VERSION ""

NS_ :

BS_:

BU_: TCU_TORQUE_CONVERTER HYDRONIC AFSS LOGBOX TCU_GWS500 TCU_RET DIAG_TOOL CTIS BC ECM_0x00 TCU ALTERNATOR CP6 CP10 _TESTER _TEMPLATE_RUx

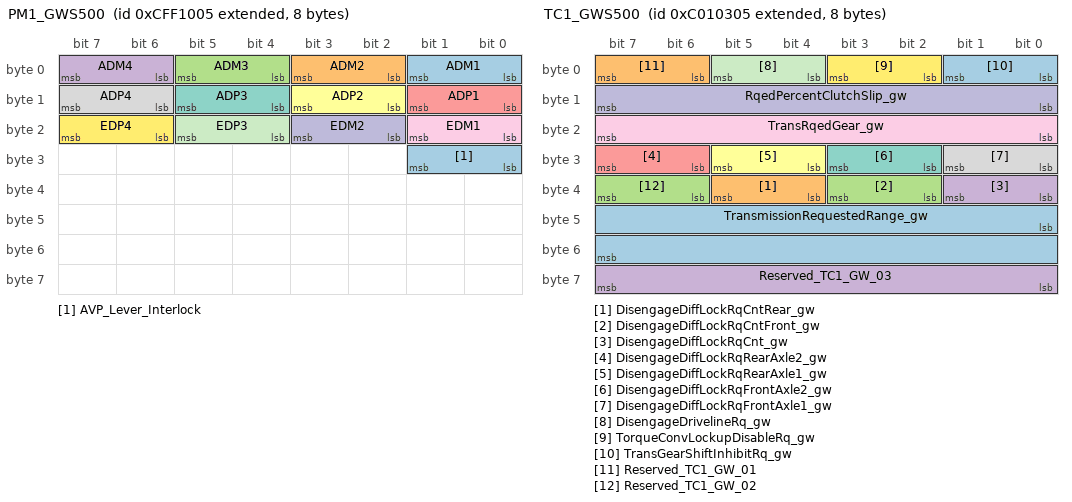
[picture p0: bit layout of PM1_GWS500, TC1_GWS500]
BO_ 2365526021 PM1_GWS500: 8 TCU_GWS500
 SG_ ADM1 : 0|2@1+ (1,0) [0|3] "-"  LOGBOX,TCU
 SG_ ADM2 : 2|2@1+ (1,0) [0|3] "-"  LOGBOX,TCU
 SG_ ADM3 : 4|2@1+ (1,0) [0|3] "-"  LOGBOX,TCU
 SG_ ADM4 : 6|2@1+ (1,0) [0|3] "-"  LOGBOX,TCU
 SG_ ADP1 : 8|2@1+ (1,0) [0|3] "-"  LOGBOX,TCU
 SG_ ADP2 : 10|2@1+ (1,0) [0|3] "-"  LOGBOX,TCU
 SG_ ADP3 : 12|2@1+ (1,0) [0|3] "-"  LOGBOX,TCU
 SG_ ADP4 : 14|2@1+ (1,0) [0|3] "-"  LOGBOX,TCU
 SG_ EDM1 : 16|2@1+ (1,0) [0|3] "-"  LOGBOX,TCU
 SG_ EDM2 : 18|2@1+ (1,0) [0|3] "-"  LOGBOX,TCU
 SG_ EDP3 : 20|2@1+ (1,0) [0|3] "-"  LOGBOX,TCU
 SG_ EDP4 : 22|2@1+ (1,0) [0|3] "-"  LOGBOX,TCU
 SG_ AVP_Lever_Interlock : 24|2@1+ (1,0) [0|3] "-"  CP6,CP10,LOGBOX,TCU

BO_ 2348876549 TC1_GWS500: 8 TCU_GWS500
 SG_ TransmissionRequestedRange_gw : 40|16@1+ (1,0) [0|65536] "-"  LOGBOX,TCU
 SG_ DisengageDiffLockRqCntRear_gw : 36|2@1+ (1,0) [0|3] "-"  LOGBOX,TCU
 SG_ DisengageDiffLockRqCntFront_gw : 34|2@1+ (1,0) [0|3] "-"  LOGBOX,TCU
 SG_ DisengageDiffLockRqCnt_gw : 32|2@1+ (1,0) [0|3] "-"  LOGBOX,TCU
 SG_ DisengageDiffLockRqRearAxle2_gw : 30|2@1+ (1,0) [0|3] "-"  LOGBOX,TCU
 SG_ DisengageDiffLockRqRearAxle1_gw : 28|2@1+ (1,0) [0|3] "-"  LOGBOX,TCU
 SG_ DisengageDiffLockRqFrontAxle2_gw : 26|2@1+ (1,0) [0|3] "-"  LOGBOX,TCU
 SG_ DisengageDiffLockRqFrontAxle1_gw : 24|2@1+ (1,0) [0|3] "-"  LOGBOX,TCU
 SG_ TransRqedGear_gw : 16|8@1+ (1,-125) [-125|125] "-"  LOGBOX,TCU,CP6,CP10
 SG_ RqedPercentClutchSlip_gw : 8|8@1+ (0.4,0) [0|100] "%"  LOGBOX,TCU
 SG_ DisengageDrivelineRq_gw : 4|2@1+ (1,0) [0|3] "-"  LOGBOX,TCU
 SG_ TorqueConvLockupDisableRq_gw : 2|2@1+ (1,0) [0|3] "-"  LOGBOX,TCU
 SG_ TransGearShiftInhibitRq_gw : 0|2@1+ (1,0) [0|3] "-"  LOGBOX,TCU
 SG_ Reserved_TC1_GW_01 : 6|2@1+ (1,0) [0|0] "-"  LOGBOX,TCU
 SG_ Reserved_TC1_GW_02 : 38|2@1+ (1,0) [0|0] "-"  LOGBOX,TCU
 SG_ Reserved_TC1_GW_03 : 56|8@1+ (1,0) [0|0] "-"  LOGBOX,TCU

BO_ 2348876577 TC1_BODY: 8 BC
 SG_ TransMode4_bc : 46|2@1+ (1,0) [0|3] "-"  LOGBOX,TCU
 SG_ TransMode3_bc : 44|2@1+ (1,0) [0|3] "-"  LOGBOX,TCU
 SG_ TransMode2_bc : 42|2@1+ (1,0) [0|3] "-"  LOGBOX,TCU
 SG_ TransMode1_bc : 40|2@1+ (1,0) [0|3] "-"  LOGBOX,TCU
 SG_ DisengageDiffLockRqCntRear_bc : 36|2@1+ (1,0) [0|3] "-"  LOGBOX,TCU
 SG_ DisengageDiffLockRqCntFront_bc : 34|2@1+ (1,0) [0|3] "-"  LOGBOX,TCU
 SG_ DisengageDiffLockRqCnt_bc : 32|2@1+ (1,0) [0|3] "-"  LOGBOX,TCU
 SG_ DisengageDiffLockRqRearAxle2_bc : 30|2@1+ (1,0) [0|3] "-"  LOGBOX,TCU
 SG_ DisengageDiffLockRqRearAxle1_bc : 28|2@1+ (1,0) [0|3] "-"  LOGBOX,TCU
 SG_ DisengageDiffLockRqFrontAxle2_bc : 26|2@1+ (1,0) [0|3] "-"  LOGBOX,TCU
 SG_ DisengageDiffLockRqFrontAxle1_bc : 24|2@1+ (1,0) [0|3] "-"  LOGBOX,TCU
 SG_ TransRqedGear_bc : 16|8@1+ (1,-125) [-125|125] "-"  LOGBOX,TCU
 SG_ RqedPercentClutchSlip_bc : 8|8@1+ (0.4,0) [0|100] "%"  LOGBOX,TCU
 SG_ DisengageDrivelineRq_bc : 4|2@1+ (1,0) [0|3] "-"  LOGBOX,TCU
 SG_ TorqueConvLockupDisableRq_bc : 2|2@1+ (1,0) [0|3] "-"  LOGBOX,TCU
 SG_ TransGearShiftInhibitRq_bc : 0|2@1+ (1,0) [0|3] "-"  LOGBOX,TCU
 SG_ Reserved_TC1_BC_01 : 6|2@1+ (1,0) [0|0] "-"  LOGBOX,TCU
 SG_ Reserved_TC1_BC_02 : 38|2@1+ (1,0) [0|0] "-"  LOGBOX,TCU
 SG_ Reserved_TC1_BC_03 : 48|6@1+ (1,0) [0|0] "-"  LOGBOX,TCU
 SG_ TransmissionShift : 54|2@1+ (1,0) [0|0] "-"  LOGBOX,TCU
 SG_ Reserved_TC1_BC_04 : 56|8@1+ (1,0) [0|0] "-"  LOGBOX,TCU

BO_ 2566803994 ALT_CURRENT: 8 ALTERNATOR
 SG_ Alt_Current : 0|16@1+ (0.05,-1600) [-1600|1600] "A"  LOGBOX

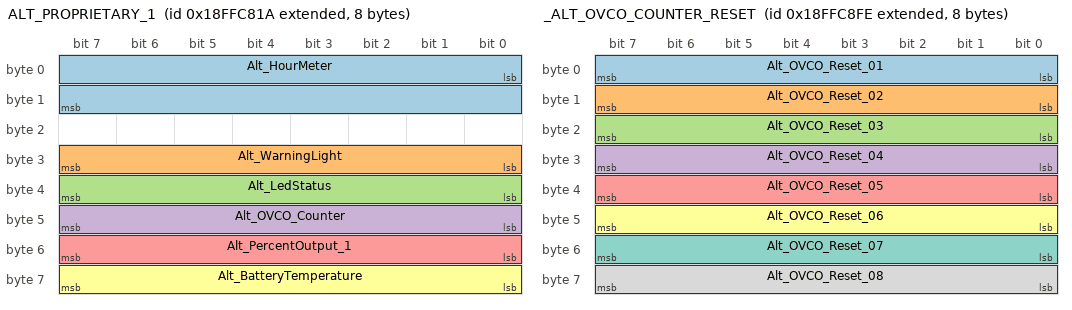
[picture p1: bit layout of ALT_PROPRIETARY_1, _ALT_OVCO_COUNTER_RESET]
BO_ 2566899738 ALT_PROPRIETARY_1: 8 ALTERNATOR
 SG_ Alt_HourMeter : 0|16@1+ (1,-32127) [-32127|33408] "h"  BC,LOGBOX
 SG_ Alt_WarningLight : 24|8@1+ (1,0) [252|253] "-"  BC,LOGBOX
 SG_ Alt_LedStatus : 32|8@1+ (1,0) [1|4] "-"  BC,LOGBOX
 SG_ Alt_OVCO_Counter : 40|8@1+ (1,0) [0|255] "-"  BC,LOGBOX
 SG_ Alt_PercentOutput_1 : 48|8@1+ (1,0) [0|100] "%"  BC,LOGBOX
 SG_ Alt_BatteryTemperature : 56|8@1+ (1,-40) [-40|210] "°C"  BC,LOGBOX

BO_ 2566837530 ALT_SPEED: 8 ALTERNATOR
 SG_ Alt_Speed_1 : 0|16@1+ (0.5,0) [0|32000] "rpm"  BC,LOGBOX

BO_ 2566899966 _ALT_OVCO_COUNTER_RESET: 8 _TESTER
 SG_ Alt_OVCO_Reset_01 : 0|8@1+ (1,0) [26|26] "-"  ALTERNATOR,LOGBOX
 SG_ Alt_OVCO_Reset_02 : 8|8@1+ (1,0) [43|43] "-"  ALTERNATOR,LOGBOX
 SG_ Alt_OVCO_Reset_03 : 16|8@1+ (1,0) [0|255] "-"  ALTERNATOR,LOGBOX
 SG_ Alt_OVCO_Reset_04 : 24|8@1+ (1,0) [0|255] "-"  ALTERNATOR,LOGBOX
 SG_ Alt_OVCO_Reset_05 : 32|8@1+ (1,0) [0|255] "-"  ALTERNATOR,LOGBOX
 SG_ Alt_OVCO_Reset_06 : 40|8@1+ (1,0) [255|255] "-"  ALTERNATOR,LOGBOX
 SG_ Alt_OVCO_Reset_07 : 48|8@1+ (1,0) [255|255] "-"  ALTERNATOR,LOGBOX
 SG_ Alt_OVCO_Reset_08 : 56|8@1+ (1,0) [255|255] "-"  ALTERNATOR,LOGBOX

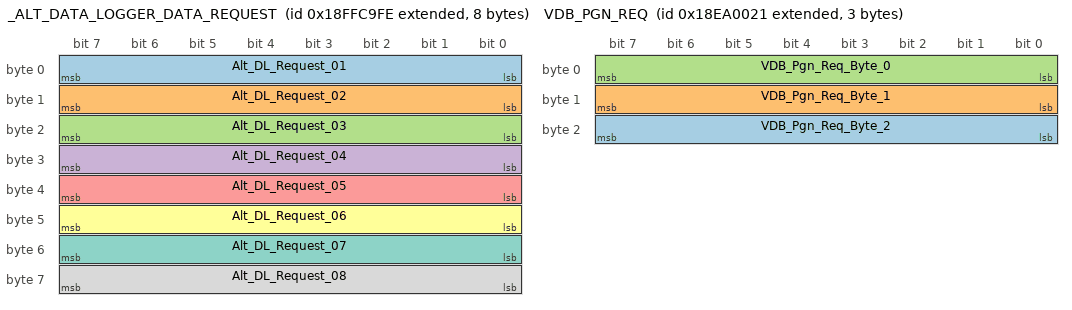
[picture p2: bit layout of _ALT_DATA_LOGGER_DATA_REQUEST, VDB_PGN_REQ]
BO_ 2566900222 _ALT_DATA_LOGGER_DATA_REQUEST: 8 _TESTER
 SG_ Alt_DL_Request_01 : 0|8@1+ (1,0) [26|26] "-"  ALTERNATOR,LOGBOX
 SG_ Alt_DL_Request_02 : 8|8@1+ (1,0) [43|43] "-"  ALTERNATOR,LOGBOX
 SG_ Alt_DL_Request_03 : 16|8@1+ (1,0) [0|255] "-"  ALTERNATOR,LOGBOX
 SG_ Alt_DL_Request_04 : 24|8@1+ (1,0) [0|255] "-"  ALTERNATOR,LOGBOX
 SG_ Alt_DL_Request_05 : 32|8@1+ (1,0) [0|255] "-"  ALTERNATOR,LOGBOX
 SG_ Alt_DL_Request_06 : 40|8@1+ (1,0) [255|255] "-"  ALTERNATOR,LOGBOX
 SG_ Alt_DL_Request_07 : 48|8@1+ (1,0) [255|255] "-"  ALTERNATOR,LOGBOX
 SG_ Alt_DL_Request_08 : 56|8@1+ (1,0) [255|255] "-"  ALTERNATOR,LOGBOX

BO_ 2566900723 ALT_VOLTAGE_REQUEST: 8 BC
 SG_ Alt_Set_Point_Request : 48|16@1+ (0.05,0) [0|32] "-"  ALTERNATOR,LOGBOX

BO_ 2565472289 VDB_PGN_REQ: 3 BC
 SG_ VDB_Pgn_Req_Byte_2 : 16|8@1+ (1,0) [0|255] "-"  LOGBOX,ECM_0x00
 SG_ VDB_Pgn_Req_Byte_1 : 8|8@1+ (1,0) [0|255] "-"  LOGBOX,ECM_0x00
 SG_ VDB_Pgn_Req_Byte_0 : 0|8@1+ (1,0) [0|255] "-"  LOGBOX,ECM_0x00

BO_ 2633922849 TP2_BODY: 8 BC
 SG_ Selected_Load_Mode_TP2_BODY : 56|3@1+ (1,0) [0|7] "-"  CTIS,LOGBOX
 SG_ Selected_Terrain_Mode_TP2_BODY : 48|3@1+ (1,0) [0|7] "-"  CTIS,LOGBOX

BO_ 2633922593 TP1_BODY: 8 BC
 SG_ TirePressCheckInterval_TP1_BODY : 0|8@1+ (1,0) [0|250] "-"  CTIS,LOGBOX

BO_ 2564489201 DIAG_REQ: 8 DIAG_TOOL
 SG_ DIAG_PHYS_REQUEST_DATA : 0|64@1+ (1,0) [0|0] "-"  LOGBOX,TCU

BO_ 2566841600 HOURS: 8 ECM_0x00
 SG_ EngTotalRevolutions : 32|32@1+ (1000,0) [0|4211081215000] "rpm"  BC,LOGBOX
 SG_ EngTotalHoursOfOperation : 0|32@1+ (0.05,0) [0|210554060.75] "hr"  BC,LOGBOX,CP10,CP6

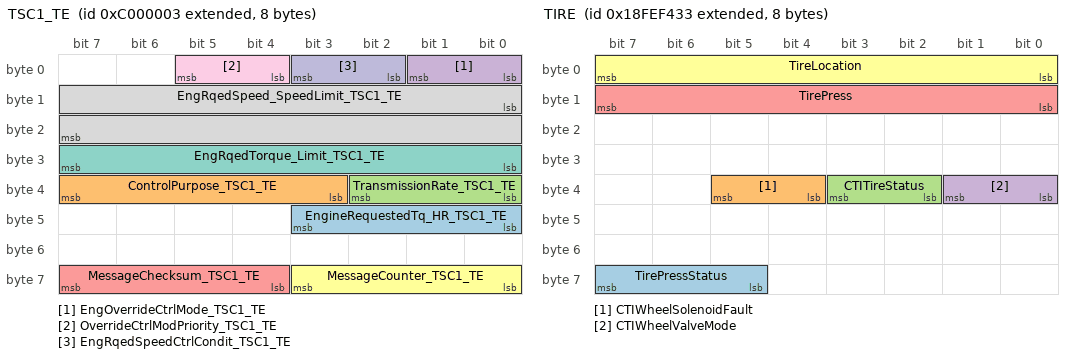
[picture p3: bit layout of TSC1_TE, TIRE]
BO_ 2348810243 TSC1_TE: 8 TCU
 SG_ EngineRequestedTq_HR_TSC1_TE : 40|4@1+ (1,0) [0|15] "-"  LOGBOX
 SG_ ControlPurpose_TSC1_TE : 35|5@1+ (1,0) [0|31] "-"  LOGBOX
 SG_ TransmissionRate_TSC1_TE : 32|3@1+ (1,0) [0|7] "-"  LOGBOX
 SG_ EngOverrideCtrlMode_TSC1_TE : 0|2@1+ (1,0) [0|3] "-"  LOGBOX
 SG_ MessageChecksum_TSC1_TE : 60|4@1+ (1,0) [0|15] "unit"  LOGBOX,ECM_0x00
 SG_ MessageCounter_TSC1_TE : 56|4@1+ (1,0) [0|15] "-"  LOGBOX
 SG_ EngRqedTorque_Limit_TSC1_TE : 24|8@1+ (1,-125) [-125|125] "%"  LOGBOX,ECM_0x00
 SG_ EngRqedSpeed_SpeedLimit_TSC1_TE : 8|16@1+ (0.125,0) [0|8031.875] "rpm"  LOGBOX,ECM_0x00
 SG_ OverrideCtrlModPriority_TSC1_TE : 4|2@1+ (1,0) [0|3] "-"  LOGBOX,ECM_0x00
 SG_ EngRqedSpeedCtrlCondit_TSC1_TE : 2|2@1+ (1,0) [0|3] "-"  LOGBOX,ECM_0x00

BO_ 2633923123 TP3_CTIS: 8 CTIS
 SG_ Current_Load_Mode : 56|3@1+ (1,0) [0|7] "-"  BC,LOGBOX
 SG_ Current_Terrain_Mode : 48|3@1+ (1,0) [0|7] "-"  BC,LOGBOX

BO_ 2633922867 TP2_CTIS: 8 CTIS
 SG_ Selected_Load_Mode_TP2 : 56|3@1+ (1,0) [0|7] "-"  BC,LOGBOX
 SG_ Selected_Terrain_Mode_TP2 : 48|3@1+ (1,0) [0|7] "-"  BC,LOGBOX

BO_ 2633922611 TP1_CTIS: 8 CTIS
 SG_ CTISProcessMode : 8|4@1+ (1,0) [0|15] "-"  BC,LOGBOX
 SG_ TirePressCheckInterval_TP1 : 0|8@1+ (1,0) [0|250] "-"  BC,LOGBOX

BO_ 2566845491 TIRE: 8 CTIS
 SG_ TirePressStatus : 61|3@1+ (1,0) [0|7] "-"  LOGBOX
 SG_ CTIWheelSolenoidFault : 36|2@1+ (1,0) [0|3] "-"  LOGBOX
 SG_ CTITireStatus : 34|2@1+ (1,0) [0|3] "-"  LOGBOX
 SG_ CTIWheelValveMode : 32|2@1+ (1,0) [0|3] "-"  LOGBOX
 SG_ TirePress : 8|8@1+ (5,0) [0|1250] "kPa"  LOGBOX
 SG_ TireLocation : 0|8@1+ (1,0) [0|255] "-"  LOGBOX

BO_ 2365484270 TCO1: 8 BC
 SG_ TachographVehicleSpeed : 48|16@1+ (0.00390625,0) [0|250.996] "km/h"  CP6,CP10,LOGBOX,ECM_0x00
 SG_ TachographOutputShaftSpeed : 32|16@1+ (0.125,0) [0|8031.875] "rpm"  LOGBOX

BO_ 2566840835 TCFG: 16 TCU
 SG_ TransGearRatio_6 : 112|16@1+ (0.001,0) [0|64.255] "-"  LOGBOX
 SG_ TransGearRatio_5 : 96|16@1+ (0.001,0) [0|64.255] "-"  LOGBOX
 SG_ TransGearRatio_4 : 80|16@1+ (0.001,0) [0|64.255] "-"  LOGBOX
 SG_ TransGearRatio_3 : 64|16@1+ (0.001,0) [0|64.255] "-"  LOGBOX
 SG_ TransGearRatio_2 : 48|16@1+ (0.001,0) [0|64.255] "-"  LOGBOX
 SG_ TransGearRatio_1 : 32|16@1+ (0.001,0) [0|64.255] "-"  LOGBOX
 SG_ TransGearRatio_0 : 16|16@1+ (0.001,0) [0|64.255] "-"  LOGBOX
 SG_ NumberOfForwardGearRatios : 8|8@1+ (1,0) [0|250] "-"  LOGBOX
 SG_ NumberOfReverseGearRatios : 0|8@1+ (1,0) [0|250] "-"  LOGBOX

BO_ 2566847248 RF: 8 TCU_RET
 SG_ HydRetarderOilTemp : 8|8@1+ (1,-40) [-40|210] "°C"  BC,LOGBOX
 SG_ HydRetarderPress : 0|8@1+ (16,0) [0|4000] "kPa"  LOGBOX

BO_ 2566840592 RC: 19 TCU_RET
 SG_ PercentTorqueAtPeakTorquePoint5 : 144|8@1+ (1,-125) [-125|125] "%"  LOGBOX
 SG_ ReferenceRetarderTorque : 128|16@1+ (1,0) [0|64255] "Nm"  LOGBOX
 SG_ RetarderSpeedAtPeakTorquePoint5 : 112|16@1+ (0.125,0) [0|8031.875] "rpm"  LOGBOX
 SG_ PercentTorqueAtPoint4 : 104|8@1+ (1,-125) [-125|125] "%"  LOGBOX
 SG_ RetarderSpeedAtPoint4 : 88|16@1+ (0.125,0) [0|8031.875] "rpm"  LOGBOX
 SG_ PercentTorqueAtPoint3 : 80|8@1+ (1,-125) [-125|125] "%"  LOGBOX
 SG_ RetarderSpeedAtPoint3 : 64|16@1+ (0.125,0) [0|8031.875] "rpm"  LOGBOX
 SG_ PercentTorqueAtMaxSpeedPoint2 : 56|8@1+ (1,-125) [-125|125] "%"  LOGBOX
 SG_ MaxRetarderSpeedPoint2 : 40|16@1+ (0.125,0) [0|8031.875] "rpm"  LOGBOX
 SG_ PercentTorqueAtIdlePoint1 : 32|8@1+ (1,-125) [-125|125] "%"  LOGBOX
 SG_ RetarderSpeedAtIdlePoint1 : 16|16@1+ (0.125,0) [0|8031.875] "rpm"  LOGBOX
 SG_ RetarderCtrlMethod : 8|8@1+ (1,0) [0|250] "steps"  LOGBOX
 SG_ RetarderLocation : 4|4@1+ (1,0) [0|15] "-"  LOGBOX
 SG_ RetarderType : 0|4@1+ (1,0) [0|15] "-"  LOGBOX

BO_ 2566844928 LFE1: 8 ECM_0x00
 SG_ EngInstantaneousFuelEconomy : 16|16@1+ (0.001953125,0) [0|125.5] "km/L"  BC,LOGBOX
 SG_ EngFuelRate : 0|16@1+ (0.05,0) [0|3212.75] "L/h"  BC,LOGBOX

BO_ 2566842624 LFC: 8 ECM_0x00
 SG_ EngTotalFuelUsed : 32|32@1+ (0.5,0) [0|2105540607.5] "L"  LOGBOX

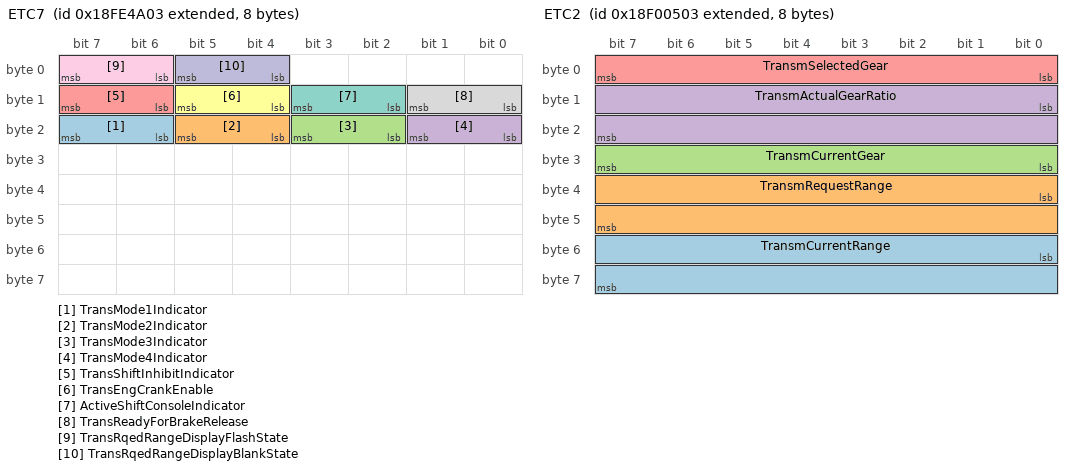
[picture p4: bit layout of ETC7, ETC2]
BO_ 2566801923 ETC7: 8 TCU
 SG_ TransMode1Indicator : 22|2@1+ (1,0) [0|3] "-"  BC,LOGBOX
 SG_ TransMode2Indicator : 20|2@1+ (1,0) [0|3] "-"  BC,LOGBOX
 SG_ TransMode3Indicator : 18|2@1+ (1,0) [0|3] "-"  BC,LOGBOX
 SG_ TransMode4Indicator : 16|2@1+ (1,0) [0|3] "-"  BC,LOGBOX
 SG_ TransShiftInhibitIndicator : 14|2@1+ (1,0) [0|3] "-"  BC,LOGBOX
 SG_ TransEngCrankEnable : 12|2@1+ (1,0) [0|3] "-"  BC,LOGBOX
 SG_ ActiveShiftConsoleIndicator : 10|2@1+ (1,0) [0|3] "-"  BC,LOGBOX
 SG_ TransReadyForBrakeRelease : 8|2@1+ (1,0) [0|3] "-"  BC,LOGBOX
 SG_ TransRqedRangeDisplayFlashState : 6|2@1+ (1,0) [0|3] "-"  BC,LOGBOX
 SG_ TransRqedRangeDisplayBlankState : 4|2@1+ (1,0) [0|3] "-"  BC,LOGBOX

BO_ 2565866755 ETC2: 8 TCU
 SG_ TransmCurrentRange : 48|16@1+ (1,0) [0|255] "-"  BC,LOGBOX
 SG_ TransmRequestRange : 32|16@1+ (1,0) [0|255] "-"  BC,LOGBOX
 SG_ TransmCurrentGear : 24|8@1+ (1,-125) [-125|125] "-"  BC,CP6,CP10,LOGBOX,ECM_0x00
 SG_ TransmActualGearRatio : 8|16@1+ (0.001,0) [0|64.255] "-"  BC,LOGBOX,ECM_0x00
 SG_ TransmSelectedGear : 0|8@1+ (1,-125) [-125|125] "-"  BC,LOGBOX,ECM_0x00

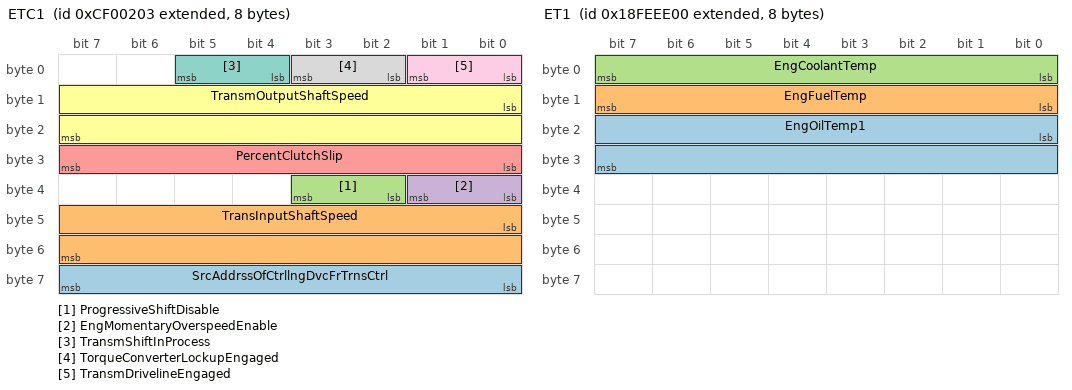
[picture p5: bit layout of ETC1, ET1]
BO_ 2364539395 ETC1: 8 TCU
 SG_ SrcAddrssOfCtrllngDvcFrTrnsCtrl : 56|8@1+ (1,0) [0|255] "-"  BC,LOGBOX
 SG_ TransInputShaftSpeed : 40|16@1+ (0.125,0) [0|8031.875] "rpm"  BC,LOGBOX
 SG_ ProgressiveShiftDisable : 34|2@1+ (1,0) [0|3] "-"  BC,LOGBOX
 SG_ EngMomentaryOverspeedEnable : 32|2@1+ (1,0) [0|3] "-"  BC,LOGBOX,ECM_0x00
 SG_ PercentClutchSlip : 24|8@1+ (0.4,0) [0|100] "%"  BC,LOGBOX
 SG_ TransmOutputShaftSpeed : 8|16@1+ (0.125,0) [0|8031.875] "rpm"  BC,LOGBOX,ECM_0x00
 SG_ TransmShiftInProcess : 4|2@1+ (1,0) [0|3] "-"  BC,LOGBOX,ECM_0x00
 SG_ TorqueConverterLockupEngaged : 2|2@1+ (1,0) [0|3] "-"  BC,LOGBOX,ECM_0x00
 SG_ TransmDrivelineEngaged : 0|2@1+ (1,0) [0|3] "-"  BC,LOGBOX,ECM_0x00

BO_ 2566843904 ET1: 8 ECM_0x00
 SG_ EngOilTemp1 : 16|16@1+ (0.03125,-273) [-273|1735] "°C"  CP6,CP10,LOGBOX
 SG_ EngFuelTemp : 8|8@1+ (1,-40) [-40|210] "°C"  CP6,CP10,BC,LOGBOX
 SG_ EngCoolantTemp : 0|8@1+ (1,-40) [-40|210] "°C"  BC,LOGBOX,TCU,CP6,CP10

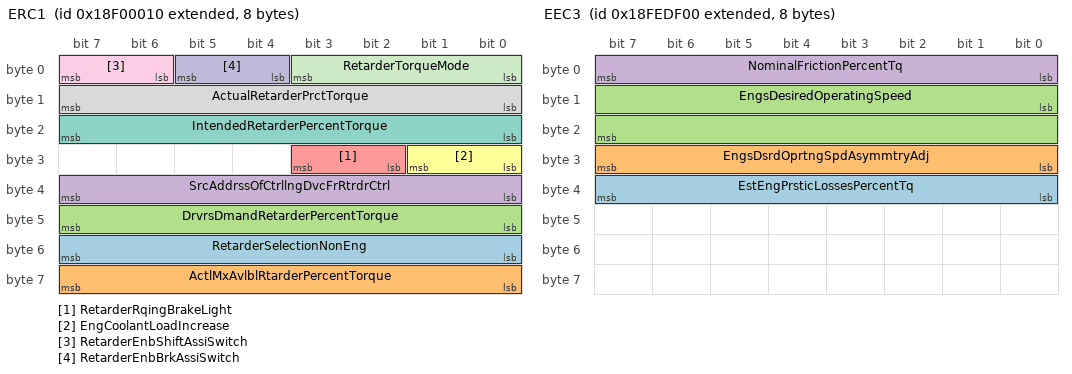
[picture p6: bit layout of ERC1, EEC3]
BO_ 2565865488 ERC1: 8 TCU_RET
 SG_ RetarderSelectionNonEng : 48|8@1+ (0.4,0) [0|100] "%"  BC,LOGBOX
 SG_ ActlMxAvlblRtarderPercentTorque : 56|8@1+ (1,-125) [-125|125] "%"  BC,LOGBOX
 SG_ DrvrsDmandRetarderPercentTorque : 40|8@1+ (1,-125) [-125|125] "%"  BC,LOGBOX
 SG_ SrcAddrssOfCtrllngDvcFrRtrdrCtrl : 32|8@1+ (1,0) [0|255] "-"  BC,LOGBOX
 SG_ RetarderRqingBrakeLight : 26|2@1+ (1,0) [0|3] "-"  BC,LOGBOX,TCU
 SG_ EngCoolantLoadIncrease : 24|2@1+ (1,0) [0|3] "-"  BC,LOGBOX
 SG_ IntendedRetarderPercentTorque : 16|8@1+ (1,-125) [-125|125] "%"  BC,LOGBOX
 SG_ ActualRetarderPrctTorque : 8|8@1+ (1,-125) [-125|125] "%"  BC,LOGBOX,TCU
 SG_ RetarderEnbShiftAssiSwitch : 6|2@1+ (1,0) [0|3] "-"  BC,LOGBOX,TCU
 SG_ RetarderEnbBrkAssiSwitch : 4|2@1+ (1,0) [0|3] "-"  BC,LOGBOX,TCU
 SG_ RetarderTorqueMode : 0|4@1+ (1,0) [0|15] "-"  BC,LOGBOX

BO_ 2566844160 EFL_P1: 8 ECM_0x00
 SG_ EngOilPress : 24|8@1+ (4,0) [0|1000] "kPa"  BC,LOGBOX,CP10,CP6

BO_ 2566840064 EEC3: 8 ECM_0x00
 SG_ EstEngPrsticLossesPercentTq : 32|8@1+ (1,-125) [0|125] "%"  TCU,LOGBOX
 SG_ EngsDsrdOprtngSpdAsymmtryAdj : 24|8@1+ (1,0) [0|250] "-"  TCU,LOGBOX
 SG_ EngsDesiredOperatingSpeed : 8|16@1+ (0.125,0) [0|8031.875] "rpm"  TCU,LOGBOX
 SG_ NominalFrictionPercentTq : 0|8@1+ (1,-125) [-125|125] "%"  LOGBOX,TCU

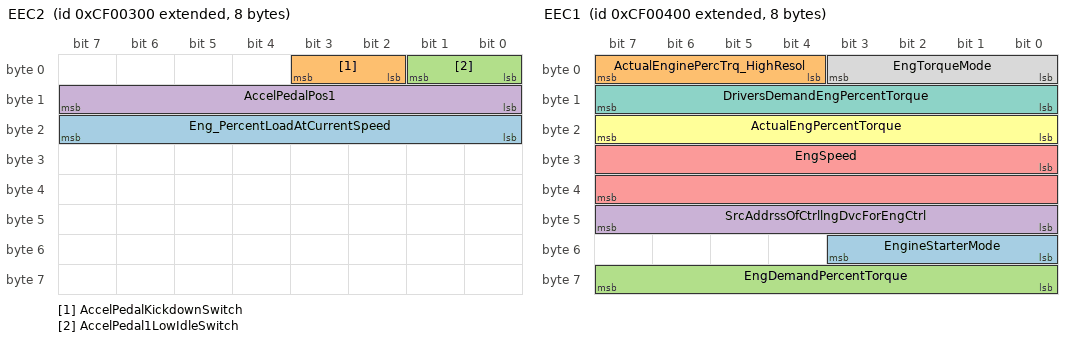
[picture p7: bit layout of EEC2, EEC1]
BO_ 2364539648 EEC2: 8 ECM_0x00
 SG_ Eng_PercentLoadAtCurrentSpeed : 16|8@1+ (1,0) [0|125] "%"  LOGBOX
 SG_ AccelPedalKickdownSwitch : 2|2@1+ (1,0) [0|3] "-"  BC,LOGBOX,TCU
 SG_ AccelPedal1LowIdleSwitch : 0|2@1+ (1,0) [0|3] "-"  BC,LOGBOX,TCU
 SG_ AccelPedalPos1 : 8|8@1+ (0.4,0) [0|100] "%"  BC,LOGBOX,TCU

BO_ 2364539904 EEC1: 8 ECM_0x00
 SG_ EngineStarterMode : 48|4@1+ (1,0) [0|15] "-"  LOGBOX
 SG_ ActualEnginePercTrq_HighResol : 4|4@1+ (0.125,0) [0|0.875] "%"  LOGBOX
 SG_ EngDemandPercentTorque : 56|8@1+ (1,-125) [-125|125] "%"  LOGBOX,TCU
 SG_ SrcAddrssOfCtrllngDvcForEngCtrl : 40|8@1+ (1,0) [0|255] "-"  LOGBOX,TCU
 SG_ EngSpeed : 24|16@1+ (0.125,0) [0|8031.875] "rpm"  CP6,CP10,BC,LOGBOX,TCU
 SG_ ActualEngPercentTorque : 16|8@1+ (1,-125) [-125|125] "%"  LOGBOX,TCU
 SG_ DriversDemandEngPercentTorque : 8|8@1+ (1,-125) [-125|125] "%"  LOGBOX,TCU
 SG_ EngTorqueMode : 0|4@1+ (1,0) [0|15] "-"  LOGBOX,TCU

BO_ 2566841088 _EC1: 39 ECM_0x00
 SG_ SupportTSC1CtrlPurposeGroup4Of4 : 304|8@1+ (1,0) [0|255] "-"  LOGBOX,BC
 SG_ SupportVariableRateTSC1Message : 272|8@1+ (1,0) [0|255] "-"  LOGBOX,BC
 SG_ SupportTSC1CtrlPurposeGroup3Of4 : 296|8@1+ (1,0) [0|255] "-"  LOGBOX,BC
 SG_ SupportTSC1CtrlPurposeGroup2Of4 : 288|8@1+ (1,0) [0|255] "-"  LOGBOX,BC
 SG_ SupportTSC1CtrlPurposeGroup1Of4 : 280|8@1+ (1,0) [0|255] "-"  LOGBOX,BC
 SG_ EngDefaultTorqueLimit : 256|16@1+ (1,0) [0|64255] "Nm"  LOGBOX,BC
 SG_ EngMomentOfInertia : 240|16@1+ (0.004,0) [0|257.02] "kg-m²"  LOGBOX,BC
 SG_ EngExRngRqdSpdCtrlRngUpperLimit : 224|16@1+ (0.125,0) [0|8031.875] "rpm"  LOGBOX,BC
 SG_ EngRqdTorqueCtrlRangeUpperLimit : 216|8@1+ (1,-125) [-125|125] "%"  LOGBOX,BC
 SG_ EngRqdTorqueCtrlRangeLowerLimit : 208|8@1+ (1,-125) [-125|125] "%"  LOGBOX,BC
 SG_ EngRqedSpeedCtrlRangeUpperLimit : 200|8@1+ (10,0) [0|2500] "rpm"  LOGBOX,BC
 SG_ EngRqedSpeedCtrlRangeLowerLimit : 192|8@1+ (10,0) [0|2500] "rpm"  LOGBOX,BC
 SG_ EngMxMomentaryOverrideTimeLimit : 184|8@1+ (0.1,0) [0|25] "s"  LOGBOX,BC
 SG_ EngMxMmntaryOverrideSpeedPoint7 : 168|16@1+ (0.125,0) [0|8031.875] "rpm"  LOGBOX,BC
 SG_ EngReferenceTorque : 152|16@1+ (1,0) [0|64255] "Nm"  LOGBOX,BC,TCU
 SG_ EngSpeedAtHighIdlePoint6 : 120|16@1+ (0.125,0) [0|8031.875] "rpm"  LOGBOX,BC,TCU
 SG_ EngGainOfEndspeedGovernor : 136|16@1+ (0.00078125,0) [0|50.2] "%/rpm"  LOGBOX,BC
 SG_ EngPercentTorqueAtPoint5 : 112|8@1+ (1,-125) [-125|125] "%"  LOGBOX,BC,TCU
 SG_ EngSpeedAtPoint5 : 96|16@1+ (0.125,0) [0|8031.875] "rpm"  LOGBOX,BC,TCU
 SG_ EngPercentTorqueAtPoint4 : 88|8@1+ (1,-125) [-125|125] "%"  LOGBOX,BC,TCU
 SG_ EngSpeedAtPoint4 : 72|16@1+ (0.125,0) [0|8031.875] "rpm"  LOGBOX,BC,TCU
 SG_ EngPercentTorqueAtPoint3 : 64|8@1+ (1,-125) [-125|125] "%"  LOGBOX,BC,TCU
 SG_ EngSpeedAtPoint3 : 48|16@1+ (0.125,0) [0|8031.875] "rpm"  LOGBOX,BC,TCU
 SG_ EngPercentTorqueAtPoint2 : 40|8@1+ (1,-125) [-125|125] "%"  LOGBOX,BC,TCU
 SG_ EngSpeedAtPoint2 : 24|16@1+ (0.125,0) [0|8031.875] "rpm"  LOGBOX,BC,TCU
 SG_ EngPercentTorqueAtIdlePoint1 : 16|8@1+ (1,-125) [-125|125] "%"  LOGBOX,BC,TCU
 SG_ EngSpeedAtIdlePoint1 : 0|16@1+ (0.125,0) [0|8031.875] "rpm"  LOGBOX,BC,TCU

BO_ 2566834944 _DM2_ECM: 42 ECM_0x00
 SG_ MalfunctionIndicatorLampStatus : 6|2@1+ (1,0) [0|3] "-"  LOGBOX
 SG_ AmberWarningLampStatus : 2|2@1+ (1,0) [0|3] "-"  LOGBOX
 SG_ RedStopLampState : 4|2@1+ (1,0) [0|3] "-"  LOGBOX
 SG_ SPN9_Low : 272|16@1+ (1,0) [0|65536] "-"  LOGBOX
 SG_ SPN9_High : 293|3@1+ (1,0) [0|7] "-"  LOGBOX
 SG_ SPN8_Low : 240|16@1+ (1,0) [0|65536] "-"  LOGBOX
 SG_ SPN8_High : 261|3@1+ (1,0) [0|7] "-"  LOGBOX
 SG_ SPN7_Low : 208|16@1+ (1,0) [0|65536] "-"  LOGBOX
 SG_ SPN7_High : 229|3@1+ (1,0) [0|7] "-"  LOGBOX
 SG_ SPN6_Low : 176|16@1+ (1,0) [0|65536] "-"  LOGBOX
 SG_ SPN6_High : 197|3@1+ (1,0) [0|7] "-"  LOGBOX
 SG_ SPN5_Low : 144|16@1+ (1,0) [0|65536] "-"  LOGBOX
 SG_ SPN5_High : 165|3@1+ (1,0) [0|7] "-"  LOGBOX
 SG_ SPN4_Low : 112|16@1+ (1,0) [0|65536] "-"  LOGBOX
 SG_ SPN4_High : 133|3@1+ (1,0) [0|7] "-"  LOGBOX
 SG_ SPN3_Low : 80|16@1+ (1,0) [0|65536] "-"  LOGBOX
 SG_ SPN3_High : 101|3@1+ (1,0) [0|7] "-"  LOGBOX
 SG_ SPN2_Low : 48|16@1+ (1,0) [0|65536] "-"  LOGBOX
 SG_ SPN2_High : 69|3@1+ (1,0) [0|7] "-"  LOGBOX
 SG_ SPN1_Low : 16|16@1+ (1,0) [0|65536] "-"  LOGBOX
 SG_ SPN1_High : 37|3@1+ (1,0) [0|7] "-"  LOGBOX
 SG_ SPN10_Low : 304|16@1+ (1,0) [0|65536] "-"  LOGBOX
 SG_ SPN10_High : 325|3@1+ (1,0) [0|7] "-"  LOGBOX
 SG_ OccurrenceCount9 : 296|7@1+ (1,0) [0|127] "-"  LOGBOX
 SG_ OccurrenceCount8 : 264|7@1+ (1,0) [0|127] "-"  LOGBOX
 SG_ OccurrenceCount7 : 232|7@1+ (1,0) [0|127] "-"  LOGBOX
 SG_ OccurrenceCount6 : 200|7@1+ (1,0) [0|127] "-"  LOGBOX
 SG_ OccurrenceCount5 : 168|7@1+ (1,0) [0|127] "-"  LOGBOX
 SG_ OccurrenceCount4 : 136|7@1+ (1,0) [0|127] "-"  LOGBOX
 SG_ OccurrenceCount3 : 104|7@1+ (1,0) [0|127] "-"  LOGBOX
 SG_ OccurrenceCount2 : 72|7@1+ (1,0) [0|127] "-"  LOGBOX
 SG_ OccurrenceCount10 : 328|7@1+ (1,0) [0|127] "-"  LOGBOX
 SG_ OccurrenceCount1 : 40|7@1+ (1,0) [0|127] "-"  LOGBOX
 SG_ FailureModeIdentifier9 : 288|5@1+ (1,0) [0|31] "-"  LOGBOX
 SG_ FailureModeIdentifier8 : 256|5@1+ (1,0) [0|31] "-"  LOGBOX
 SG_ FailureModeIdentifier7 : 224|5@1+ (1,0) [0|31] "-"  LOGBOX
 SG_ FailureModeIdentifier6 : 192|5@1+ (1,0) [0|31] "-"  LOGBOX
 SG_ FailureModeIdentifier5 : 160|5@1+ (1,0) [0|31] "-"  LOGBOX
 SG_ FailureModeIdentifier4 : 128|5@1+ (1,0) [0|31] "-"  LOGBOX
 SG_ FailureModeIdentifier3 : 96|5@1+ (1,0) [0|31] "-"  LOGBOX
 SG_ FailureModeIdentifier2 : 64|5@1+ (1,0) [0|31] "-"  LOGBOX
 SG_ FailureModeIdentifier10 : 320|5@1+ (1,0) [0|31] "-"  LOGBOX
 SG_ FailureModeIdentifier1 : 32|5@1+ (1,0) [0|31] "-"  LOGBOX

BO_ 2566835456 _DM4_ECM: 42 ECM_0x00
 SG_ SPN9_Low : 272|16@1+ (1,0) [0|65536] "-"  LOGBOX
 SG_ SPN9_High : 293|3@1+ (1,0) [0|7] "-"  LOGBOX
 SG_ SPN8_Low : 240|16@1+ (1,0) [0|65536] "-"  LOGBOX
 SG_ SPN8_High : 261|3@1+ (1,0) [0|7] "-"  LOGBOX
 SG_ SPN7_Low : 208|16@1+ (1,0) [0|65536] "-"  LOGBOX
 SG_ SPN7_High : 229|3@1+ (1,0) [0|7] "-"  LOGBOX
 SG_ SPN6_Low : 176|16@1+ (1,0) [0|65536] "-"  LOGBOX
 SG_ SPN6_High : 197|3@1+ (1,0) [0|7] "-"  LOGBOX
 SG_ SPN5_Low : 144|16@1+ (1,0) [0|65536] "-"  LOGBOX
 SG_ SPN5_High : 165|3@1+ (1,0) [0|7] "-"  LOGBOX
 SG_ SPN4_Low : 112|16@1+ (1,0) [0|65536] "-"  LOGBOX
 SG_ SPN4_High : 133|3@1+ (1,0) [0|7] "-"  LOGBOX
 SG_ SPN3_Low : 80|16@1+ (1,0) [0|65536] "-"  LOGBOX
 SG_ SPN3_High : 101|3@1+ (1,0) [0|7] "-"  LOGBOX
 SG_ SPN2_Low : 48|16@1+ (1,0) [0|65536] "-"  LOGBOX
 SG_ SPN2_High : 69|3@1+ (1,0) [0|7] "-"  LOGBOX
 SG_ SPN1_Low : 16|16@1+ (1,0) [0|65536] "-"  LOGBOX
 SG_ SPN1_High : 37|3@1+ (1,0) [0|7] "-"  LOGBOX
 SG_ SPN10_Low : 304|16@1+ (1,0) [0|65536] "-"  LOGBOX
 SG_ SPN10_High : 325|3@1+ (1,0) [0|7] "-"  LOGBOX
 SG_ OccurrenceCount9 : 296|7@1+ (1,0) [0|127] "-"  LOGBOX
 SG_ OccurrenceCount8 : 264|7@1+ (1,0) [0|127] "-"  LOGBOX
 SG_ OccurrenceCount7 : 232|7@1+ (1,0) [0|127] "-"  LOGBOX
 SG_ OccurrenceCount6 : 200|7@1+ (1,0) [0|127] "-"  LOGBOX
 SG_ OccurrenceCount5 : 168|7@1+ (1,0) [0|127] "-"  LOGBOX
 SG_ OccurrenceCount4 : 136|7@1+ (1,0) [0|127] "-"  LOGBOX
 SG_ OccurrenceCount3 : 104|7@1+ (1,0) [0|127] "-"  LOGBOX
 SG_ OccurrenceCount2 : 72|7@1+ (1,0) [0|127] "-"  LOGBOX
 SG_ OccurrenceCount10 : 328|7@1+ (1,0) [0|127] "-"  LOGBOX
 SG_ OccurrenceCount1 : 40|7@1+ (1,0) [0|127] "-"  LOGBOX
 SG_ FailureModeIdentifier9 : 288|5@1+ (1,0) [0|31] "-"  LOGBOX
 SG_ FailureModeIdentifier8 : 256|5@1+ (1,0) [0|31] "-"  LOGBOX
 SG_ FailureModeIdentifier7 : 224|5@1+ (1,0) [0|31] "-"  LOGBOX
 SG_ FailureModeIdentifier6 : 192|5@1+ (1,0) [0|31] "-"  LOGBOX
 SG_ FailureModeIdentifier5 : 160|5@1+ (1,0) [0|31] "-"  LOGBOX
 SG_ FailureModeIdentifier4 : 128|5@1+ (1,0) [0|31] "-"  LOGBOX
 SG_ FailureModeIdentifier3 : 96|5@1+ (1,0) [0|31] "-"  LOGBOX
 SG_ FailureModeIdentifier2 : 64|5@1+ (1,0) [0|31] "-"  LOGBOX
 SG_ FailureModeIdentifier10 : 320|5@1+ (1,0) [0|31] "-"  LOGBOX
 SG_ FailureModeIdentifier1 : 32|5@1+ (1,0) [0|31] "-"  LOGBOX

BO_ 2566845696 AMB: 8 ECM_0x00
 SG_ BarometricPressure : 0|8@1+ (0.5,0) [0|125] "kPa"  LOGBOX,TCU

BO_ 2566845952 IC1: 8 ECM_0x00
 SG_ EngIntakeManifoldTemp : 16|8@1+ (1,-40) [-40|210] "°C"  LOGBOX
 SG_ EngIntakeManifoldPress : 8|8@1+ (2,0) [0|500] "kPa"  LOGBOX

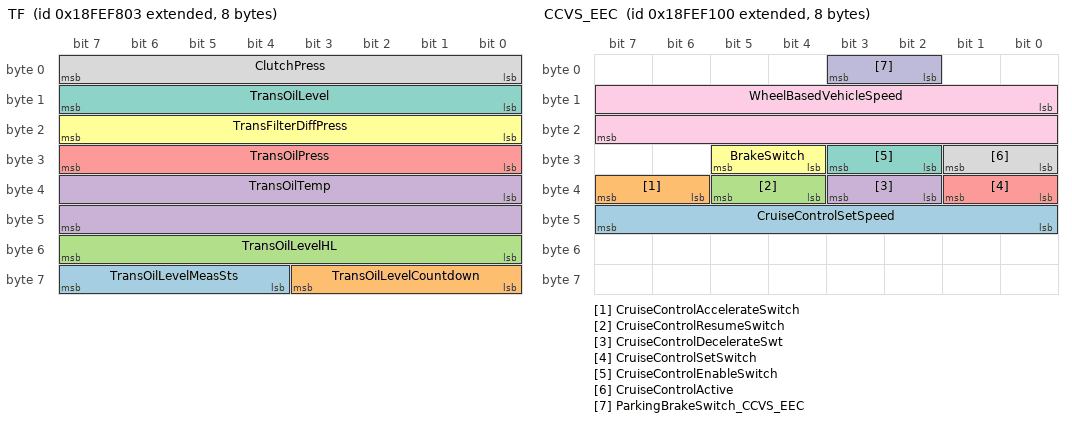
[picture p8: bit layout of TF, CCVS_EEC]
BO_ 2566846467 TF: 8 TCU
 SG_ TransOilLevelMeasSts : 60|4@1+ (1,0) [0|15] "-"  BC,LOGBOX
 SG_ TransOilLevelCountdown : 56|4@1+ (1,0) [0|15] "-"  BC,LOGBOX
 SG_ TransOilLevelHL : 48|8@1+ (0.5,-62.5) [-62.5|62.5] "l"  BC,LOGBOX
 SG_ TransOilTemp : 32|16@1+ (0.03125,-273) [-273|1735] "°C"  BC,CP6,CP10,LOGBOX
 SG_ TransOilPress : 24|8@1+ (16,0) [0|4000] "kPa"  BC,LOGBOX
 SG_ TransFilterDiffPress : 16|8@1+ (2,0) [0|500] "kPa"  BC,LOGBOX
 SG_ TransOilLevel : 8|8@1+ (0.4,0) [0|250] "%"  BC,LOGBOX
 SG_ ClutchPress : 0|8@1+ (16,0) [0|4000] "kPa"  BC,LOGBOX

BO_ 2566846208 VEP1: 8 ECM_0x00
 SG_ BatteryPotentialSwitched : 48|16@1+ (0.05,0) [0|3212.75] "V"  CP6,CP10,LOGBOX

BO_ 2566873377 BC2EDC2: 8 BC
 SG_ EngineShutdownSwitch : 34|2@1+ (1,0) [0|3] "-"  LOGBOX,ECM_0x00
 SG_ ParkingBrakeSwitch_BC2EDC2 : 12|2@1+ (1,0) [0|3] "-"  LOGBOX,ECM_0x00

BO_ 2566844672 CCVS_EEC: 8 ECM_0x00
 SG_ CruiseControlSetSpeed : 40|8@1+ (1,0) [0|250] "km/h/bit"  LOGBOX,TCU
 SG_ CruiseControlAccelerateSwitch : 38|2@1+ (1,0) [0|3] "-"  LOGBOX,TCU
 SG_ CruiseControlResumeSwitch : 36|2@1+ (1,0) [0|3] "-"  LOGBOX,TCU
 SG_ CruiseControlDecelerateSwt : 34|2@1+ (1,0) [0|3] "-"  LOGBOX,TCU
 SG_ CruiseControlSetSwitch : 32|2@1+ (1,0) [0|3] "-"  LOGBOX,TCU
 SG_ BrakeSwitch : 28|2@1+ (1,0) [0|3] "-"  BC,LOGBOX,TCU
 SG_ CruiseControlEnableSwitch : 26|2@1+ (1,0) [0|3] "-"  LOGBOX,TCU
 SG_ CruiseControlActive : 24|2@1+ (1,0) [0|3] "-"  LOGBOX,TCU
 SG_ WheelBasedVehicleSpeed : 8|16@1+ (0.0039,0) [0|251] "Km/h"  LOGBOX,TCU
 SG_ ParkingBrakeSwitch_CCVS_EEC : 2|2@1+ (1,0) [0|3] "-"  BC,LOGBOX,TCU

BO_ 2566848256 WFI: 8 ECM_0x00
 SG_ WaterInFuelIndicator : 0|2@1+ (1,0) [0|3] "-"  BC,LOGBOX

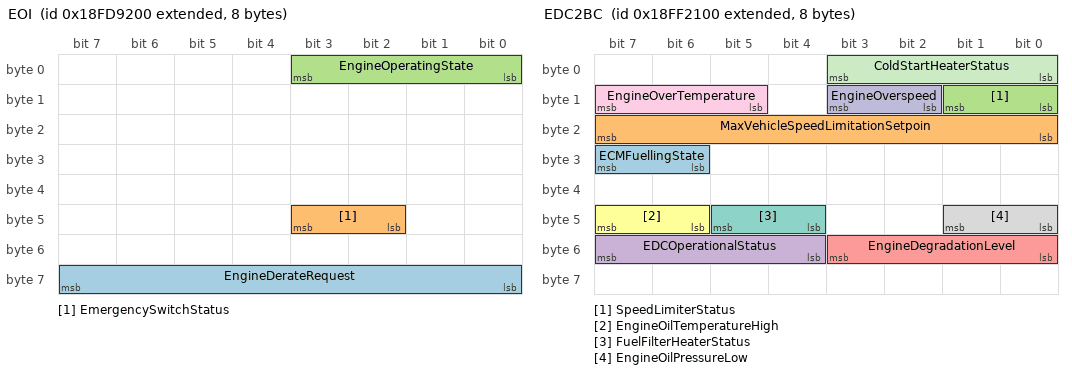
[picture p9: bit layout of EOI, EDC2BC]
BO_ 2566754816 EOI: 8 ECM_0x00
 SG_ EngineDerateRequest : 56|8@1+ (0.4,0) [0|250] "%"  BC,LOGBOX
 SG_ EmergencySwitchStatus : 42|2@1+ (1,0) [0|3] "-"  BC,LOGBOX
 SG_ EngineOperatingState : 0|4@1+ (1,0) [0|15] "-"  BC,LOGBOX

BO_ 2566841344 SHUTDN: 8 ECM_0x00
 SG_ EngProtectSystHasShutdownEngine : 32|2@1+ (1,0) [0|2] "-"  BC,LOGBOX
 SG_ WaitToStartLamp : 24|2@1+ (1,0) [0|1] "-"  BC,LOGBOX

BO_ 2566857216 ENG06: 8 ECM_0x00
 SG_ CloggedOilFilterStatus : 6|2@1+ (1,0) [0|3] "-"  LOGBOX
 SG_ CloggedFuelFilterStatus : 8|2@1+ (1,0) [0|3] "-"  LOGBOX

BO_ 2566856960 EDC2BC: 8 ECM_0x00
 SG_ ECMFuellingState : 30|2@1+ (1,0) [0|3] "-"  LOGBOX
 SG_ MaxVehicleSpeedLimitationSetpoin : 16|8@1+ (1,0) [0|250] "km/h"  LOGBOX
 SG_ SpeedLimiterStatus : 8|2@1+ (1,0) [0|3] "-"  LOGBOX
 SG_ EDCOperationalStatus : 52|4@1+ (1,0) [0|3] "-"  LOGBOX
 SG_ EngineDegradationLevel : 48|4@1+ (1,0) [0|15] "-"  LOGBOX
 SG_ EngineOilTemperatureHigh : 46|2@1+ (1,0) [0|3] "-"  BC,LOGBOX
 SG_ FuelFilterHeaterStatus : 44|2@1+ (1,0) [0|3] "-"  BC,LOGBOX
 SG_ EngineOilPressureLow : 40|2@1+ (1,0) [0|3] "-"  BC,LOGBOX
 SG_ EngineOverTemperature : 13|3@1+ (1,0) [0|2] "-"  LOGBOX
 SG_ EngineOverspeed : 10|2@1+ (1,0) [0|3] "-"  LOGBOX
 SG_ ColdStartHeaterStatus : 0|4@1+ (1,0) [0|15] "-"  BC,LOGBOX

BO_ 2565406464 ACK_EECx: 8 ECM_0x00
 SG_ PGN : 40|24@1+ (1,0) [0|16777215] "-"  LOGBOX
 SG_ Status : 0|2@1+ (1,0) [0|3] "-"  LOGBOX

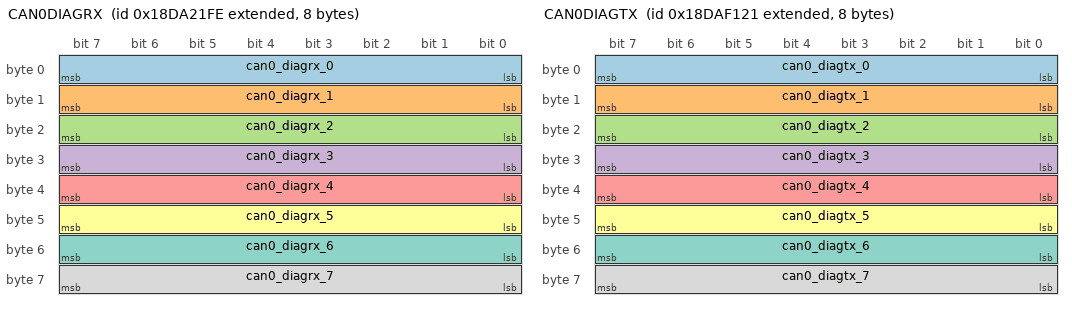
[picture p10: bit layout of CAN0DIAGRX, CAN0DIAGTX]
BO_ 2564432382 CAN0DIAGRX: 8 _TESTER
 SG_ can0_diagrx_0 : 0|8@1+ (1,0) [0|0] "-"  LOGBOX,BC
 SG_ can0_diagrx_1 : 8|8@1+ (1,0) [0|0] "-"  LOGBOX,BC
 SG_ can0_diagrx_2 : 16|8@1+ (1,0) [0|0] "-"  LOGBOX,BC
 SG_ can0_diagrx_3 : 24|8@1+ (1,0) [0|0] "-"  LOGBOX,BC
 SG_ can0_diagrx_4 : 32|8@1+ (1,0) [0|0] "-"  LOGBOX,BC
 SG_ can0_diagrx_5 : 40|8@1+ (1,0) [0|0] "-"  LOGBOX,BC
 SG_ can0_diagrx_6 : 48|8@1+ (1,0) [0|0] "-"  LOGBOX,BC
 SG_ can0_diagrx_7 : 56|8@1+ (1,0) [0|0] "-"  LOGBOX,BC

BO_ 2564485409 CAN0DIAGTX: 8 BC
 SG_ can0_diagtx_0 : 0|8@1+ (1,0) [0|0] "-"  LOGBOX,_TESTER
 SG_ can0_diagtx_1 : 8|8@1+ (1,0) [0|0] "-"  LOGBOX,_TESTER
 SG_ can0_diagtx_2 : 16|8@1+ (1,0) [0|0] "-"  LOGBOX,_TESTER
 SG_ can0_diagtx_3 : 24|8@1+ (1,0) [0|0] "-"  LOGBOX,_TESTER
 SG_ can0_diagtx_4 : 32|8@1+ (1,0) [0|0] "-"  LOGBOX,_TESTER
 SG_ can0_diagtx_5 : 40|8@1+ (1,0) [0|0] "-"  LOGBOX,_TESTER
 SG_ can0_diagtx_6 : 48|8@1+ (1,0) [0|0] "-"  LOGBOX,_TESTER
 SG_ can0_diagtx_7 : 56|8@1+ (1,0) [0|0] "-"  LOGBOX,_TESTER

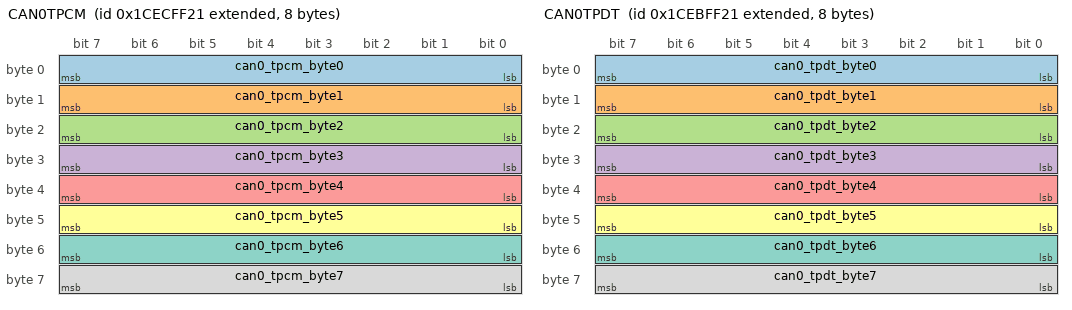
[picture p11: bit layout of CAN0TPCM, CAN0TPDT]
BO_ 2632777505 CAN0TPCM: 8 BC
 SG_ can0_tpcm_byte0 : 0|8@1+ (1,0) [0|0] "-"  LOGBOX,_TESTER
 SG_ can0_tpcm_byte1 : 8|8@1+ (1,0) [0|0] "-"  LOGBOX,_TESTER
 SG_ can0_tpcm_byte2 : 16|8@1+ (1,0) [0|0] "-"  LOGBOX,_TESTER
 SG_ can0_tpcm_byte3 : 24|8@1+ (1,0) [0|0] "-"  LOGBOX,_TESTER
 SG_ can0_tpcm_byte4 : 32|8@1+ (1,0) [0|0] "-"  LOGBOX,_TESTER
 SG_ can0_tpcm_byte5 : 40|8@1+ (1,0) [0|0] "-"  LOGBOX,_TESTER
 SG_ can0_tpcm_byte6 : 48|8@1+ (1,0) [0|0] "-"  LOGBOX,_TESTER
 SG_ can0_tpcm_byte7 : 56|8@1+ (1,0) [0|0] "-"  LOGBOX,_TESTER

BO_ 2632711969 CAN0TPDT: 8 BC
 SG_ can0_tpdt_byte0 : 0|8@1+ (1,0) [0|0] "-"  LOGBOX,_TESTER
 SG_ can0_tpdt_byte1 : 8|8@1+ (1,0) [0|0] "-"  LOGBOX,_TESTER
 SG_ can0_tpdt_byte2 : 16|8@1+ (1,0) [0|0] "-"  LOGBOX,_TESTER
 SG_ can0_tpdt_byte3 : 24|8@1+ (1,0) [0|0] "-"  LOGBOX,_TESTER
 SG_ can0_tpdt_byte4 : 32|8@1+ (1,0) [0|0] "-"  LOGBOX,_TESTER
 SG_ can0_tpdt_byte5 : 40|8@1+ (1,0) [0|0] "-"  LOGBOX,_TESTER
 SG_ can0_tpdt_byte6 : 48|8@1+ (1,0) [0|0] "-"  LOGBOX,_TESTER
 SG_ can0_tpdt_byte7 : 56|8@1+ (1,0) [0|0] "-"  LOGBOX,_TESTER

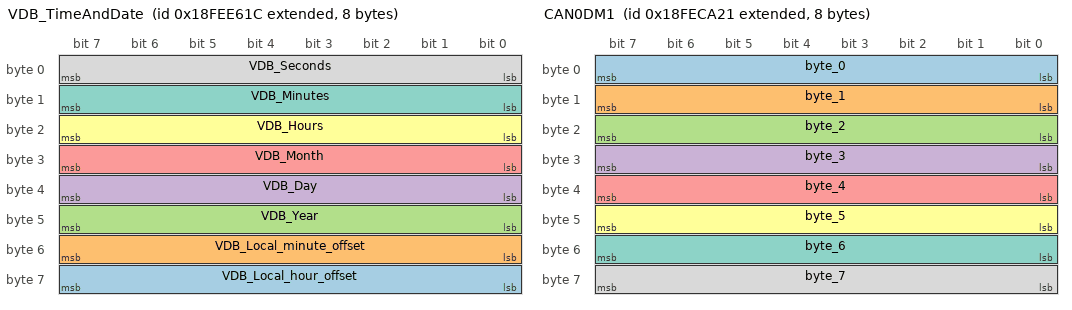
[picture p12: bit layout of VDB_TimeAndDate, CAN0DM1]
BO_ 2566841884 VDB_TimeAndDate: 8 LOGBOX
 SG_ VDB_Local_hour_offset : 56|8@1+ (1,-125) [-23|23] "hr"  LOGBOX
 SG_ VDB_Local_minute_offset : 48|8@1+ (1,-125) [-125|125] "min"  LOGBOX
 SG_ VDB_Year : 40|8@1+ (1,1985) [1985|2235] "-"  LOGBOX
 SG_ VDB_Day : 32|8@1+ (0.25,0.75) [0.25|31.75] "-"  LOGBOX
 SG_ VDB_Month : 24|8@1+ (1,0) [1|12] "-"  LOGBOX
 SG_ VDB_Hours : 16|8@1+ (1,0) [0|23] "hr"  LOGBOX
 SG_ VDB_Minutes : 8|8@1+ (1,0) [0|59] "min"  LOGBOX
 SG_ VDB_Seconds : 0|8@1+ (0.25,0) [0|59.75] "sec"  LOGBOX

BO_ 2566834721 CAN0DM1: 8 BC
 SG_ byte_0 : 0|8@1+ (1,0) [0|255] "-"  CP6,CP10,LOGBOX
 SG_ byte_1 : 8|8@1+ (1,0) [0|255] "-"  CP6,CP10,LOGBOX
 SG_ byte_2 : 16|8@1+ (1,0) [0|255] "-"  CP6,CP10,LOGBOX
 SG_ byte_3 : 24|8@1+ (1,0) [0|255] "-"  CP6,CP10,LOGBOX
 SG_ byte_4 : 32|8@1+ (1,0) [0|255] "-"  CP6,CP10,LOGBOX
 SG_ byte_5 : 40|8@1+ (1,0) [0|255] "-"  CP6,CP10,LOGBOX
 SG_ byte_6 : 48|8@1+ (1,0) [0|255] "-"  CP6,CP10,LOGBOX
 SG_ byte_7 : 56|8@1+ (1,0) [0|255] "-"  CP6,CP10,LOGBOX

BO_ 2566834942 _DM1: 42 Vector__XXX
 SG_ SPN10_Low : 320|16@1+ (1,0) [0|65536] "-"  CP6,CP10,LOGBOX
 SG_ SPN9_Low : 288|16@1+ (1,0) [0|65536] "-"  CP6,CP10,LOGBOX
 SG_ SPN8_Low : 256|16@1+ (1,0) [0|65536] "-"  CP6,CP10,LOGBOX
 SG_ SPN7_Low : 224|16@1+ (1,0) [0|65536] "-"  CP6,CP10,LOGBOX
 SG_ SPN6_Low : 192|16@1+ (1,0) [0|65536] "-"  CP6,CP10,LOGBOX
 SG_ SPN5_Low : 144|16@1+ (1,0) [0|65536] "-"  CP6,CP10,LOGBOX
 SG_ SPN4_Low : 112|16@1+ (1,0) [0|65536] "-"  CP6,CP10,LOGBOX
 SG_ SPN3_Low : 80|16@1+ (1,0) [0|65536] "-"  CP6,CP10,LOGBOX
 SG_ SPN2_Low : 48|16@1+ (1,0) [0|65536] "-"  CP6,CP10,LOGBOX
 SG_ FailureModeIdentifier10 : 304|5@1+ (1,0) [0|31] "-"  CP6,CP10,LOGBOX
 SG_ FailureModeIdentifier9 : 272|5@1+ (1,0) [0|31] "-"  CP6,CP10,LOGBOX
 SG_ FailureModeIdentifier8 : 240|5@1+ (1,0) [0|31] "-"  CP6,CP10,LOGBOX
 SG_ FailureModeIdentifier7 : 208|5@1+ (1,0) [0|31] "-"  CP6,CP10,LOGBOX
 SG_ FailureModeIdentifier6 : 176|5@1+ (1,0) [0|31] "-"  CP6,CP10,LOGBOX
 SG_ FailureModeIdentifier5 : 160|5@1+ (1,0) [0|31] "-"  CP6,CP10,LOGBOX
 SG_ FailureModeIdentifier4 : 128|5@1+ (1,0) [0|31] "-"  CP6,CP10,LOGBOX
 SG_ FailureModeIdentifier3 : 96|5@1+ (1,0) [0|31] "-"  CP6,CP10,LOGBOX
 SG_ FlashRedStopLamp : 12|2@1+ (1,0) [0|3] "-"  CP6,CP10,LOGBOX
 SG_ FlashProtectLamp : 8|2@1+ (1,0) [0|3] "-"  CP6,CP10,LOGBOX
 SG_ FlashMalfuncIndicatorLamp : 14|2@1+ (1,0) [0|3] "-"  CP6,CP10,LOGBOX
 SG_ FlashAmberWarningLamp : 10|2@1+ (1,0) [0|3] "-"  CP6,CP10,LOGBOX
 SG_ MalfunctionIndicatorLampStatus : 6|2@1+ (1,0) [0|3] "-"  CP6,CP10,LOGBOX
 SG_ AmberWarningLampStatus : 2|2@1+ (1,0) [0|3] "-"  CP6,CP10,LOGBOX
 SG_ OccurenceCount1 : 40|7@1+ (1,0) [0|126] "-"  CP6,CP10,LOGBOX
 SG_ SPNConversionMethod1 : 47|1@1+ (1,0) [0|1] "-"  CP6,CP10,LOGBOX
 SG_ FailureModeIdentifier1 : 32|5@1+ (1,0) [0|31] "-"  CP6,CP10,LOGBOX
 SG_ SPN1_Low : 16|16@1+ (1,0) [0|65536] "-"  CP6,CP10,LOGBOX
 SG_ RedStopLampState : 4|2@1+ (1,0) [0|3] "-"  CP6,CP10,LOGBOX
 SG_ ProtectLampStatus : 0|2@1+ (1,0) [0|3] "-"  CP6,CP10,LOGBOX
 SG_ FailureModeIdentifier2 : 64|5@1+ (1,0) [0|31] "-"  CP6,CP10,LOGBOX
 SG_ SPNConversionMethod10 : 319|1@1+ (1,0) [0|1] "-"  CP6,CP10,LOGBOX
 SG_ SPNConversionMethod9 : 287|1@1+ (1,0) [0|1] "-"  CP6,CP10,LOGBOX
 SG_ SPNConversionMethod8 : 255|1@1+ (1,0) [0|1] "-"  CP6,CP10,LOGBOX
 SG_ SPNConversionMethod7 : 223|1@1+ (1,0) [0|1] "-"  CP6,CP10,LOGBOX
 SG_ SPNConversionMethod6 : 191|1@1+ (1,0) [0|1] "-"  CP6,CP10,LOGBOX
 SG_ SPNConversionMethod5 : 175|1@1+ (1,0) [0|1] "-"  CP6,CP10,LOGBOX
 SG_ SPNConversionMethod4 : 143|1@1+ (1,0) [0|1] "-"  CP6,CP10,LOGBOX
 SG_ SPNConversionMethod3 : 111|1@1+ (1,0) [0|1] "-"  CP6,CP10,LOGBOX
 SG_ SPNConversionMethod2 : 79|1@1+ (1,0) [0|1] "-"  CP6,CP10,LOGBOX
 SG_ OccurenceCount10 : 312|7@1+ (1,0) [0|126] "-"  CP6,CP10,LOGBOX
 SG_ OccurenceCount9 : 280|7@1+ (1,0) [0|126] "-"  CP6,CP10,LOGBOX
 SG_ OccurenceCount8 : 248|7@1+ (1,0) [0|126] "-"  CP6,CP10,LOGBOX
 SG_ OccurenceCount7 : 216|7@1+ (1,0) [0|126] "-"  CP6,CP10,LOGBOX
 SG_ OccurenceCount6 : 184|7@1+ (1,0) [0|126] "-"  CP6,CP10,LOGBOX
 SG_ OccurenceCount5 : 168|7@1+ (1,0) [0|126] "-"  CP6,CP10,LOGBOX
 SG_ OccurenceCount4 : 136|7@1+ (1,0) [0|126] "-"  CP6,CP10,LOGBOX
 SG_ OccurenceCount3 : 104|7@1+ (1,0) [0|126] "-"  CP6,CP10,LOGBOX
 SG_ OccurenceCount2 : 72|7@1+ (1,0) [0|126] "-"  CP6,CP10,LOGBOX
 SG_ SPN10_High : 309|3@1+ (1,0) [0|7] "-"  CP6,CP10,LOGBOX
 SG_ SPN9_High : 277|3@1+ (1,0) [0|7] "-"  CP6,CP10,LOGBOX
 SG_ SPN8_High : 245|3@1+ (1,0) [0|7] "-"  CP6,CP10,LOGBOX
 SG_ SPN7_High : 213|3@1+ (1,0) [0|7] "-"  CP6,CP10,LOGBOX
 SG_ SPN6_High : 181|3@1+ (1,0) [0|7] "-"  CP6,CP10,LOGBOX
 SG_ SPN5_High : 165|3@1+ (1,0) [0|7] "-"  CP6,CP10,LOGBOX
 SG_ SPN4_High : 133|3@1+ (1,0) [0|7] "-"  CP6,CP10,LOGBOX
 SG_ SPN3_High : 101|3@1+ (1,0) [0|7] "-"  CP6,CP10,LOGBOX
 SG_ SPN2_High : 69|3@1+ (1,0) [0|7] "-"  CP6,CP10,LOGBOX
 SG_ SPN1_High : 37|3@1+ (1,0) [0|7] "-"  CP6,CP10,LOGBOX

CM_ BO_ 2365526021 "PM1 from GWS500";
CM_ SG_ 2365526021 ADM1 "To be completed";
CM_ SG_ 2365526021 ADM2 "To be completed";
CM_ SG_ 2365526021 ADM3 "To be completed";
CM_ SG_ 2365526021 ADM4 "To be completed";
CM_ SG_ 2365526021 ADP1 "To be completed";
CM_ SG_ 2365526021 ADP2 "To be completed";
CM_ SG_ 2365526021 ADP3 "To be completed";
CM_ SG_ 2365526021 ADP4 "To be completed";
CM_ SG_ 2365526021 EDM1 "To be completed";
CM_ SG_ 2365526021 EDM2 "To be completed";
CM_ SG_ 2365526021 EDP3 "To be completed";
CM_ SG_ 2365526021 EDP4 "To be completed";
CM_ SG_ 2365526021 AVP_Lever_Interlock "To be completed";
CM_ BO_ 2348876549 "Transmission Control # 1 from GWS500";
CM_ SG_ 2348876549 TransmissionRequestedRange_gw "gear selector position
'D',' N',' R','D1','D2','D3', ...";
CM_ SG_ 2348876549 DisengageDiffLockRqCntRear_gw "Command signal used to disengage the various differential locks, e.";
CM_ SG_ 2348876549 DisengageDiffLockRqCntFront_gw "Command signal used to disengage the various differential locks, e.";
CM_ SG_ 2348876549 DisengageDiffLockRqCnt_gw "Command signal used to disengage the various differential locks, e.";
CM_ SG_ 2348876549 DisengageDiffLockRqRearAxle2_gw "Command signal used to disengage the various differential locks, e.";
CM_ SG_ 2348876549 DisengageDiffLockRqRearAxle1_gw "Command signal used to disengage the various differential locks, e.";
CM_ SG_ 2348876549 DisengageDiffLockRqFrontAxle2_gw "Command signal used to disengage the various differential locks, e.";
CM_ SG_ 2348876549 DisengageDiffLockRqFrontAxle1_gw "Command signal used to disengage the various differential locks, e.";
CM_ SG_ 2348876549 TransRqedGear_gw "Gear requested by the operator, ABS, or engine.";
CM_ SG_ 2348876549 RqedPercentClutchSlip_gw "Parameter which represents the percent clutch slip requested by a device.";
CM_ SG_ 2348876549 DisengageDrivelineRq_gw "Command signal used to simply disengage the driveline, e.";
CM_ SG_ 2348876549 TorqueConvLockupDisableRq_gw "Command signal to prevent torque converter lockup, which may cause problems in certain circumstances for ASR.";
CM_ SG_ 2348876549 TransGearShiftInhibitRq_gw "Command signal to inhibit gear shifts.";
CM_ SG_ 2348876549 Reserved_TC1_GW_01 "Reserved";
CM_ SG_ 2348876549 Reserved_TC1_GW_02 "Reserved";
CM_ SG_ 2348876549 Reserved_TC1_GW_03 "Reserved";
CM_ BO_ 2348876577 "Transmission Control 1
This message is used by the BODY for controlling the gearbox mode (sand/normal and power/normal)";
CM_ SG_ 2348876577 TransMode4_bc "Indicates whether transmission mode 4 is enabled.";
CM_ SG_ 2348876577 TransMode3_bc "Indicates whether transmission mode 3 is enabled.";
CM_ SG_ 2348876577 TransMode2_bc "The signal shall be set by the BODY to define the Normal or Sand mode to the TCU.
It shall be transmitted on CAN as per Requirement SYS_CAN_3340.
The significant values of the signal shall be:
- Active: it indicates the Transmission mode has to be in SAND mode;
- NotActive: it indicates the Transmission mode has to be in NORMAL mode.
All the allowable values of the signal are detailed in CAN database.";
CM_ SG_ 2348876577 TransMode1_bc "The signal shall be set by the BODY to define the Economy Power mode switching request to the TCU.
It shall be transmitted on CAN as per Requirement SYS_CAN_3350.
The significant values of the signal shall be:
- Active: it indicates the Transmission mode has to be in POWER mode;
- NotActive: it indicates the Transmission mode has to be in ECONOMY mode.
All the allowable values of the signal are detailed in CAN database.";
CM_ SG_ 2348876577 DisengageDiffLockRqCntRear_bc "Command signal used to disengage the various differential locks, e.";
CM_ SG_ 2348876577 DisengageDiffLockRqCntFront_bc "Command signal used to disengage the various differential locks, e.";
CM_ SG_ 2348876577 DisengageDiffLockRqCnt_bc "Command signal used to disengage the various differential locks, e.";
CM_ SG_ 2348876577 DisengageDiffLockRqRearAxle2_bc "Command signal used to disengage the various differential locks, e.";
CM_ SG_ 2348876577 DisengageDiffLockRqRearAxle1_bc "Command signal used to disengage the various differential locks, e.";
CM_ SG_ 2348876577 DisengageDiffLockRqFrontAxle2_bc "Command signal used to disengage the various differential locks, e.";
CM_ SG_ 2348876577 DisengageDiffLockRqFrontAxle1_bc "Command signal used to disengage the various differential locks, e.";
CM_ SG_ 2348876577 TransRqedGear_bc "Gear requested by the operator, ABS, or engine.";
CM_ SG_ 2348876577 RqedPercentClutchSlip_bc "Parameter which represents the percent clutch slip requested by a device.";
CM_ SG_ 2348876577 DisengageDrivelineRq_bc "Command signal used to simply disengage the driveline, e.";
CM_ SG_ 2348876577 TorqueConvLockupDisableRq_bc "Command signal to prevent torque converter lockup, which may cause problems in certain circumstances for ASR.";
CM_ SG_ 2348876577 TransGearShiftInhibitRq_bc "Command signal to inhibit gear shifts.";
CM_ SG_ 2348876577 Reserved_TC1_BC_01 "Reserved";
CM_ SG_ 2348876577 Reserved_TC1_BC_02 "Reserved";
CM_ SG_ 2348876577 Reserved_TC1_BC_03 "Reserved";
CM_ SG_ 2348876577 TransmissionShift "Transmission Shift Selector Display Mode Switch (see also SPN 2985)";
CM_ SG_ 2348876577 Reserved_TC1_BC_04 "Reserved";
CM_ SG_ 2566803994 Alt_Current "To be completed";
CM_ SG_ 2566899738 Alt_HourMeter "To be completed";
CM_ SG_ 2566899738 Alt_WarningLight "The signal shall be used to know the alternator warning light status";
CM_ SG_ 2566899738 Alt_LedStatus "To be completed";
CM_ SG_ 2566899738 Alt_OVCO_Counter "To be completed";
CM_ SG_ 2566899738 Alt_PercentOutput_1 "The signal shall be used by the BODY to know the current Alternator Load.";
CM_ SG_ 2566899738 Alt_BatteryTemperature "To be completed";
CM_ SG_ 2566837530 Alt_Speed_1 "The signal shall be used by the BODY to know the current Alternator speed.";
CM_ SG_ 2565472289 VDB_Pgn_Req_Byte_2 "The signal shall be set by the BODY to define the Pgn Requets Byte 2.";
CM_ SG_ 2565472289 VDB_Pgn_Req_Byte_1 "The signal shall be set by the BODY to define the Pgn Requets Byte 1.";
CM_ SG_ 2565472289 VDB_Pgn_Req_Byte_0 "The signal shall be set by the BODY to define the Pgn Requets Byte 0.";
CM_ BO_ 2633922849 "Tire Pressure Control Unit Target Pressures";
CM_ SG_ 2633922849 Selected_Load_Mode_TP2_BODY "The signal shall be used by the BODY to know  the Load mode selected by the CTIS.
It shall be received from CAN as per Requirement SYS_CAN_3280.
The significant values of the signal:
- Empty
- Half
- Full
- Unknow";
CM_ SG_ 2633922849 Selected_Terrain_Mode_TP2_BODY "The signal shall be set by the BODY to define the Selected Terrain Mode request to the CTIS.
It shall be received from CAN as per Requirement SYS_CAN_3260.
The significant values of the signal:
- Road
- Track
- Sand
- Emergency
- NotApplicable";
CM_ BO_ 2633922593 "Tire Pressure Control Unit Mode and Status";
CM_ SG_ 2633922593 TirePressCheckInterval_TP1_BODY "The signal shall be set by the BODY to define the Check Interval request to the CTIS.
It shall be received from CAN as per Requirement SYS_CAN_3250.
The significant values of the signal shall be:
- FastCheck: it indicates the Fast Check mode;
- NormalCheck: it indicates the Normal Check mode;
- NotApplicable: it indicates that the Check Interval is unknown.
All the allowable values of the signal are detailed in CAN database.";
CM_ SG_ 2564489201 DIAG_PHYS_REQUEST_DATA "To be completed";
CM_ BO_ 2566841600 "Engine Hours, Revolutions";
CM_ SG_ 2566841600 EngTotalRevolutions "Accumulated number of revolutions of engine crankshaft during its operation.";
CM_ SG_ 2566841600 EngTotalHoursOfOperation "Accumulated time of operation of engine.
See also SPN 247";
CM_ BO_ 2348810243 "Torque/Speed Control 1";
CM_ SG_ 2348810243 EngineRequestedTq_HR_TSC1_TE "To be completed";
CM_ SG_ 2348810243 ControlPurpose_TSC1_TE "State signal which indicates which control mode the sending device is using to generate the TSC1 command.";
CM_ SG_ 2348810243 TransmissionRate_TSC1_TE "This parameter indicates the transmission rate at which the sending device will transmit the TSC1 message.";
CM_ SG_ 2348810243 EngOverrideCtrlMode_TSC1_TE "To be completed";
CM_ SG_ 2348810243 MessageChecksum_TSC1_TE "To be completed";
CM_ SG_ 2348810243 MessageCounter_TSC1_TE "To be completed";
CM_ SG_ 2348810243 EngRqedTorque_Limit_TSC1_TE "The signal shall be set by the BODY to define the Torque request to the engine. 
The values normally used are:
0: (no reduction request)
-25 (Torque reduction reques equal to 25%);
-50 (Torque reduction reques equal to 50%);
-75 (Torque reduction reques equal to 75%);
-100 (Torque reduction reques equal to 100%);
-125 (Torque reduction reques equal to 125%);";
CM_ SG_ 2348810243 EngRqedSpeed_SpeedLimit_TSC1_TE "Parameter provided to the engine from external sources in the torque/speed control message.";
CM_ SG_ 2348810243 OverrideCtrlModPriority_TSC1_TE "The signal shall be set by the BODY to define the control priority request to the engine.

The significant values of the signal shall be:
- LowPriority: it indicates no Torque request;
- MediumPriority: it indicates a Torque request control.
All the allowable values of the signal detailed in CAN database.";
CM_ SG_ 2348810243 EngRqedSpeedCtrlCondit_TSC1_TE "This mode tells the engine control system the governor characteristics that are desired during speed control.";
CM_ BO_ 2633923123 "Tire Pressure Control Unit Current Pressures";
CM_ SG_ 2633923123 Current_Load_Mode "To be completed";
CM_ SG_ 2633923123 Current_Terrain_Mode "The signal shall be used by the BODY to know the current Terrain mode engaged bt CTIS.
It shall be received from CAN as per Requirement SYS_CAN_3100.
The significant values of the signal:
- Road
- Track
- Sand
- Emergency
- NotApplicable";
CM_ BO_ 2633922867 "Tire Pressure Control Unit Target Pressures";
CM_ SG_ 2633922867 Selected_Load_Mode_TP2 "The signal shall be used by the BODY to know  the Load mode selected by the CTIS.
It shall be received from CAN as per Requirement SYS_CAN_3280.
The significant values of the signal shall be:
- Empty
- Half
- Full
- Unknow";
CM_ SG_ 2633922867 Selected_Terrain_Mode_TP2 "The signal shall be used by the BODY to know the Terrain mode selected by the CTIS.
It shall be received from CAN as per Requirement SYS_CAN_3090.
The significant values of the signal shall be:
- Road
- TrackTail
- SandMudSnow
- Emergency
- Unknown";
CM_ SG_ 2633922611 CTISProcessMode "The signal shall be used to know the Ctis Process Mode, transmitted on CAN as per Requirement SYS_CAN_3710.
Values of the signal:
- Inflate
- Deflate
- Overspeed
- Overspeed access denied";
CM_ SG_ 2633922611 TirePressCheckInterval_TP1 "The signal shall be used by the BODY to know the Check Interval coming from the CTIS.
It shall be received from CAN as per Requirement SYS_CAN_3080.
The significant values of the signal shall be:
- FastCheck
- NormalCheck
- StartupWaitMode
- NotApplicable
The signal shall be considered valid as per Requirement SYS_ARC_0020.";
CM_ BO_ 2566845491 "Tire Condition";
CM_ SG_ 2566845491 TirePressStatus "Signal indicating the pressure level of the tire.";
CM_ SG_ 2566845491 CTIWheelSolenoidFault "Indicates the status of electrical fault on CTI wheel interface.";
CM_ SG_ 2566845491 CTITireStatus "The signal shall be used to know the Ctis Tire Status.
It shall be transmitted on CAN as per Requirement SYS_CAN_3780.
The significant values of the signal shall be:
- Ok: it indicates that the Pressure is ok;
- Leak: it indicates that the tire is leaking;
- Burst: it indicates that the Tire has a severe damage;
- NotApplicable: it indicates that the signal is not available.";
CM_ SG_ 2566845491 CTIWheelValveMode "Indicates whether the wheel is being monitored by the CTI controller.";
CM_ SG_ 2566845491 TirePress "The signal shall be used to know the Ctis Tire Pressure.
It shall be transmitted on CAN as per Requirement SYS_CAN_3770.
The significant values of the signal shall be:
- [0;1250]: they indicate the current Tire Pressure.";
CM_ SG_ 2566845491 TireLocation "The signal shall be used to know at which wheel the Ctis Tire Pressure and the Ctis Tire Status refer to.
It shall be transmitted on CAN as per Requirement SYS_CAN_3720.
The significant values of the signal shall be:
- FrontLeft
- FrontRight
- FirstCentralLeft
- FirstCentralRight
- SecondCentralLeft
- SecondCentralRight
- RearLeft
- RearLeft";
CM_ BO_ 2365484270 "Tachograph";
CM_ SG_ 2365484270 TachographVehicleSpeed "Speed of the vehicle registered by the tachograph.
See also SPN 1624";
CM_ SG_ 2365484270 TachographOutputShaftSpeed "Calculated speed of the transmission output shaft.
See also SPN 1623";
CM_ BO_ 2566840835 "Transmission Configuration";
CM_ SG_ 2566840835 TransGearRatio_6 "To be completed";
CM_ SG_ 2566840835 TransGearRatio_5 "To be completed";
CM_ SG_ 2566840835 TransGearRatio_4 "To be completed";
CM_ SG_ 2566840835 TransGearRatio_3 "To be completed";
CM_ SG_ 2566840835 TransGearRatio_2 "To be completed";
CM_ SG_ 2566840835 TransGearRatio_1 "To be completed";
CM_ SG_ 2566840835 TransGearRatio_0 "To be completed";
CM_ SG_ 2566840835 NumberOfForwardGearRatios "Number of forward gear ratios in the transmission, provided as part of the configuration.";
CM_ SG_ 2566840835 NumberOfReverseGearRatios "Number of reverse gear ratios in the transmission, provided as part of the transmission configuration.";
CM_ BO_ 2566847248 "Retarder fluids";
CM_ SG_ 2566847248 HydRetarderOilTemp "Temperature of oil found in a hydraulic retarder.";
CM_ SG_ 2566847248 HydRetarderPress "Gage pressure of oil in hydraulic retarder system.";
CM_ BO_ 2566840592 "Retarder Configuration";
CM_ SG_ 2566840592 PercentTorqueAtPeakTorquePoint5 "To be completed";
CM_ SG_ 2566840592 ReferenceRetarderTorque "This parameter is the 100% reference value for all defined indicated retarder torque parameters.";
CM_ SG_ 2566840592 RetarderSpeedAtPeakTorquePoint5 "To be completed";
CM_ SG_ 2566840592 PercentTorqueAtPoint4 "To be completed";
CM_ SG_ 2566840592 RetarderSpeedAtPoint4 "Retarder speed of point 4 of the engine retarder torque map.";
CM_ SG_ 2566840592 PercentTorqueAtPoint3 "To be completed";
CM_ SG_ 2566840592 RetarderSpeedAtPoint3 "Retarder speed of point 3 of the engine retarder torque map.";
CM_ SG_ 2566840592 PercentTorqueAtMaxSpeedPoint2 "The torque limit that indicates the available retarder torque which can be provided by the retarder at its maximum speed.";
CM_ SG_ 2566840592 MaxRetarderSpeedPoint2 "Maximum speed of retarder (Please reference PGN 65249).";
CM_ SG_ 2566840592 PercentTorqueAtIdlePoint1 "The torque limit that indicates the available retarder torque which can be provided by the retarder at idle speed.";
CM_ SG_ 2566840592 RetarderSpeedAtIdlePoint1 "To be completed";
CM_ SG_ 2566840592 RetarderCtrlMethod "This parameter identifies the number of steps used by the retarder.";
CM_ SG_ 2566840592 RetarderLocation "To be completed";
CM_ SG_ 2566840592 RetarderType "A vehicle retarder is a supplementary device to the wheel brakes for the driver to better control the vehicle.";
CM_ BO_ 2566844928 "Fuel Economy (Liquid)";
CM_ SG_ 2566844928 EngInstantaneousFuelEconomy "Current fuel economy at current vehicle velocity.
See also SPN 184.";
CM_ SG_ 2566844928 EngFuelRate "Amount of fuel consumed by engine per unit of time.
See also SPN 183";
CM_ BO_ 2566842624 "Fuel Consumption (Liquid)";
CM_ SG_ 2566842624 EngTotalFuelUsed "Accumulated amount of fuel used during vehicle operation.";
CM_ BO_ 2566801923 "Electronic Transmission Controller 7";
CM_ SG_ 2566801923 TransMode1Indicator "To be completed";
CM_ SG_ 2566801923 TransMode2Indicator "To be completed";
CM_ SG_ 2566801923 TransMode3Indicator "To be completed";
CM_ SG_ 2566801923 TransMode4Indicator "To be completed";
CM_ SG_ 2566801923 TransShiftInhibitIndicator "State signal indicating a transmission request for the Shift Inhibit Indicator to be active or inactive.";
CM_ SG_ 2566801923 TransEngCrankEnable "State signal from the transmission indicating if the transmission’s status is such that engine cranking is allowed (i.e. at a minimum, transmission is in neutral and the driveline is disengaged). As sender of this information, the transmission is responsible for correct indication immediately upon first broadcast of this parameter. See also SPN 2900";
CM_ SG_ 2566801923 ActiveShiftConsoleIndicator "To be completed";
CM_ SG_ 2566801923 TransReadyForBrakeRelease "To be completed";
CM_ SG_ 2566801923 TransRqedRangeDisplayFlashState "To be completed";
CM_ SG_ 2566801923 TransRqedRangeDisplayBlankState "To be completed";
CM_ BO_ 2565866755 "Electronic Transmission Controller 2";
CM_ SG_ 2565866755 TransmCurrentRange "Range currently being commanded by the transmission control system.";
CM_ SG_ 2565866755 TransmRequestRange "Range selected by the operator.";
CM_ SG_ 2565866755 TransmCurrentGear "The signal shall be used to know the current engaged gear.
See also SPN 523";
CM_ SG_ 2565866755 TransmActualGearRatio "Actual ratio of input shaft speed to output shaft speed.";
CM_ SG_ 2565866755 TransmSelectedGear "To be completed";
CM_ BO_ 2364539395 "Electronic Transmission Controller 1";
CM_ SG_ 2364539395 SrcAddrssOfCtrllngDvcFrTrnsCtrl "The source address of the SAE J1939 device currently controlling the transmission.";
CM_ SG_ 2364539395 TransInputShaftSpeed "Rotational velocity of the primary shaft transferring power into the transmission.";
CM_ SG_ 2364539395 ProgressiveShiftDisable "Command signal used to indicate that progressive shifting by the engine should be disallowed.";
CM_ SG_ 2364539395 EngMomentaryOverspeedEnable "To be completed";
CM_ SG_ 2364539395 PercentClutchSlip "Parameter which represents the ratio of input shaft speed to current engine speed (in percent).";
CM_ SG_ 2364539395 TransmOutputShaftSpeed "Calculated speed of the transmission output shaft.
See also SPN 191";
CM_ SG_ 2364539395 TransmShiftInProcess "Indicates that the transmission is in process of shifting from the current gear to the selected gear.";
CM_ SG_ 2364539395 TorqueConverterLockupEngaged "State signal which indicates whether the torque converter lockup is engaged.";
CM_ SG_ 2364539395 TransmDrivelineEngaged "To be completed";
CM_ BO_ 2566843904 "Engine Temperature 1";
CM_ SG_ 2566843904 EngOilTemp1 "Temperature of the engine lubricant
See also SPN 175";
CM_ SG_ 2566843904 EngFuelTemp "Temperature of fuel (or gas) passing through the first fuel control system. See SPN 3468 for the second control system.
See also SPN 174";
CM_ SG_ 2566843904 EngCoolantTemp "Engine Coolant Temperature
See also SPN 110";
CM_ BO_ 2565865488 "Electronic Retarer Controller 1 - ZF Retarder";
CM_ SG_ 2565865488 RetarderSelectionNonEng "To be completed";
CM_ SG_ 2565865488 ActlMxAvlblRtarderPercentTorque "This is the maximum amount of torque that the retarder can immediately deliver.";
CM_ SG_ 2565865488 DrvrsDmandRetarderPercentTorque "The signal shall be used by the BODY to know whether the TCU is applying the Retarder activation/deactivation command.  ";
CM_ SG_ 2565865488 SrcAddrssOfCtrllngDvcFrRtrdrCtrl "The source address of the SAE J1939 device currently controlling the retarder.";
CM_ SG_ 2565865488 RetarderRqingBrakeLight "To be completed";
CM_ SG_ 2565865488 EngCoolantLoadIncrease "Status of an event, external to the engine, that may increase the nominal temperature of the engine coolant liquid.";
CM_ SG_ 2565865488 IntendedRetarderPercentTorque "Braking torque of retarder that the retarder is currently trying to achieve.";
CM_ SG_ 2565865488 ActualRetarderPrctTorque "Actual braking torque of the retarder as a percent of retarder configuration reference torque SPN 556.";
CM_ SG_ 2565865488 RetarderEnbShiftAssiSwitch "Switch signal which indicates whether the operator wishes the retarder to be enabled for transmission shift assist.";
CM_ SG_ 2565865488 RetarderEnbBrkAssiSwitch "Switch signal which indicates whether the operator wishes the retarder to be enabled for vehicle braking assist.";
CM_ SG_ 2565865488 RetarderTorqueMode "State signal which indicates which retarder torque mode is currently generating, limiting, or controlling the torque.";
CM_ SG_ 2566844160 EngOilPress "Gage pressure of oil in engine lubrication system as provided by oil pump.
See also SPN 100";
CM_ BO_ 2566840064 "Electronic Engine Controller 3";
CM_ SG_ 2566840064 EstEngPrsticLossesPercentTq "The calculated torque that indicates the estimated amount of torque loss due to engine parasitics, such as cooling fan, air compressor, air conditioning, etc. It is expressed as a percent of Engine Reference Torque.
When the data value of this parameter is equal to FB it means that all parasitic losses calculated by the engine are
included in the Engine's Nominal Friction Percent Torque (SPN 514).
See also SPN 2978";
CM_ SG_ 2566840064 EngsDsrdOprtngSpdAsymmtryAdj "This byte is utilized in transmission gear selection routines and indicates the engine's preference of lower versus higher engine speeds should its desired speed not be achievable. This is a scaled ratio such that 125 represents an equal
preference for a speed lower or higher that the engine's indicated desired speed. See also SPN 519";
CM_ SG_ 2566840064 EngsDesiredOperatingSpeed "An indication by the engine of the optimal operating speed of the engine for the current existing conditions. These
conditions may include the torque generated to accommodate powertrain demands from the operator (via the accelerator
pedal), cruise control, road speed limit governors, or ASR. Dynamic commands from functions such as smoke control or
shift control are excluded from this calculation.
See also SPN 515";
CM_ SG_ 2566840064 NominalFrictionPercentTq "The calculated torque that indicates the amount of torque required by the basic engine itself added by the loss torque of
accessories. It contains the frictional and thermodynamic loss of the engine itself, pumping torque loss (SPN 5398), and
the losses of fuel, oil and cooling pumps. The data is transmitted in indicated torque as a percent of reference engine
torque (see the engine configuration message, PGN 65251).See SPN 2978. See also SPN 514";
CM_ BO_ 2364539648 "Electronic Engine Controller 2";
CM_ SG_ 2364539648 Eng_PercentLoadAtCurrentSpeed "To be completed";
CM_ SG_ 2364539648 AccelPedalKickdownSwitch "Switch signal which indicates whether the accelerator pedal kickdown switch is opened or closed. The kickdown switch is
defined in SAE J1843.
See also SPN 559.";
CM_ SG_ 2364539648 AccelPedal1LowIdleSwitch "Switch signal which indicates the state of the accelerator pedal 1 low idle switch. The low idle switch is defined in SAE
Recommended Practice J1843.
See also SPN558.";
CM_ SG_ 2364539648 AccelPedalPos1 "The ratio of actual position of the analog engine speed/torque request input device (such as an accelerator pedal or
throttle lever) to the maximum position of the input device. This parameter is intended for the primary accelerator control
in an application. If an application has only one accelerator control, use SPN 91.
See also SPN 91.";
CM_ BO_ 2364539904 "Electronic Engine Controller 1";
CM_ SG_ 2364539904 EngineStarterMode "To be completed";
CM_ SG_ 2364539904 ActualEnginePercTrq_HighResol "To be completed";
CM_ SG_ 2364539904 EngDemandPercentTorque "To be completed";
CM_ SG_ 2364539904 SrcAddrssOfCtrllngDvcForEngCtrl "The source address of the SAE J1939 device currently controlling the engine.";
CM_ SG_ 2364539904 EngSpeed "Actual engine speed which is calculated over a minimum crankshaft angle of 720 degrees divided by the number of
cylinders.
See also SPN 190";
CM_ SG_ 2364539904 ActualEngPercentTorque "The calculated output torque of the engine.";
CM_ SG_ 2364539904 DriversDemandEngPercentTorque "The requested torque output of the engine by the driver.";
CM_ SG_ 2364539904 EngTorqueMode "State signal which indicates which engine torque mode is currently generating, limiting, or controlling the torque.";
CM_ BO_ 2566841088 "Engine Configuration";
CM_ SG_ 2566841088 SupportTSC1CtrlPurposeGroup4Of4 "This parameter indicates which TSC1 control purposes are supported in group 4 of 4.";
CM_ SG_ 2566841088 SupportVariableRateTSC1Message "To be completed";
CM_ SG_ 2566841088 SupportTSC1CtrlPurposeGroup3Of4 "This parameter indicates which TSC1 control purposes are supported in group 3 of 4.";
CM_ SG_ 2566841088 SupportTSC1CtrlPurposeGroup2Of4 "This parameter indicates which TSC1 control purposes are supported in group 2 of 4.";
CM_ SG_ 2566841088 SupportTSC1CtrlPurposeGroup1Of4 "This parameter indicates which TSC1 control purposes are supported in group 1 of 4.";
CM_ SG_ 2566841088 EngDefaultTorqueLimit "Companion parameter to Transmission Torque Limit (SPN 1845).";
CM_ SG_ 2566841088 EngMomentOfInertia "Moment of inertia for the engine, including items driven full-time by the engine such as fuel, oil and cooling pumps.";
CM_ SG_ 2566841088 EngExRngRqdSpdCtrlRngUpperLimit "To be completed";
CM_ SG_ 2566841088 EngRqdTorqueCtrlRangeUpperLimit "The maximum engine torque that the engine will allow when operating in a torque control/limit mode.";
CM_ SG_ 2566841088 EngRqdTorqueCtrlRangeLowerLimit "The minimum engine torque that the engine will allow when operating in a torque control/limit mode.";
CM_ SG_ 2566841088 EngRqedSpeedCtrlRangeUpperLimit "To be completed";
CM_ SG_ 2566841088 EngRqedSpeedCtrlRangeLowerLimit "The minimum engine speed that the engine will allow when operating in a speed control/limit mode.";
CM_ SG_ 2566841088 EngMxMomentaryOverrideTimeLimit "The maximum time limit allowed to override the engine's high idle speed.";
CM_ SG_ 2566841088 EngMxMmntaryOverrideSpeedPoint7 "The maximum engine speed above high idle allowed by the engine control during a momentary high idle override.";
CM_ SG_ 2566841088 EngReferenceTorque "This parameter is the 100% reference value for all defined indicated engine torque parameters. It is only defined once
and doesn't change if a different engine torque map becomes valid.
See also SPN 544";
CM_ SG_ 2566841088 EngSpeedAtHighIdlePoint6 "Engine speed of high idle (point 6) of the engine torque map (see PGN 65251 and supporting document).";
CM_ SG_ 2566841088 EngGainOfEndspeedGovernor "To be completed";
CM_ SG_ 2566841088 EngPercentTorqueAtPoint5 "To be completed";
CM_ SG_ 2566841088 EngSpeedAtPoint5 "Engine speed of point 3, 4, and 5 of the engine torque map (see PGN 65251 and supporting document).";
CM_ SG_ 2566841088 EngPercentTorqueAtPoint4 "To be completed";
CM_ SG_ 2566841088 EngSpeedAtPoint4 "Engine speed of point 3, 4, and 5 of the engine torque map (see PGN 65251 and supporting document).";
CM_ SG_ 2566841088 EngPercentTorqueAtPoint3 "To be completed";
CM_ SG_ 2566841088 EngSpeedAtPoint3 "Engine speed of point 3, 4, and 5 of the engine torque map (see PGN 65251 and supporting document).";
CM_ SG_ 2566841088 EngPercentTorqueAtPoint2 "To be completed";
CM_ SG_ 2566841088 EngSpeedAtPoint2 "Engine speed of point 2 of the engine torque map (see PGN 65251 and supporting document).";
CM_ SG_ 2566841088 EngPercentTorqueAtIdlePoint1 "The torque limit that indicates the available engine torque which can be provided by the engine at idle speed.";
CM_ SG_ 2566841088 EngSpeedAtIdlePoint1 "To be completed";
CM_ SG_ 2566834944 MalfunctionIndicatorLampStatus "A lamp used to relay only emissions-related trouble code information.";
CM_ SG_ 2566834944 AmberWarningLampStatus "This lamp is used to relay trouble code information that is reporting a problem with the vehicle system but the vehicle neednot be immediately stopped.";
CM_ SG_ 2566834944 RedStopLampState "This lamp is uesed to relay trouble code information that is of a severe enought condition that it warrants stopping the vehicle.";
CM_ SG_ 2566834944 SPN9_Low "SPN #9 (Conversion Version 4)";
CM_ SG_ 2566834944 SPN9_High "SPN #9 (Conversion Version 4)";
CM_ SG_ 2566834944 SPN8_Low "SPN #8 (Conversion Version 4)";
CM_ SG_ 2566834944 SPN8_High "SPN #8 (Conversion Version 4)";
CM_ SG_ 2566834944 SPN7_Low "SPN #7 (Conversion Version 4)";
CM_ SG_ 2566834944 SPN7_High "SPN #7 (Conversion Version 4)";
CM_ SG_ 2566834944 SPN6_Low "SPN #6 (Conversion Version 4)";
CM_ SG_ 2566834944 SPN6_High "SPN #6 (Conversion Version 4)";
CM_ SG_ 2566834944 SPN5_Low "SPN #5 (Conversion Version 4)";
CM_ SG_ 2566834944 SPN5_High "SPN #5 (Conversion Version 4)";
CM_ SG_ 2566834944 SPN4_Low "SPN #4 (Conversion Version 4)";
CM_ SG_ 2566834944 SPN4_High "SPN #4 (Conversion Version 4)";
CM_ SG_ 2566834944 SPN3_Low "SPN #3 (Conversion Version 4)";
CM_ SG_ 2566834944 SPN3_High "SPN #3 (Conversion Version 4)";
CM_ SG_ 2566834944 SPN2_Low "SPN #2 (Conversion Version 4)";
CM_ SG_ 2566834944 SPN2_High "SPN #2 (Conversion Version 4)";
CM_ SG_ 2566834944 SPN1_Low "SPN #1 (Conversion Version 4)";
CM_ SG_ 2566834944 SPN1_High "SPN #1 (Conversion Version 4)";
CM_ SG_ 2566834944 SPN10_Low "SPN #10 (Conversion Version 4)";
CM_ SG_ 2566834944 SPN10_High "SPN #10 (Conversion Version 4)";
CM_ SG_ 2566834944 OccurrenceCount9 "The 7 bit occurence count field contains the number of times a fault has gone from active to previously active.";
CM_ SG_ 2566834944 OccurrenceCount8 "The 7 bit occurence count field contains the number of times a fault has gone from active to previously active.";
CM_ SG_ 2566834944 OccurrenceCount7 "The 7 bit occurence count field contains the number of times a fault has gone from active to previously active.";
CM_ SG_ 2566834944 OccurrenceCount6 "The 7 bit occurence count field contains the number of times a fault has gone from active to previously active.";
CM_ SG_ 2566834944 OccurrenceCount5 "The 7 bit occurence count field contains the number of times a fault has gone from active to previously active.";
CM_ SG_ 2566834944 OccurrenceCount4 "The 7 bit occurence count field contains the number of times a fault has gone from active to previously active.";
CM_ SG_ 2566834944 OccurrenceCount3 "The 7 bit occurence count field contains the number of times a fault has gone from active to previously active.";
CM_ SG_ 2566834944 OccurrenceCount2 "The 7 bit occurence count field contains the number of times a fault has gone from active to previously active.";
CM_ SG_ 2566834944 OccurrenceCount10 "The 7 bit occurence count field contains the number of times a fault has gone from active to previously active.";
CM_ SG_ 2566834944 OccurrenceCount1 "The 7 bit occurence count field contains the number of times a fault has gone from active to previously active.";
CM_ SG_ 2566834944 FailureModeIdentifier9 "The FMI defines the type of failure detected in the subsystem identified by an SPN.";
CM_ SG_ 2566834944 FailureModeIdentifier8 "The FMI defines the type of failure detected in the subsystem identified by an SPN.";
CM_ SG_ 2566834944 FailureModeIdentifier7 "The FMI defines the type of failure detected in the subsystem identified by an SPN.";
CM_ SG_ 2566834944 FailureModeIdentifier6 "The FMI defines the type of failure detected in the subsystem identified by an SPN.";
CM_ SG_ 2566834944 FailureModeIdentifier5 "The FMI defines the type of failure detected in the subsystem identified by an SPN.";
CM_ SG_ 2566834944 FailureModeIdentifier4 "The FMI defines the type of failure detected in the subsystem identified by an SPN.";
CM_ SG_ 2566834944 FailureModeIdentifier3 "The FMI defines the type of failure detected in the subsystem identified by an SPN.";
CM_ SG_ 2566834944 FailureModeIdentifier2 "The FMI defines the type of failure detected in the subsystem identified by an SPN.";
CM_ SG_ 2566834944 FailureModeIdentifier10 "The FMI defines the type of failure detected in the subsystem identified by an SPN.";
CM_ SG_ 2566834944 FailureModeIdentifier1 "The FMI defines the type of failure detected in the subsystem identified by an SPN.";
CM_ SG_ 2566835456 SPN9_Low "SPN #9 (Conversion Version 4)";
CM_ SG_ 2566835456 SPN9_High "SPN #9 (Conversion Version 4)";
CM_ SG_ 2566835456 SPN8_Low "SPN #8 (Conversion Version 4)";
CM_ SG_ 2566835456 SPN8_High "SPN #8 (Conversion Version 4)";
CM_ SG_ 2566835456 SPN7_Low "SPN #7 (Conversion Version 4)";
CM_ SG_ 2566835456 SPN7_High "SPN #7 (Conversion Version 4)";
CM_ SG_ 2566835456 SPN6_Low "SPN #6 (Conversion Version 4)";
CM_ SG_ 2566835456 SPN6_High "SPN #6 (Conversion Version 4)";
CM_ SG_ 2566835456 SPN5_Low "SPN #5 (Conversion Version 4)";
CM_ SG_ 2566835456 SPN5_High "SPN #5 (Conversion Version 4)";
CM_ SG_ 2566835456 SPN4_Low "SPN #4 (Conversion Version 4)";
CM_ SG_ 2566835456 SPN4_High "SPN #4 (Conversion Version 4)";
CM_ SG_ 2566835456 SPN3_Low "SPN #3 (Conversion Version 4)";
CM_ SG_ 2566835456 SPN3_High "SPN #3 (Conversion Version 4)";
CM_ SG_ 2566835456 SPN2_Low "SPN #2 (Conversion Version 4)";
CM_ SG_ 2566835456 SPN2_High "SPN #2 (Conversion Version 4)";
CM_ SG_ 2566835456 SPN1_Low "SPN #1 (Conversion Version 4)";
CM_ SG_ 2566835456 SPN1_High "SPN #1 (Conversion Version 4)";
CM_ SG_ 2566835456 SPN10_Low "SPN #10 (Conversion Version 4)";
CM_ SG_ 2566835456 SPN10_High "SPN #10 (Conversion Version 4)";
CM_ SG_ 2566835456 OccurrenceCount9 "The 7 bit occurence count field contains the number of times a fault has gone from active to previously active.";
CM_ SG_ 2566835456 OccurrenceCount8 "The 7 bit occurence count field contains the number of times a fault has gone from active to previously active.";
CM_ SG_ 2566835456 OccurrenceCount7 "The 7 bit occurence count field contains the number of times a fault has gone from active to previously active.";
CM_ SG_ 2566835456 OccurrenceCount6 "The 7 bit occurence count field contains the number of times a fault has gone from active to previously active.";
CM_ SG_ 2566835456 OccurrenceCount5 "The 7 bit occurence count field contains the number of times a fault has gone from active to previously active.";
CM_ SG_ 2566835456 OccurrenceCount4 "The 7 bit occurence count field contains the number of times a fault has gone from active to previously active.";
CM_ SG_ 2566835456 OccurrenceCount3 "The 7 bit occurence count field contains the number of times a fault has gone from active to previously active.";
CM_ SG_ 2566835456 OccurrenceCount2 "The 7 bit occurence count field contains the number of times a fault has gone from active to previously active.";
CM_ SG_ 2566835456 OccurrenceCount10 "The 7 bit occurence count field contains the number of times a fault has gone from active to previously active.";
CM_ SG_ 2566835456 OccurrenceCount1 "The 7 bit occurence count field contains the number of times a fault has gone from active to previously active.";
CM_ SG_ 2566835456 FailureModeIdentifier9 "The FMI defines the type of failure detected in the subsystem identified by an SPN.";
CM_ SG_ 2566835456 FailureModeIdentifier8 "The FMI defines the type of failure detected in the subsystem identified by an SPN.";
CM_ SG_ 2566835456 FailureModeIdentifier7 "The FMI defines the type of failure detected in the subsystem identified by an SPN.";
CM_ SG_ 2566835456 FailureModeIdentifier6 "The FMI defines the type of failure detected in the subsystem identified by an SPN.";
CM_ SG_ 2566835456 FailureModeIdentifier5 "The FMI defines the type of failure detected in the subsystem identified by an SPN.";
CM_ SG_ 2566835456 FailureModeIdentifier4 "The FMI defines the type of failure detected in the subsystem identified by an SPN.";
CM_ SG_ 2566835456 FailureModeIdentifier3 "The FMI defines the type of failure detected in the subsystem identified by an SPN.";
CM_ SG_ 2566835456 FailureModeIdentifier2 "The FMI defines the type of failure detected in the subsystem identified by an SPN.";
CM_ SG_ 2566835456 FailureModeIdentifier10 "The FMI defines the type of failure detected in the subsystem identified by an SPN.";
CM_ SG_ 2566835456 FailureModeIdentifier1 "The FMI defines the type of failure detected in the subsystem identified by an SPN.";
CM_ BO_ 2566845696 "Ambient Conditions";
CM_ SG_ 2566845696 BarometricPressure "Absolute air pressure of the atmosphere.";
CM_ SG_ 2566845952 EngIntakeManifoldTemp "To be completed";
CM_ SG_ 2566845952 EngIntakeManifoldPress "To be completed";
CM_ BO_ 2566846467 "Transmission Fluids 1";
CM_ SG_ 2566846467 TransOilLevelMeasSts "Measurement status of oil level measurement";
CM_ SG_ 2566846467 TransOilLevelCountdown "To be completed";
CM_ SG_ 2566846467 TransOilLevelHL "differential oil level in liter";
CM_ SG_ 2566846467 TransOilTemp "First instance of transmission lubricant temperature.
See also SPN 177";
CM_ SG_ 2566846467 TransOilPress "Gage pressure of lubrication fluid in transmission, measured after pump.";
CM_ SG_ 2566846467 TransFilterDiffPress "To be completed";
CM_ SG_ 2566846467 TransOilLevel "The signal shall be used by the CP to know the current Transmission Oil Level value.
The significant values for the signal are:
0% = not fullfilled (0x00);
2% = oil level ok (0x05);
4% = oil level too high (0x0A);
6% = oil level too low (0x0F);
8% = Error (0x15);";
CM_ SG_ 2566846467 ClutchPress "Gage pressure of oil within a wet clutch.";
CM_ BO_ 2566846208 "Vehicle Electrical Power #1";
CM_ SG_ 2566846208 BatteryPotentialSwitched "Electrical potential measured at the input of the electronic control unit supplied through a switching device.";
CM_ SG_ 2566873377 EngineShutdownSwitch "The signal shall be set by the BODY to define theAuxiliary Shutdown request.";
CM_ SG_ 2566873377 ParkingBrakeSwitch_BC2EDC2 "The signal shall be set by the BODY to define a feedback to Engine about the Park Brake activation/deactivation status.";
CM_ SG_ 2566844672 CruiseControlSetSpeed "To be completed";
CM_ SG_ 2566844672 CruiseControlAccelerateSwitch "To be completed";
CM_ SG_ 2566844672 CruiseControlResumeSwitch "To be completed";
CM_ SG_ 2566844672 CruiseControlDecelerateSwt "To be completed";
CM_ SG_ 2566844672 CruiseControlSetSwitch "To be completed";
CM_ SG_ 2566844672 BrakeSwitch "Switch signal which indicates that the driver operated brake foot pedal is being pressed. This brake foot pedal is
controlling the vehicles’ service brake (total vehicle braking application, not park brakes). It is necessary for safe
drivetrain behavior that the switch activates before the physical braking components are activated (i.e. Disengage the
cruise control function prior to the activation of friction brakes)..
See also SPN 597";
CM_ SG_ 2566844672 CruiseControlEnableSwitch "To be completed";
CM_ SG_ 2566844672 CruiseControlActive "To be completed";
CM_ SG_ 2566844672 WheelBasedVehicleSpeed "To be completed";
CM_ SG_ 2566844672 ParkingBrakeSwitch_CCVS_EEC "Switch signal which indicates when the parking brake is set. In general the switch actuated by the operator's park brake
control, whether a pedal, lever or other control mechanism (see also SPN 619 and 5275).
See also SPN 70";
CM_ SG_ 2566848256 WaterInFuelIndicator "The signal shall be used by the BODY to know whether water is present or not in the fuel filter. 
It shall be received from CAN as per Requirement SYS_CAN_1260.
The significant values of the signal shall be:
- True: it indicates that water is present;
- False: it indicates that water is not present;
All the allowable values of the signal are detailed in CAN database.";
CM_ SG_ 2566754816 EngineDerateRequest "To be completed";
CM_ SG_ 2566754816 EmergencySwitchStatus "The signal shall be used by the BODY to know the Battle Switch Status (or Emergency switch status).";
CM_ SG_ 2566754816 EngineOperatingState "To be completed";
CM_ SG_ 2566841344 EngProtectSystHasShutdownEngine "To be completed";
CM_ SG_ 2566841344 WaitToStartLamp "To be completed";
CM_ SG_ 2566857216 CloggedOilFilterStatus "This signal indicates if the oil filter is clogged.
At present, the allowed values are: 0x00 and 0x01, the value 0x02 is not managed.";
CM_ SG_ 2566857216 CloggedFuelFilterStatus "This signal indicates if the fuel filter is clogged.
At present, the allowed values are: 0x00 and 0x01, the value 0x02 is not managed.";
CM_ SG_ 2566856960 ECMFuellingState "The signal shall be used to know the ECM fueling status";
CM_ SG_ 2566856960 MaxVehicleSpeedLimitationSetpoin "The signal shall be used to know the Maximum vehicle speed limitation setpoint";
CM_ SG_ 2566856960 SpeedLimiterStatus "The signal shall be used to know the Speed Limiter Status";
CM_ SG_ 2566856960 EDCOperationalStatus "The signal shall be used to know the EDC Operational Status";
CM_ SG_ 2566856960 EngineDegradationLevel "The signal shall be used to know the Engine degradation level";
CM_ SG_ 2566856960 EngineOilTemperatureHigh "The signal shall be used by the CPx to know the Engile Oil Temperature lamp command.";
CM_ SG_ 2566856960 FuelFilterHeaterStatus "The signal shall be used to know the Fuel Filter Heater Status";
CM_ SG_ 2566856960 EngineOilPressureLow "The signal shall be used to control the Engine Oil Pressure Low lamp command.";
CM_ SG_ 2566856960 EngineOverTemperature "The signal shall be used to know the Engine Coolant Temperature lamp command.";
CM_ SG_ 2566856960 EngineOverspeed "The signal shall be used to know the Engine Overspeed Status";
CM_ SG_ 2566856960 ColdStartHeaterStatus "The signal shall be used to know the Cold Start Heater Status";
CM_ SG_ 2565406464 PGN "To be completed";
CM_ SG_ 2565406464 Status "To be completed";
CM_ BO_ 2564432382 "Diagnostic message - used for tester communication";
CM_ SG_ 2564432382 can0_diagrx_0 "Diagnostic signal - used for tester communication";
CM_ SG_ 2564432382 can0_diagrx_1 "Diagnostic signal - used for tester communication";
CM_ SG_ 2564432382 can0_diagrx_2 "Diagnostic signal - used for tester communication";
CM_ SG_ 2564432382 can0_diagrx_3 "Diagnostic signal - used for tester communication";
CM_ SG_ 2564432382 can0_diagrx_4 "Diagnostic signal - used for tester communication";
CM_ SG_ 2564432382 can0_diagrx_5 "Diagnostic signal - used for tester communication";
CM_ SG_ 2564432382 can0_diagrx_6 "Diagnostic signal - used for tester communication";
CM_ SG_ 2564432382 can0_diagrx_7 "Diagnostic signal - used for tester communication";
CM_ BO_ 2564485409 "Diagnostic message - used for tester communication";
CM_ SG_ 2564485409 can0_diagtx_0 "Diagnostic signal - used for tester communication";
CM_ SG_ 2564485409 can0_diagtx_1 "Diagnostic signal - used for tester communication";
CM_ SG_ 2564485409 can0_diagtx_2 "Diagnostic signal - used for tester communication";
CM_ SG_ 2564485409 can0_diagtx_3 "Diagnostic signal - used for tester communication";
CM_ SG_ 2564485409 can0_diagtx_4 "Diagnostic signal - used for tester communication";
CM_ SG_ 2564485409 can0_diagtx_5 "Diagnostic signal - used for tester communication";
CM_ SG_ 2564485409 can0_diagtx_6 "Diagnostic signal - used for tester communication";
CM_ SG_ 2564485409 can0_diagtx_7 "Diagnostic signal - used for tester communication";
CM_ BO_ 2632777505 "Diagnostic message - used for tester communication";
CM_ SG_ 2632777505 can0_tpcm_byte0 "Diagnostic signal - used for tester communication";
CM_ SG_ 2632777505 can0_tpcm_byte1 "Diagnostic signal - used for tester communication";
CM_ SG_ 2632777505 can0_tpcm_byte2 "Diagnostic signal - used for tester communication";
CM_ SG_ 2632777505 can0_tpcm_byte3 "Diagnostic signal - used for tester communication";
CM_ SG_ 2632777505 can0_tpcm_byte4 "Diagnostic signal - used for tester communication";
CM_ SG_ 2632777505 can0_tpcm_byte5 "Diagnostic signal - used for tester communication";
CM_ SG_ 2632777505 can0_tpcm_byte6 "Diagnostic signal - used for tester communication";
CM_ SG_ 2632777505 can0_tpcm_byte7 "Diagnostic signal - used for tester communication";
CM_ BO_ 2632711969 "Diagnostic message - used for tester communication";
CM_ SG_ 2632711969 can0_tpdt_byte0 "Diagnostic signal - used for tester communication";
CM_ SG_ 2632711969 can0_tpdt_byte1 "Diagnostic signal - used for tester communication";
CM_ SG_ 2632711969 can0_tpdt_byte2 "Diagnostic signal - used for tester communication";
CM_ SG_ 2632711969 can0_tpdt_byte3 "Diagnostic signal - used for tester communication";
CM_ SG_ 2632711969 can0_tpdt_byte4 "Diagnostic signal - used for tester communication";
CM_ SG_ 2632711969 can0_tpdt_byte5 "Diagnostic signal - used for tester communication";
CM_ SG_ 2632711969 can0_tpdt_byte6 "Diagnostic signal - used for tester communication";
CM_ SG_ 2632711969 can0_tpdt_byte7 "Diagnostic signal - used for tester communication";
CM_ SG_ 2566841884 VDB_Local_hour_offset "SPN 1602 Local hour offset
The hour component of the offset between the UTC (Universal Time Coordinate) time and date and a local time zone time
and date. This is the number of hours to add to UTC, a.k.a. GMT, time and date to convert to the time and date in the
local time zone. This parameter indicates the time reference of the data reported in the Time and Date SPNs 959, 960.
961, 962, 963, and 964. The Local Offset is a positive value for time zones East of the Prime Meridian to the International
Date Line. The Local Offset is a negative value for time zones West of the Prime Meridian to the International Date Line.
The Local Hour Offset is only applicable when the Time and Date parameters are reported as UTC time and date.
Recommended Settings:
Applications should not use the $FF 'Not Available' if using the Time and Date parameters due to some ambiguity of the
time standard for the reported time and date values. The recommended settings for the Local Hour Offset settings are:
If reporting the ";
CM_ SG_ 2566841884 VDB_Local_minute_offset "The minute component of the offset between the UTC time and date and a local time zone time and date. This is the
number of minutes to add to UTC (Universal Time Coordinate) time and date to convert to the time and date in the local
time zone . The Local Offset is a positive value for time zones East of the Prime Meridian to the International Date Line.
The Local Offset is a negative value for time zones West of the Prime Meridian to the International Date Line.
The Local Minute Offset is only applicable when the Time and Date parameters are reported as UTC time and date.
Refer to SPN 1602 for details.";
CM_ SG_ 2566841884 VDB_Year "The year component of the current calendar date. This should be reported as the year component of the current date at
UTC (Universal Time Coordinate), a.k.a. GMT; however, it may be reported as the year component of the current date at
a local time zone. The Local Hour Offset parameter (SPN 1602) is used to indicate if the calendar date (SPNs 962, 963,
and 964) is the current UTC date or a local time zone date. Refer to SPN 1602 for details.
NOTE - A value of 0 for the year identifies the year 1985; a value of 1 identifies 1986; etc.";
CM_ SG_ 2566841884 VDB_Month "The month component of the current calendar date. This should be reported as the month component of the current date
at UTC (Universal Time Coordinate), a.k.a. GMT; however, it may be reported as the month component of the current
date at a local time zone. The Local Hour Offset parameter (SPN 1602) is used to indicate if the calendar date (SPNs
962, 963, and 964) is the current UTC date or a local time zone date. Refer to SPN 1602 for details.
NOTE - A value of 0 for the month is null. The value 1 identifies January; 2 identifies February; etc.";
CM_ SG_ 2566841884 VDB_Hours "The hour component of the current time of day. This should be reported as the hour component of the current time at
UTC (Universal Time Coordinate), a.k.a. GMT; however, it may be reported as the hour component of the current time at
a local time zone. The Local Hour Offset parameter (SPN 1602) is used to indicate if time of day (SPNs 959, 960, and
961) is the current UTC time or a local time zone time. Refer to SPN 1602 for details.";
CM_ SG_ 2566841884 VDB_Minutes "The minutes component of the current time of day. This should be reported as the minutes component of the current time
at UTC (Universal Time Coordinate), a.k.a. GMT; however, it may be reported as the minutes component of the current
time at a local time zone. The Local Hour Offset parameter (SPN 1602) is used to indicate if the time of day (SPNs 959,
960, and 961) is the current UTC time or a local time zone time. Refer to SPN 1602 for details.";
CM_ SG_ 2566841884 VDB_Seconds "The seconds component of the current time of day. This should be reported as the seconds component of the current
time at UTC (Universal Time Coordinate), a.k.a. GMT; however, it may be reported as the seconds component of the
current time at a local time zone. The Local Hour Offset parameter (SPN 1602) is used to indicate if the time of day
(SPNs 959, 960, and 961) is the current UTC time or a local time zone time. Refer to SPN 1602 for details.";
CM_ BO_ 2566834721 "Active diagnostic trouble codes";
CM_ BO_ 2566834942 "Active diagnostic trouble codes";
CM_ SG_ 2566834942 SPN10_Low "SPN #10 (Conversion Version 4)";
CM_ SG_ 2566834942 SPN9_Low "SPN #9 (Conversion Version 4)";
CM_ SG_ 2566834942 SPN8_Low "SPN #8 (Conversion Version 4)";
CM_ SG_ 2566834942 SPN7_Low "SPN #7 (Conversion Version 4)";
CM_ SG_ 2566834942 SPN6_Low "SPN #6 (Conversion Version 4)";
CM_ SG_ 2566834942 SPN5_Low "SPN #5 (Conversion Version 4)";
CM_ SG_ 2566834942 SPN4_Low "SPN #4 (Conversion Version 4)";
CM_ SG_ 2566834942 SPN3_Low "SPN #3 (Conversion Version 4)";
CM_ SG_ 2566834942 SPN2_Low "SPN #2 (Conversion Version 4)";
CM_ SG_ 2566834942 FailureModeIdentifier10 "The FMI defines the type of failure detected in the subsystem identified by an SPN.";
CM_ SG_ 2566834942 FailureModeIdentifier9 "The FMI defines the type of failure detected in the subsystem identified by an SPN.";
CM_ SG_ 2566834942 FailureModeIdentifier8 "The FMI defines the type of failure detected in the subsystem identified by an SPN.";
CM_ SG_ 2566834942 FailureModeIdentifier7 "The FMI defines the type of failure detected in the subsystem identified by an SPN.";
CM_ SG_ 2566834942 FailureModeIdentifier6 "The FMI defines the type of failure detected in the subsystem identified by an SPN.";
CM_ SG_ 2566834942 FailureModeIdentifier5 "The FMI defines the type of failure detected in the subsystem identified by an SPN.";
CM_ SG_ 2566834942 FailureModeIdentifier4 "The FMI defines the type of failure detected in the subsystem identified by an SPN.";
CM_ SG_ 2566834942 FailureModeIdentifier3 "The FMI defines the type of failure detected in the subsystem identified by an SPN.";
CM_ SG_ 2566834942 FlashRedStopLamp "This parameter provides the capability to flash the RSL (SPN 3039).";
CM_ SG_ 2566834942 FlashProtectLamp "This parameter provides the capability to flash the engine protect lamp (SPN 3041).";
CM_ SG_ 2566834942 FlashMalfuncIndicatorLamp "This parameter provides the capability to flash the MIL (SPN 3038).";
CM_ SG_ 2566834942 FlashAmberWarningLamp "This parameter provides the capability to flash the AWL (SPN 3040). ";
CM_ SG_ 2566834942 MalfunctionIndicatorLampStatus "A lamp used to relay only emissions-related trouble code information.";
CM_ SG_ 2566834942 AmberWarningLampStatus "This lamp is used to relay trouble code information that is reporting a problem with the vehicle system but the vehicle neednot be immediately stopped.";
CM_ SG_ 2566834942 OccurenceCount1 "The 7 bit occurence count field contains the number of times a fault has gone from active to previously active.";
CM_ SG_ 2566834942 SPNConversionMethod1 "SPN Conversion Method";
CM_ SG_ 2566834942 FailureModeIdentifier1 "The FMI defines the type of failure detected in the subsystem identified by an SPN.";
CM_ SG_ 2566834942 SPN1_Low "SPN #1 (Conversion Version 4)";
CM_ SG_ 2566834942 RedStopLampState "This lamp is uesed to relay trouble code information that is of a severe enought condition that it warrants stopping the vehicle.";
CM_ SG_ 2566834942 ProtectLampStatus "This lamp is used to relay trouble code informatio that is reporting a problem with a vehicle system that is most probably not electronic subsystem related.";
CM_ SG_ 2566834942 FailureModeIdentifier2 "The FMI defines the type of failure detected in the subsystem identified by an SPN.";
CM_ SG_ 2566834942 SPNConversionMethod10 "SPN Conversion Method";
CM_ SG_ 2566834942 SPNConversionMethod9 "SPN Conversion Method";
CM_ SG_ 2566834942 SPNConversionMethod8 "SPN Conversion Method";
CM_ SG_ 2566834942 SPNConversionMethod7 "SPN Conversion Method";
CM_ SG_ 2566834942 SPNConversionMethod6 "SPN Conversion Method";
CM_ SG_ 2566834942 SPNConversionMethod5 "SPN Conversion Method";
CM_ SG_ 2566834942 SPNConversionMethod4 "SPN Conversion Method";
CM_ SG_ 2566834942 SPNConversionMethod3 "SPN Conversion Method";
CM_ SG_ 2566834942 SPNConversionMethod2 "SPN Conversion Method";
CM_ SG_ 2566834942 OccurenceCount10 "The 7 bit occurence count field contains the number of times a fault has gone from active to previously active.";
CM_ SG_ 2566834942 OccurenceCount9 "The 7 bit occurence count field contains the number of times a fault has gone from active to previously active.";
CM_ SG_ 2566834942 OccurenceCount8 "The 7 bit occurence count field contains the number of times a fault has gone from active to previously active.";
CM_ SG_ 2566834942 OccurenceCount7 "The 7 bit occurence count field contains the number of times a fault has gone from active to previously active.";
CM_ SG_ 2566834942 OccurenceCount6 "The 7 bit occurence count field contains the number of times a fault has gone from active to previously active.";
CM_ SG_ 2566834942 OccurenceCount5 "The 7 bit occurence count field contains the number of times a fault has gone from active to previously active.";
CM_ SG_ 2566834942 OccurenceCount4 "The 7 bit occurence count field contains the number of times a fault has gone from active to previously active.";
CM_ SG_ 2566834942 OccurenceCount3 "The 7 bit occurence count field contains the number of times a fault has gone from active to previously active.";
CM_ SG_ 2566834942 OccurenceCount2 "The 7 bit occurence count field contains the number of times a fault has gone from active to previously active.";
CM_ SG_ 2566834942 SPN10_High "SPN #10 (Conversion Version 4)";
CM_ SG_ 2566834942 SPN9_High "SPN #9 (Conversion Version 4)";
CM_ SG_ 2566834942 SPN8_High "SPN #8 (Conversion Version 4)";
CM_ SG_ 2566834942 SPN7_High "SPN #7 (Conversion Version 4)";
CM_ SG_ 2566834942 SPN6_High "SPN #6 (Conversion Version 4)";
CM_ SG_ 2566834942 SPN5_High "SPN #5 (Conversion Version 4)";
CM_ SG_ 2566834942 SPN4_High "SPN #4 (Conversion Version 4)";
CM_ SG_ 2566834942 SPN3_High "SPN #3 (Conversion Version 4)";
CM_ SG_ 2566834942 SPN2_High "SPN #2 (Conversion Version 4)";
CM_ SG_ 2566834942 SPN1_High "SPN #1 (Conversion Version 4)";
BA_DEF_ BO_  "GenMsgCycleTimeFast" INT 0 3600000;
BA_DEF_ BO_  "GenMsgDelayTime" INT 0 3600000;
BA_DEF_ BO_  "GenMsgStartDelayTime" INT 0 10000;
BA_DEF_ BO_  "GenMsgSendType" ENUM  "cyclic","reserved","cyclicIfActive","reserved","reserved","reserved","reserved","reserved","noMsgSendType";
BA_DEF_ BO_  "GenMsgCycleTime" INT 0 3600000;
BA_DEF_ BO_  "GenMsgILSupport" ENUM  "No","Yes";
BA_DEF_ BO_  "VFrameFormat" ENUM  "StandardCAN","ExtendedCAN","reserved","J1939PG";
BA_DEF_ BO_  "GenMsgSendTypex" ENUM  "cyclic","reserved","cyclicIfActive","reserved","reserved","reserved","reserved","reserved","noMsgSendType";
BA_DEF_ BO_  "GenMsgRequestable" INT 0 1;
BA_DEF_ BO_  "GenMsgSencmype" ENUM  "cyclic","reserved","cyclicIfActive","reserved","reserved","reserved","reserved","reserved","noMsgSencmype";
BA_DEF_ BO_  "GenMsgSencmypex" ENUM  "cyclic","reserved","cyclicIfActive","reserved","reserved","reserved","reserved","reserved","noMsgSencmype";
BA_DEF_ SG_  "GenSigSendType" ENUM  "Cyclic","OnWrite","reserved","OnChange","reserved","reserved","reserved","NoSigSendType";
BA_DEF_ SG_  "GenSigStartValue" INT 0 10000;
BA_DEF_ SG_  "GenSigEVName" STRING ;
BA_DEF_ SG_  "GenSigILSupport" ENUM  "Yes","No";
BA_DEF_ SG_  "GenSigSendTypex" ENUM  "Cyclic","OnWrite","reserved","OnChange","reserved","reserved","reserved","NoSigSendType";
BA_DEF_ SG_  "SPN" INT 0 524287;
BA_DEF_ SG_  "GenSigSencmype" ENUM  "Cyclic","OnWrite","reserved","OnChange","reserved","reserved","reserved","NoSigSencmype";
BA_DEF_ SG_  "GenSigSencmypex" ENUM  "Cyclic","OnWrite","reserved","OnChange","reserved","reserved","reserved","NoSigSencmype";
BA_DEF_DEF_  "GenMsgCycleTimeFast" 0;
BA_DEF_DEF_  "GenMsgDelayTime" 0;
BA_DEF_DEF_  "GenMsgStartDelayTime" 0;
BA_DEF_DEF_  "GenMsgSendType" "noMsgSendType";
BA_DEF_DEF_  "GenMsgCycleTime" 0;
BA_DEF_DEF_  "GenMsgILSupport" "Yes";
BA_DEF_DEF_  "VFrameFormat" "J1939PG";
BA_DEF_DEF_  "GenMsgSendTypex" "noMsgSendType";
BA_DEF_DEF_  "GenMsgRequestable" 1;
BA_DEF_DEF_  "GenMsgSencmype" "noMsgSencmype";
BA_DEF_DEF_  "GenMsgSencmypex" "noMsgSencmype";
BA_DEF_DEF_  "GenSigSendType" "NoSigSendType";
BA_DEF_DEF_  "GenSigStartValue" 0;
BA_DEF_DEF_  "GenSigEVName" "Env@Nodename_@Signame";
BA_DEF_DEF_  "GenSigILSupport" "Yes";
BA_DEF_DEF_  "GenSigSendTypex" "NoSigSendType";
BA_DEF_DEF_  "SPN" 0;
BA_DEF_DEF_  "GenSigSencmype" "NoSigSencmype";
BA_DEF_DEF_  "GenSigSencmypex" "NoSigSencmype";
BA_ "GenMsgCycleTime" BO_ 2365526021 50;
BA_ "GenMsgSendType" BO_ 2365526021 0;
BA_ "GenMsgCycleTime" BO_ 2348876549 50;
BA_ "GenMsgSendType" BO_ 2348876549 0;
BA_ "GenMsgCycleTime" BO_ 2348876577 50;
BA_ "GenMsgSendType" BO_ 2348876577 0;
BA_ "GenMsgCycleTime" BO_ 2566803994 1000;
BA_ "GenMsgSendType" BO_ 2566803994 0;
BA_ "GenMsgCycleTime" BO_ 2566899738 1000;
BA_ "GenMsgSendType" BO_ 2566899738 0;
BA_ "GenMsgCycleTime" BO_ 2566837530 1000;
BA_ "GenMsgSendType" BO_ 2566837530 0;
BA_ "GenMsgCycleTime" BO_ 2566900723 1000;
BA_ "GenMsgSendType" BO_ 2566900723 0;
BA_ "GenMsgCycleTime" BO_ 2633922849 5000;
BA_ "GenMsgSendType" BO_ 2633922849 2;
BA_ "GenMsgCycleTime" BO_ 2633922593 5000;
BA_ "GenMsgSendType" BO_ 2633922593 2;
BA_ "GenMsgCycleTime" BO_ 2566841600 1000;
BA_ "GenMsgSendType" BO_ 2566841600 2;
BA_ "GenMsgCycleTime" BO_ 2348810243 10;
BA_ "GenMsgSendType" BO_ 2348810243 0;
BA_ "GenMsgCycleTime" BO_ 2633923123 5000;
BA_ "GenMsgSendType" BO_ 2633923123 2;
BA_ "GenMsgCycleTime" BO_ 2633922867 5000;
BA_ "GenMsgSendType" BO_ 2633922867 2;
BA_ "GenMsgCycleTime" BO_ 2633922611 5000;
BA_ "GenMsgSendType" BO_ 2633922611 2;
BA_ "GenMsgCycleTime" BO_ 2566845491 2500;
BA_ "GenMsgSendType" BO_ 2566845491 0;
BA_ "GenMsgCycleTime" BO_ 2365484270 50;
BA_ "GenMsgSendType" BO_ 2365484270 0;
BA_ "GenMsgSendType" BO_ 2566840835 2;
BA_ "GenMsgCycleTime" BO_ 2566847248 1000;
BA_ "GenMsgSendType" BO_ 2566847248 0;
BA_ "GenMsgCycleTime" BO_ 2566840592 5000;
BA_ "GenMsgSendType" BO_ 2566840592 0;
BA_ "GenMsgCycleTimeFast" BO_ 2566840592 1000;
BA_ "GenMsgCycleTime" BO_ 2566844928 100;
BA_ "GenMsgSendType" BO_ 2566844928 0;
BA_ "GenMsgSendType" BO_ 2566842624 2;
BA_ "GenMsgCycleTime" BO_ 2566801923 100;
BA_ "GenMsgSendType" BO_ 2566801923 0;
BA_ "GenMsgCycleTime" BO_ 2565866755 100;
BA_ "GenMsgSendType" BO_ 2565866755 0;
BA_ "GenMsgCycleTime" BO_ 2364539395 10;
BA_ "GenMsgSendType" BO_ 2364539395 0;
BA_ "GenMsgCycleTime" BO_ 2566843904 1000;
BA_ "GenMsgSendType" BO_ 2566843904 0;
BA_ "GenMsgCycleTime" BO_ 2565865488 100;
BA_ "GenMsgSendType" BO_ 2565865488 0;
BA_ "GenMsgCycleTime" BO_ 2566844160 500;
BA_ "GenMsgSendType" BO_ 2566844160 0;
BA_ "GenMsgCycleTime" BO_ 2566840064 250;
BA_ "GenMsgSendType" BO_ 2566840064 0;
BA_ "GenMsgCycleTime" BO_ 2364539648 50;
BA_ "GenMsgSendType" BO_ 2364539648 0;
BA_ "GenMsgCycleTime" BO_ 2364539904 10;
BA_ "GenMsgSendType" BO_ 2364539904 0;
BA_ "GenMsgCycleTime" BO_ 2566841088 5000;
BA_ "GenMsgSendType" BO_ 2566841088 2;
BA_ "GenMsgCycleTime" BO_ 2566834944 1000;
BA_ "GenMsgSendType" BO_ 2566834944 2;
BA_ "GenMsgCycleTime" BO_ 2566835456 1000;
BA_ "GenMsgSendType" BO_ 2566835456 2;
BA_ "GenMsgCycleTime" BO_ 2566845696 1000;
BA_ "GenMsgSendType" BO_ 2566845696 0;
BA_ "GenMsgCycleTime" BO_ 2566845952 500;
BA_ "GenMsgSendType" BO_ 2566845952 0;
BA_ "GenMsgCycleTime" BO_ 2566846467 1000;
BA_ "GenMsgSendType" BO_ 2566846467 0;
BA_ "GenMsgCycleTime" BO_ 2566846208 1000;
BA_ "GenMsgSendType" BO_ 2566846208 0;
BA_ "GenMsgCycleTime" BO_ 2566873377 250;
BA_ "GenMsgSendType" BO_ 2566873377 0;
BA_ "GenMsgCycleTime" BO_ 2566844672 100;
BA_ "GenMsgSendType" BO_ 2566844672 0;
BA_ "GenMsgCycleTime" BO_ 2566848256 1000;
BA_ "GenMsgSendType" BO_ 2566848256 0;
BA_ "GenMsgCycleTime" BO_ 2566754816 250;
BA_ "GenMsgSendType" BO_ 2566754816 0;
BA_ "GenMsgCycleTime" BO_ 2566841344 1000;
BA_ "GenMsgSendType" BO_ 2566841344 0;
BA_ "GenMsgCycleTime" BO_ 2566857216 100;
BA_ "GenMsgSendType" BO_ 2566857216 0;
BA_ "GenMsgCycleTime" BO_ 2566856960 50;
BA_ "GenMsgSendType" BO_ 2566856960 0;
BA_ "GenMsgCycleTime" BO_ 2566841884 100;
BA_ "GenMsgCycleTime" BO_ 2566834721 1000;
BA_ "GenMsgCycleTime" BO_ 2566834942 1000;
BA_ "GenSigStartValue" SG_ 2348876549 TransRqedGear_gw 125;
BA_ "GenSigStartValue" SG_ 2348876577 TransRqedGear_bc 125;
BA_ "GenSigStartValue" SG_ 2566899738 Alt_WarningLight 252;
BA_ "GenSigStartValue" SG_ 2566899738 Alt_LedStatus 1;
BA_ "GenSigStartValue" SG_ 2566899738 Alt_BatteryTemperature 40;
BA_ "GenSigStartValue" SG_ 2566899966 Alt_OVCO_Reset_01 26;
BA_ "GenSigStartValue" SG_ 2566899966 Alt_OVCO_Reset_02 43;
BA_ "GenSigStartValue" SG_ 2566899966 Alt_OVCO_Reset_06 255;
BA_ "GenSigStartValue" SG_ 2566899966 Alt_OVCO_Reset_07 255;
BA_ "GenSigStartValue" SG_ 2566899966 Alt_OVCO_Reset_08 255;
BA_ "GenSigStartValue" SG_ 2566900222 Alt_DL_Request_01 26;
BA_ "GenSigStartValue" SG_ 2566900222 Alt_DL_Request_02 43;
BA_ "GenSigStartValue" SG_ 2566900222 Alt_DL_Request_06 255;
BA_ "GenSigStartValue" SG_ 2566900222 Alt_DL_Request_07 255;
BA_ "GenSigStartValue" SG_ 2566900222 Alt_DL_Request_08 255;
BA_ "GenSigStartValue" SG_ 2566843904 EngOilTemp1 8736;
BA_ "GenSigStartValue" SG_ 2566840064 EstEngPrsticLossesPercentTq 125;
BA_ "SPN" SG_ 2364539648 Eng_PercentLoadAtCurrentSpeed 92;
BA_ "GenSigStartValue" SG_ 2566846467 TransOilLevelHL 125;
BA_ "GenSigStartValue" SG_ 2566846467 TransOilTemp 8736;
BA_ "GenSigStartValue" SG_ 2566841884 VDB_Local_hour_offset 125;
BA_ "GenSigStartValue" SG_ 2566841884 VDB_Local_minute_offset 125;
BA_ "GenSigStartValue" SG_ 2566841884 VDB_Month 1;
VAL_ 2365526021 ADM1 3 "NotAvailable" 2 "Error" 1 "Active" 0 "Inactive" ;
VAL_ 2365526021 ADM2 3 "NotAvailable" 2 "Error" 1 "Active" 0 "Inactive" ;
VAL_ 2365526021 ADM3 3 "NotAvailable" 2 "Error" 1 "Active" 0 "Inactive" ;
VAL_ 2365526021 ADM4 3 "NotAvailable" 2 "Error" 1 "Active" 0 "Inactive" ;
VAL_ 2365526021 ADP1 3 "NotAvailable" 2 "Error" 1 "Active" 0 "Inactive" ;
VAL_ 2365526021 ADP2 3 "NotAvailable" 2 "Error" 1 "Active" 0 "Inactive" ;
VAL_ 2365526021 ADP3 3 "NotAvailable" 2 "Error" 1 "Active" 0 "Inactive" ;
VAL_ 2365526021 ADP4 3 "NotAvailable" 2 "Error" 1 "Active" 0 "Inactive" ;
VAL_ 2365526021 EDM1 3 "NotAvailable" 2 "Error" 1 "Active" 0 "Inactive" ;
VAL_ 2365526021 EDM2 3 "NotAvailable" 2 "Error" 1 "Active" 0 "Inactive" ;
VAL_ 2365526021 EDP3 3 "NotAvailable" 2 "Error" 1 "Active" 0 "Inactive" ;
VAL_ 2365526021 EDP4 3 "NotAvailable" 2 "Error" 1 "Active" 0 "Inactive" ;
VAL_ 2365526021 AVP_Lever_Interlock 3 "NotAvailable" 2 "Error" 1 "Active" 0 "Inactive" ;
VAL_ 2348876549 DisengageDiffLockRqCntRear_gw 2 "Reserved" 3 "TakeNoAction" 1 "DisengageDiffLock" 0 "EngageDiffLock" ;
VAL_ 2348876549 DisengageDiffLockRqCntFront_gw 2 "Reserved" 3 "TakeNoAction" 1 "DisengageDiffLock" 0 "EngageDiffLock" ;
VAL_ 2348876549 DisengageDiffLockRqCnt_gw 2 "Reserved" 3 "TakeNoAction" 1 "DisengageDiffLock" 0 "EngageDiffLock" ;
VAL_ 2348876549 DisengageDiffLockRqRearAxle2_gw 2 "Reserved" 3 "TakeNoAction" 1 "DisengageDiffLock" 0 "EngageDiffLock" ;
VAL_ 2348876549 DisengageDiffLockRqRearAxle1_gw 2 "Reserved" 3 "TakeNoAction" 1 "DisengageDiffLock" 0 "EngageDiffLock" ;
VAL_ 2348876549 DisengageDiffLockRqFrontAxle2_gw 2 "Reserved" 3 "TakeNoAction" 1 "DisengageDiffLock" 0 "EngageDiffLock" ;
VAL_ 2348876549 DisengageDiffLockRqFrontAxle1_gw 2 "Reserved" 3 "TakeNoAction" 1 "DisengageDiffLock" 0 "EngageDiffLock" ;
VAL_ 2348876549 TransRqedGear_gw 61 "Reserved" 222 "NeutralSelectorPos" 223 "ReverseSelectorPos" 224 "PsUnknownAnd_OrNoButtonsPressed" 225 "PrssOfMmntryBttnTRslctCrrentPos" 226 "BtwnRvrsAndPrkShiftSelectorPoss" 227 "BtwnNtrlAndRvrsShftSelectorPoss" 228 "BtwnDrvAndNtrlShiftSelectorPoss" 229 "BtwnD1AndDriveShiftSelectorPoss" 230 "BetweenD2AndD1ShiftSelectorPoss" 231 "BetweenD3AndD2ShiftSelectorPoss" 232 "BetweenD4AndD3ShiftSelectorPoss" 233 "BetweenD5AndD4ShiftSelectorPoss" 234 "BetweenD6AndD5ShiftSelectorPoss" 235 "BetweenD7AndD6ShiftSelectorPoss" 236 "BtwnTwoForwardShiftSelectorPoss" 237 "BtwnTwoReverseShiftSelectorPoss" 238 "BetweenTwoShiftSelectorPoss" 239 "D77thFrwrdSlctrPsRfrncdFrmDrive" 240 "D66thFrwrdSlctrPsRfrncdFrmDrive" 241 "D55thFrwrdSlctrPsRfrncdFrmDrive" 242 "D44thFrwrdSlctrPsRfrncdFrmDrive" 243 "D33rdFrwrdSlctrPsRfrncdFrmDrive" 244 "D22ndFrwrdSlctrPsRfrncdFrmDrive" 245 "D11stFrwrdSlctrPsRfrncdFrmDrive" 246 "Downshift2GearsFromCurrentPos" 247 "Downshift1GearFromCurrentPos" 248 "Upshift2GearsFromCurrentPos" 249 "Upshift1GearFromCurrentPos" 250 "ForwardLowPos" 251 "ParkPos" 252 "ForwardDrivePos" 253 "HoldCurrentGear" ;
VAL_ 2348876549 DisengageDrivelineRq_gw 2 "Reserved" 3 "TakeNoAction" 1 "DisengageDriveline" 0 "AllowDrivelineEngagement" ;
VAL_ 2348876549 TorqueConvLockupDisableRq_gw 2 "Reserved" 3 "TakeNoAction" 1 "DisableTorqueConvertorLockup" 0 "AllowTorqueConvertorLockup" ;
VAL_ 2348876549 TransGearShiftInhibitRq_gw 2 "Reserved" 3 "TakeNoAction" 1 "GearShiftsAreInhibited" 0 "GearShiftsAreAllowed" ;
VAL_ 2348876549 Reserved_TC1_GW_01 0 "Not_Used" ;
VAL_ 2348876549 Reserved_TC1_GW_02 0 "Not_Used" ;
VAL_ 2348876549 Reserved_TC1_GW_03 0 "Not_Used" ;
VAL_ 2348876577 TransMode4_bc 3 "TakeNoAction" 2 "Reserved" 1 "Enable" 0 "Disable" ;
VAL_ 2348876577 TransMode3_bc 3 "TakeNoAction" 2 "Reserved" 1 "Enable" 0 "Disable" ;
VAL_ 2348876577 TransMode2_bc 3 "TakeNoAction" 2 "Reserved" 1 "Enable" 0 "Disable" ;
VAL_ 2348876577 TransMode1_bc 3 "TakeNoAction" 2 "Reserved" 1 "Enable" 0 "Disable" ;
VAL_ 2348876577 DisengageDiffLockRqCntRear_bc 2 "Reserved" 3 "TakeNoAction" 1 "DisengageDiffLock" 0 "EngageDiffLock" ;
VAL_ 2348876577 DisengageDiffLockRqCntFront_bc 2 "Reserved" 3 "TakeNoAction" 1 "DisengageDiffLock" 0 "EngageDiffLock" ;
VAL_ 2348876577 DisengageDiffLockRqCnt_bc 2 "Reserved" 3 "TakeNoAction" 1 "DisengageDiffLock" 0 "EngageDiffLock" ;
VAL_ 2348876577 DisengageDiffLockRqRearAxle2_bc 2 "Reserved" 3 "TakeNoAction" 1 "DisengageDiffLock" 0 "EngageDiffLock" ;
VAL_ 2348876577 DisengageDiffLockRqRearAxle1_bc 2 "Reserved" 3 "TakeNoAction" 1 "DisengageDiffLock" 0 "EngageDiffLock" ;
VAL_ 2348876577 DisengageDiffLockRqFrontAxle2_bc 2 "Reserved" 3 "TakeNoAction" 1 "DisengageDiffLock" 0 "EngageDiffLock" ;
VAL_ 2348876577 DisengageDiffLockRqFrontAxle1_bc 2 "Reserved" 3 "TakeNoAction" 1 "DisengageDiffLock" 0 "EngageDiffLock" ;
VAL_ 2348876577 TransRqedGear_bc 61 "Reserved" 222 "NeutralSelectorPos" 223 "ReverseSelectorPos" 224 "PsUnknownAnd_OrNoButtonsPressed" 225 "PrssOfMmntryBttnTRslctCrrentPos" 226 "BtwnRvrsAndPrkShiftSelectorPoss" 227 "BtwnNtrlAndRvrsShftSelectorPoss" 228 "BtwnDrvAndNtrlShiftSelectorPoss" 229 "BtwnD1AndDriveShiftSelectorPoss" 230 "BetweenD2AndD1ShiftSelectorPoss" 231 "BetweenD3AndD2ShiftSelectorPoss" 232 "BetweenD4AndD3ShiftSelectorPoss" 233 "BetweenD5AndD4ShiftSelectorPoss" 234 "BetweenD6AndD5ShiftSelectorPoss" 235 "BetweenD7AndD6ShiftSelectorPoss" 236 "BtwnTwoForwardShiftSelectorPoss" 237 "BtwnTwoReverseShiftSelectorPoss" 238 "BetweenTwoShiftSelectorPoss" 239 "D77thFrwrdSlctrPsRfrncdFrmDrive" 240 "D66thFrwrdSlctrPsRfrncdFrmDrive" 241 "D55thFrwrdSlctrPsRfrncdFrmDrive" 242 "D44thFrwrdSlctrPsRfrncdFrmDrive" 243 "D33rdFrwrdSlctrPsRfrncdFrmDrive" 244 "D22ndFrwrdSlctrPsRfrncdFrmDrive" 245 "D11stFrwrdSlctrPsRfrncdFrmDrive" 246 "Downshift2GearsFromCurrentPos" 247 "Downshift1GearFromCurrentPos" 248 "Upshift2GearsFromCurrentPos" 249 "Upshift1GearFromCurrentPos" 250 "ForwardLowPos" 251 "ParkPos" 252 "ForwardDrivePos" 253 "HoldCurrentGear" ;
VAL_ 2348876577 DisengageDrivelineRq_bc 2 "Reserved" 3 "TakeNoAction" 1 "DisengageDriveline" 0 "AllowDrivelineEngagement" ;
VAL_ 2348876577 TorqueConvLockupDisableRq_bc 2 "Reserved" 3 "TakeNoAction" 1 "DisableTorqueConvertorLockup" 0 "AllowTorqueConvertorLockup" ;
VAL_ 2348876577 TransGearShiftInhibitRq_bc 2 "Reserved" 3 "TakeNoAction" 1 "GearShiftsAreInhibited" 0 "GearShiftsAreAllowed" ;
VAL_ 2348876577 Reserved_TC1_BC_01 0 "Not_Used" ;
VAL_ 2348876577 Reserved_TC1_BC_02 0 "Not_Used" ;
VAL_ 2348876577 Reserved_TC1_BC_03 0 "Not_Used" ;
VAL_ 2348876577 Reserved_TC1_BC_04 0 "Not_Used" ;
VAL_ 2566899738 Alt_WarningLight 252 "WARNING_LIGHT_OFF" 253 "WARNING_LIGHT_ON" ;
VAL_ 2566899738 Alt_LedStatus 4 "FLASHING_AMBER" 3 "SOLID_AMBER" 2 "FLASHING_GREEN" 1 "SOLID_GREEN" ;
VAL_ 2633922849 Selected_Load_Mode_TP2_BODY 7 "Unknown" 6 "Not_Defined" 5 "Not_Defined" 4 "Not_Defined" 3 "Not_Defined" 2 "Full_Load" 1 "Half_Load" 0 "Empty" ;
VAL_ 2633922849 Selected_Terrain_Mode_TP2_BODY 7 "Unknown" 6 "NotDefined" 5 "NotDefined" 4 "NotDefined" 3 "Emergency_Critic" 2 "Sand_Mud_Snow" 1 "Track_Trail" 0 "Road" ;
VAL_ 2633922593 TirePressCheckInterval_TP1_BODY 2 "Startup_Wait_Mode" 1 "Normal_Check" 0 "Fast_Check" ;
VAL_ 2348810243 EngineRequestedTq_HR_TSC1_TE 15 "N/A" 14 "N/A" 13 "N/A" 12 "N/A" 11 "N/A" 10 "N/A" 9 "N/A" 8 "N/A" 7 "Additional_torque__+_0.875%" 6 "Additional_torque__+_0.750%" 5 "Additional_torque__+_0.625%" 4 "Additional_torque__+_0.500%" 3 "Additional_torque__+_0.375%" 2 "Additional_torque__+_0.250%" 1 "Additional_torque__+_0.125%" 0 "Additional_torque__+_0.000%" ;
VAL_ 2348810243 ControlPurpose_TSC1_TE 5 "TemporaryPowerTrainControl" 4 "EngineProtection" 3 "RoadSpeedGovernor" 2 "PTOGovernor" 1 "CruiseControl" 0 "AcceleratorPedal" ;
VAL_ 2348810243 TransmissionRate_TSC1_TE 7 "UseStandardRate" 6 "25ms" 5 "50ms" 4 "100ms" 3 "250ms" 2 "500ms" 1 "750ms" 0 "1000ms" ;
VAL_ 2348810243 EngOverrideCtrlMode_TSC1_TE 3 "Spd_TrqLmtCtrlLmtSpdAnd_OrTrqBs" 2 "TrqCtrlCntrlTrqTInclddDsrdTrqVl" 1 "SpdCtrlGvrnSpdTInclddDsrdSpdVle" 0 "OvrrdDsbldDsblAnyExstngCtrlCmdd" ;
VAL_ 2348810243 OverrideCtrlModPriority_TSC1_TE 3 "LowPriority" 2 "MdmPrrtyUsdFrPwrtrnCtrlOprtnsWh" 1 "HighPriority" 0 "HghstPrrtyUsdFrSttnsThtRqrImmdt" ;
VAL_ 2348810243 EngRqedSpeedCtrlCondit_TSC1_TE 2 "ThsCtrlCndtnHsBnOptmzdTMnmzRpmO" 3 "StbltyOptmzdFrDrvlnEnggdAnd_OrI" 1 "StbltyOptmzdFrDrvlnDsnggdAndNnl" 0 "ThsSpdGvrnrGnSlctnIsAdjstdTPrvd" ;
VAL_ 2633923123 Current_Load_Mode 7 "Unknown" 6 "Not_Defined" 5 "Not_Defined" 4 "Not_Defined" 3 "Not_Defined" 2 "Full_Load" 1 "Half_Load" 0 "Empty" ;
VAL_ 2633923123 Current_Terrain_Mode 7 "Unknown" 6 "NotDefined" 5 "NotDefined" 4 "NotDefined" 3 "Emergency_Critic" 2 "Sand_Mud_Snow" 1 "Track_Trail" 0 "Road" ;
VAL_ 2633922867 Selected_Load_Mode_TP2 7 "Unknown" 6 "Not_Defined" 5 "Not_Defined" 4 "Not_Defined" 3 "Not_Defined" 2 "Full_Load" 1 "Half_Load" 0 "Empty" ;
VAL_ 2633922867 Selected_Terrain_Mode_TP2 7 "Unknown" 6 "NotDefined" 5 "NotDefined" 4 "NotDefined" 3 "Emergency_Critic" 2 "Sand_Mud_Snow" 1 "Track_Trail" 0 "Road" ;
VAL_ 2633922611 CTISProcessMode 15 "NotAvailable" 14 "Over_speed_access_denied" 13 "Over_speed_condition" 12 "Over_speed_automatic_inflation" 11 "NotUsed" 10 "NotUsed" 9 "NotUsed" 8 "NotUsed" 7 "NotUsed" 6 "Pressure_Check_Cycle" 5 "NotUsed" 4 "NotUsed" 3 "CTIS_Process_Operation" 2 "Deflating" 1 "Inflating" 0 "Standby" ;
VAL_ 2633922611 TirePressCheckInterval_TP1 2 "Startup_Wait_Mode" 1 "Normal_Check" 0 "Fast_Check" ;
VAL_ 2566845491 TirePressStatus 7 "Not_Available" 6 "Error_Indicator" 5 "Not_Defined" 4 "Extreme_Under_Pressure" 3 "Under_Pressure" 2 "No_Warning_Pressure" 1 "Over_Pressure" 0 "Extreme_Over_Pressure" ;
VAL_ 2566845491 CTIWheelSolenoidFault 3 "N/A" 2 "SolenoidFault" 1 "NotDefined" 0 "Ok" ;
VAL_ 2566845491 CTITireStatus 3 "N/A" 2 "TireBurst_SevereDamage" 1 "TireLeak_Compensable" 0 "Pressure_OK" ;
VAL_ 2566845491 CTIWheelValveMode 3 "N/A" 2 "WheeIsolated_FAULT" 1 "Open_OK" 0 "Closed_OK" ;
VAL_ 2566845491 TireLocation 49 "RearRight" 48 "RearLeft" 33 "SecondCentralRight" 32 "SecondCentralLeft" 17 "FirstCentralRight" 16 "FirstCentralLeft" 1 "FrontRight" 0 "FrontLeft" ;
VAL_ 2566840592 RetarderLocation 15 "NotAvailable" 14 "Other" 6 "1101NotDefined" 5 "Trailer" 4 "Driveline" 3 "TransOutput" 2 "TransInput" 1 "EngExhaustBrake" 0 "EngCompressionReleaseBrake" ;
VAL_ 2566840592 RetarderType 15 "NotAvailable" 14 "Other" 5 "1101NotDefined" 4 "Exhaust" 3 "CompressionRelease" 2 "CooledFriction" 1 "Hyd" 0 "Electric_Magnetic" ;
VAL_ 2566801923 TransMode1Indicator 3 "NotAvailable" 2 "Error" 1 "TransMode1Active" 0 "TransMode1NotActive" ;
VAL_ 2566801923 TransMode2Indicator 3 "NotAvailable" 2 "Error" 1 "TransMode2Active" 0 "TransMode2NotActive" ;
VAL_ 2566801923 TransMode3Indicator 3 "NotAvailable" 2 "Error" 1 "TransMode3Active" 0 "TransMode3NotActive" ;
VAL_ 2566801923 TransMode4Indicator 3 "NotAvailable" 2 "Error" 1 "TransMode4Active" 0 "TransMode4NotActive" ;
VAL_ 2566801923 TransShiftInhibitIndicator 3 "TakeNoAction" 2 "Reserved" 1 "ActiveShiftIsInhibited" 0 "InactiveShiftIsNotInhibited" ;
VAL_ 2566801923 TransEngCrankEnable 3 "NotAvailable" 2 "Error" 1 "CrnkngEnbldEngCrnkngIsAllwdByTr" 0 "CrnkngDsbldEngCrnkngIsPrhbtdByT" ;
VAL_ 2566801923 ActiveShiftConsoleIndicator 3 "NotAvailable" 2 "Reserved" 1 "SecondShiftConsoleIsActive" 0 "PrimaryShiftConsoleIsActive" ;
VAL_ 2566801923 TransReadyForBrakeRelease 3 "DontCare" 2 "Reserved" 1 "TransReadyForBrakeRelease" 0 "TransNotReadyForBrakeRelease" ;
VAL_ 2566801923 TransRqedRangeDisplayFlashState 3 "TakeNoAction" 2 "Reserved" 1 "ActvTrnsRqdRngDsplyShldBFlshing" 0 "InctvTrnsRqdRngDsplyShldNtBFlsh" ;
VAL_ 2566801923 TransRqedRangeDisplayBlankState 3 "TakeNoAction" 2 "Reserved" 1 "ActvTrnsRqdRngDsplyShldBBlanked" 0 "InctvTrnsRqdRngDsplyShldNtBBlnk" ;
VAL_ 2364539395 ProgressiveShiftDisable 2 "RESERVED" 3 "TAKE_NO_ACTION" 1 "P.SHIFT_DISABLED" 0 "P.SHIFT_NOT_DISABLED" ;
VAL_ 2364539395 EngMomentaryOverspeedEnable 2 "RESERVED" 3 "TAKE_NO_ACTION" 1 "OVERSPEED_ENABLED" 0 "OVERSPEED_DISABLED" ;
VAL_ 2364539395 TransmShiftInProcess 3 "NOT_AVAILABLE" 2 "ERROR" 1 "SHIFT_IN_PROCESS" 0 "SHIFT_NOT_IN_PROCESS" ;
VAL_ 2364539395 TorqueConverterLockupEngaged 3 "NOT_AVAILABLE" 2 "ERROR" 1 "Converter_Lockup_ENGAGED" 0 "Converter_Lockup_DISENGAGED" ;
VAL_ 2364539395 TransmDrivelineEngaged 3 "NOT_AVAILABLE" 2 "ERROR" 1 "DRIVELINE_ENGAGED" 0 "DRIVELINE_DISENGAGED" ;
VAL_ 2565865488 EngCoolantLoadIncrease 3 "NotAvailable" 2 "Error" 1 "CoolantLoadIncreasePossible" 0 "NoCoolantLoadIncrease" ;
VAL_ 2565865488 RetarderEnbShiftAssiSwitch 3 "NotAvailable" 2 "Error" 1 "RetarderShiftAssistEnabled" 0 "RetarderShiftAssistDisabled" ;
VAL_ 2565865488 RetarderEnbBrkAssiSwitch 3 "NotAvailable" 2 "Error" 1 "RetarderBrakeAssistEnabled" 0 "RetarderBrakeAssistDisabled" ;
VAL_ 2565865488 RetarderTorqueMode 15 "not_available" 14 "other" 13 "not_defined" 12 "not_defined" 11 "Remote_accelerator" 10 "Braking_system" 9 "High_speed_governor" 8 "Torque_limiting" 7 "ABS_control" 6 "Transmission_control" 5 "ASR_control" 4 "Road_speed_governor" 3 "PTO_governor" 2 "Cruise_control" 1 "Accelerator_pedal_/_operator_selection" 0 "Low_idle_governor_/_no_request_(default_mode)" ;
VAL_ 2364539648 AccelPedalKickdownSwitch 3 "NotAvailable" 2 "Error" 1 "KickdownActive" 0 "KickdownPassive" ;
VAL_ 2364539648 AccelPedal1LowIdleSwitch 3 "NotAvailable" 2 "Error" 1 "AccelPedal1InLowIdleCondition" 0 "AcclPedal1NotInLowIdleCondition" ;
VAL_ 2364539904 EngineStarterMode 15 "Notavailable" 14 "Error" 12 "StarterInibReasonUnknown" 7 "StarterInibImmobilizer" 6 "StarterInibDrivelineEngaged" 5 "StarterInibEngineNotReadyToStart" 4 "StarterInibitEngAlreadyRunning" 3 "StarterFinished" 2 "StarterActiveGearEngaged" 1 "StarterActiveGearNotEngaged" 0 "StartNotRequested" ;
VAL_ 2364539904 SrcAddrssOfCtrllngDvcForEngCtrl 0 "EDC" 39 "VCM" ;
VAL_ 2364539904 EngTorqueMode 15 "NotAvailable" 11 "RemoteAccelerator" 10 "BrakingSystem" 9 "HighSpeedGovernor" 8 "TorqueLimiting" 7 "ABSControl" 6 "TransmissionControl" 5 "ASRControl" 4 "RoadSpeedGovernor" 3 "PTOGovernor" 2 "CruiseControl" 1 "AcceleratorPedalOperSel" 0 "LowIdleGovernor" ;
VAL_ 2566841088 SupportTSC1CtrlPurposeGroup4Of4 1 "P25ReservedForAssignmentBySAE" ;
VAL_ 2566841088 SupportVariableRateTSC1Message 1 "MsTransRate" ;
VAL_ 2566841088 SupportTSC1CtrlPurposeGroup3Of4 1 "P17ReservedForAssignmentBySAE" ;
VAL_ 2566841088 SupportTSC1CtrlPurposeGroup2Of4 1 "P9ReservedForAssignmentBySAE" ;
VAL_ 2566841088 SupportTSC1CtrlPurposeGroup1Of4 1 "P1AccelPedal_OperatorSelection" ;
VAL_ 2566834944 MalfunctionIndicatorLampStatus 3 "NotAvailable" 2 "Reserved" 1 "LampOn" 0 "LampOff" ;
VAL_ 2566834944 AmberWarningLampStatus 3 "NotAvailable" 2 "Reserved" 1 "LampOn" 0 "LampOff" ;
VAL_ 2566834944 RedStopLampState 3 "NotAvailable" 2 "Reserved" 1 "LampOn" 0 "LampOff" ;
VAL_ 2566834944 FailureModeIdentifier9 31 "NotAvailable" 30 "NotAvailable" 29 "NotAvailable" 28 "NotAvailable" 27 "NotAvailable" 26 "NotAvailable" 25 "NotAvailable" 24 "NotAvailable" 23 "NotAvailable" 22 "NotAvailable" 21 "NotAvailable" 20 "NotAvailable" 19 "ReceivedNetworkDataInError" 18 "BelowNormalModeratelySevere" 17 "BelowNormalLeastSevere" 16 "AboveNormalModeratelySevere" 15 "AboveNormalLeastSevere" 14 "SpecialIntstructions" 13 "OutOfCalibration" 12 "BadIntelligentDevice" 11 "RootCauseNotKnown" 10 "AbnormalRateOfChange" 9 "AbnormalUpdateRate" 8 "AbnormalFrequency" 7 "MechanicalSystemNotResponding" 6 "CurrentAboveNormal" 5 "CurrentBelowNormal" 4 "VoltageBelowNormal" 3 "VoltageAboveNormal" 2 "DataErratic" 1 "BelowNormalMostSevere" 0 "AboveNormalMostSevere" ;
VAL_ 2566834944 FailureModeIdentifier8 31 "NotAvailable" 30 "NotAvailable" 29 "NotAvailable" 28 "NotAvailable" 27 "NotAvailable" 26 "NotAvailable" 25 "NotAvailable" 24 "NotAvailable" 23 "NotAvailable" 22 "NotAvailable" 21 "NotAvailable" 20 "NotAvailable" 19 "ReceivedNetworkDataInError" 18 "BelowNormalModeratelySevere" 17 "BelowNormalLeastSevere" 16 "AboveNormalModeratelySevere" 15 "AboveNormalLeastSevere" 14 "SpecialIntstructions" 13 "OutOfCalibration" 12 "BadIntelligentDevice" 11 "RootCauseNotKnown" 10 "AbnormalRateOfChange" 9 "AbnormalUpdateRate" 8 "AbnormalFrequency" 7 "MechanicalSystemNotResponding" 6 "CurrentAboveNormal" 5 "CurrentBelowNormal" 4 "VoltageBelowNormal" 3 "VoltageAboveNormal" 2 "DataErratic" 1 "BelowNormalMostSevere" 0 "AboveNormalMostSevere" ;
VAL_ 2566834944 FailureModeIdentifier7 31 "NotAvailable" 30 "NotAvailable" 29 "NotAvailable" 28 "NotAvailable" 27 "NotAvailable" 26 "NotAvailable" 25 "NotAvailable" 24 "NotAvailable" 23 "NotAvailable" 22 "NotAvailable" 21 "NotAvailable" 20 "NotAvailable" 19 "ReceivedNetworkDataInError" 18 "BelowNormalModeratelySevere" 17 "BelowNormalLeastSevere" 16 "AboveNormalModeratelySevere" 15 "AboveNormalLeastSevere" 14 "SpecialIntstructions" 13 "OutOfCalibration" 12 "BadIntelligentDevice" 11 "RootCauseNotKnown" 10 "AbnormalRateOfChange" 9 "AbnormalUpdateRate" 8 "AbnormalFrequency" 7 "MechanicalSystemNotResponding" 6 "CurrentAboveNormal" 5 "CurrentBelowNormal" 4 "VoltageBelowNormal" 3 "VoltageAboveNormal" 2 "DataErratic" 1 "BelowNormalMostSevere" 0 "AboveNormalMostSevere" ;
VAL_ 2566834944 FailureModeIdentifier6 31 "NotAvailable" 30 "NotAvailable" 29 "NotAvailable" 28 "NotAvailable" 27 "NotAvailable" 26 "NotAvailable" 25 "NotAvailable" 24 "NotAvailable" 23 "NotAvailable" 22 "NotAvailable" 21 "NotAvailable" 20 "NotAvailable" 19 "ReceivedNetworkDataInError" 18 "BelowNormalModeratelySevere" 17 "BelowNormalLeastSevere" 16 "AboveNormalModeratelySevere" 15 "AboveNormalLeastSevere" 14 "SpecialIntstructions" 13 "OutOfCalibration" 12 "BadIntelligentDevice" 11 "RootCauseNotKnown" 10 "AbnormalRateOfChange" 9 "AbnormalUpdateRate" 8 "AbnormalFrequency" 7 "MechanicalSystemNotResponding" 6 "CurrentAboveNormal" 5 "CurrentBelowNormal" 4 "VoltageBelowNormal" 3 "VoltageAboveNormal" 2 "DataErratic" 1 "BelowNormalMostSevere" 0 "AboveNormalMostSevere" ;
VAL_ 2566834944 FailureModeIdentifier5 31 "NotAvailable" 30 "NotAvailable" 29 "NotAvailable" 28 "NotAvailable" 27 "NotAvailable" 26 "NotAvailable" 25 "NotAvailable" 24 "NotAvailable" 23 "NotAvailable" 22 "NotAvailable" 21 "NotAvailable" 20 "NotAvailable" 19 "ReceivedNetworkDataInError" 18 "BelowNormalModeratelySevere" 17 "BelowNormalLeastSevere" 16 "AboveNormalModeratelySevere" 15 "AboveNormalLeastSevere" 14 "SpecialIntstructions" 13 "OutOfCalibration" 12 "BadIntelligentDevice" 11 "RootCauseNotKnown" 10 "AbnormalRateOfChange" 9 "AbnormalUpdateRate" 8 "AbnormalFrequency" 7 "MechanicalSystemNotResponding" 6 "CurrentAboveNormal" 5 "CurrentBelowNormal" 4 "VoltageBelowNormal" 3 "VoltageAboveNormal" 2 "DataErratic" 1 "BelowNormalMostSevere" 0 "AboveNormalMostSevere" ;
VAL_ 2566834944 FailureModeIdentifier4 31 "NotAvailable" 30 "NotAvailable" 29 "NotAvailable" 28 "NotAvailable" 27 "NotAvailable" 26 "NotAvailable" 25 "NotAvailable" 24 "NotAvailable" 23 "NotAvailable" 22 "NotAvailable" 21 "NotAvailable" 20 "NotAvailable" 19 "ReceivedNetworkDataInError" 18 "BelowNormalModeratelySevere" 17 "BelowNormalLeastSevere" 16 "AboveNormalModeratelySevere" 15 "AboveNormalLeastSevere" 14 "SpecialIntstructions" 13 "OutOfCalibration" 12 "BadIntelligentDevice" 11 "RootCauseNotKnown" 10 "AbnormalRateOfChange" 9 "AbnormalUpdateRate" 8 "AbnormalFrequency" 7 "MechanicalSystemNotResponding" 6 "CurrentAboveNormal" 5 "CurrentBelowNormal" 4 "VoltageBelowNormal" 3 "VoltageAboveNormal" 2 "DataErratic" 1 "BelowNormalMostSevere" 0 "AboveNormalMostSevere" ;
VAL_ 2566834944 FailureModeIdentifier3 31 "NotAvailable" 30 "NotAvailable" 29 "NotAvailable" 28 "NotAvailable" 27 "NotAvailable" 26 "NotAvailable" 25 "NotAvailable" 24 "NotAvailable" 23 "NotAvailable" 22 "NotAvailable" 21 "NotAvailable" 20 "NotAvailable" 19 "ReceivedNetworkDataInError" 18 "BelowNormalModeratelySevere" 17 "BelowNormalLeastSevere" 16 "AboveNormalModeratelySevere" 15 "AboveNormalLeastSevere" 14 "SpecialIntstructions" 13 "OutOfCalibration" 12 "BadIntelligentDevice" 11 "RootCauseNotKnown" 10 "AbnormalRateOfChange" 9 "AbnormalUpdateRate" 8 "AbnormalFrequency" 7 "MechanicalSystemNotResponding" 6 "CurrentAboveNormal" 5 "CurrentBelowNormal" 4 "VoltageBelowNormal" 3 "VoltageAboveNormal" 2 "DataErratic" 1 "BelowNormalMostSevere" 0 "AboveNormalMostSevere" ;
VAL_ 2566834944 FailureModeIdentifier2 31 "NotAvailable" 30 "NotAvailable" 29 "NotAvailable" 28 "NotAvailable" 27 "NotAvailable" 26 "NotAvailable" 25 "NotAvailable" 24 "NotAvailable" 23 "NotAvailable" 22 "NotAvailable" 21 "NotAvailable" 20 "NotAvailable" 19 "ReceivedNetworkDataInError" 18 "BelowNormalModeratelySevere" 17 "BelowNormalLeastSevere" 16 "AboveNormalModeratelySevere" 15 "AboveNormalLeastSevere" 14 "SpecialIntstructions" 13 "OutOfCalibration" 12 "BadIntelligentDevice" 11 "RootCauseNotKnown" 10 "AbnormalRateOfChange" 9 "AbnormalUpdateRate" 8 "AbnormalFrequency" 7 "MechanicalSystemNotResponding" 6 "CurrentAboveNormal" 5 "CurrentBelowNormal" 4 "VoltageBelowNormal" 3 "VoltageAboveNormal" 2 "DataErratic" 1 "BelowNormalMostSevere" 0 "AboveNormalMostSevere" ;
VAL_ 2566834944 FailureModeIdentifier10 31 "NotAvailable" 30 "NotAvailable" 29 "NotAvailable" 28 "NotAvailable" 27 "NotAvailable" 26 "NotAvailable" 25 "NotAvailable" 24 "NotAvailable" 23 "NotAvailable" 22 "NotAvailable" 21 "NotAvailable" 20 "NotAvailable" 19 "ReceivedNetworkDataInError" 18 "BelowNormalModeratelySevere" 17 "BelowNormalLeastSevere" 16 "AboveNormalModeratelySevere" 15 "AboveNormalLeastSevere" 14 "SpecialIntstructions" 13 "OutOfCalibration" 12 "BadIntelligentDevice" 11 "RootCauseNotKnown" 10 "AbnormalRateOfChange" 9 "AbnormalUpdateRate" 8 "AbnormalFrequency" 7 "MechanicalSystemNotResponding" 6 "CurrentAboveNormal" 5 "CurrentBelowNormal" 4 "VoltageBelowNormal" 3 "VoltageAboveNormal" 2 "DataErratic" 1 "BelowNormalMostSevere" 0 "AboveNormalMostSevere" ;
VAL_ 2566834944 FailureModeIdentifier1 31 "NotAvailable" 30 "NotAvailable" 29 "NotAvailable" 28 "NotAvailable" 27 "NotAvailable" 26 "NotAvailable" 25 "NotAvailable" 24 "NotAvailable" 23 "NotAvailable" 22 "NotAvailable" 21 "NotAvailable" 20 "NotAvailable" 19 "ReceivedNetworkDataInError" 18 "BelowNormalModeratelySevere" 17 "BelowNormalLeastSevere" 16 "AboveNormalModeratelySevere" 15 "AboveNormalLeastSevere" 14 "SpecialIntstructions" 13 "OutOfCalibration" 12 "BadIntelligentDevice" 11 "RootCauseNotKnown" 10 "AbnormalRateOfChange" 9 "AbnormalUpdateRate" 8 "AbnormalFrequency" 7 "MechanicalSystemNotResponding" 6 "CurrentAboveNormal" 5 "CurrentBelowNormal" 4 "VoltageBelowNormal" 3 "VoltageAboveNormal" 2 "DataErratic" 1 "BelowNormalMostSevere" 0 "AboveNormalMostSevere" ;
VAL_ 2566835456 FailureModeIdentifier9 31 "NotAvailable" 30 "NotAvailable" 29 "NotAvailable" 28 "NotAvailable" 27 "NotAvailable" 26 "NotAvailable" 25 "NotAvailable" 24 "NotAvailable" 23 "NotAvailable" 22 "NotAvailable" 21 "NotAvailable" 20 "NotAvailable" 19 "ReceivedNetworkDataInError" 18 "BelowNormalModeratelySevere" 17 "BelowNormalLeastSevere" 16 "AboveNormalModeratelySevere" 15 "AboveNormalLeastSevere" 14 "SpecialIntstructions" 13 "OutOfCalibration" 12 "BadIntelligentDevice" 11 "RootCauseNotKnown" 10 "AbnormalRateOfChange" 9 "AbnormalUpdateRate" 8 "AbnormalFrequency" 7 "MechanicalSystemNotResponding" 6 "CurrentAboveNormal" 5 "CurrentBelowNormal" 4 "VoltageBelowNormal" 3 "VoltageAboveNormal" 2 "DataErratic" 1 "BelowNormalMostSevere" 0 "AboveNormalMostSevere" ;
VAL_ 2566835456 FailureModeIdentifier8 31 "NotAvailable" 30 "NotAvailable" 29 "NotAvailable" 28 "NotAvailable" 27 "NotAvailable" 26 "NotAvailable" 25 "NotAvailable" 24 "NotAvailable" 23 "NotAvailable" 22 "NotAvailable" 21 "NotAvailable" 20 "NotAvailable" 19 "ReceivedNetworkDataInError" 18 "BelowNormalModeratelySevere" 17 "BelowNormalLeastSevere" 16 "AboveNormalModeratelySevere" 15 "AboveNormalLeastSevere" 14 "SpecialIntstructions" 13 "OutOfCalibration" 12 "BadIntelligentDevice" 11 "RootCauseNotKnown" 10 "AbnormalRateOfChange" 9 "AbnormalUpdateRate" 8 "AbnormalFrequency" 7 "MechanicalSystemNotResponding" 6 "CurrentAboveNormal" 5 "CurrentBelowNormal" 4 "VoltageBelowNormal" 3 "VoltageAboveNormal" 2 "DataErratic" 1 "BelowNormalMostSevere" 0 "AboveNormalMostSevere" ;
VAL_ 2566835456 FailureModeIdentifier7 31 "NotAvailable" 30 "NotAvailable" 29 "NotAvailable" 28 "NotAvailable" 27 "NotAvailable" 26 "NotAvailable" 25 "NotAvailable" 24 "NotAvailable" 23 "NotAvailable" 22 "NotAvailable" 21 "NotAvailable" 20 "NotAvailable" 19 "ReceivedNetworkDataInError" 18 "BelowNormalModeratelySevere" 17 "BelowNormalLeastSevere" 16 "AboveNormalModeratelySevere" 15 "AboveNormalLeastSevere" 14 "SpecialIntstructions" 13 "OutOfCalibration" 12 "BadIntelligentDevice" 11 "RootCauseNotKnown" 10 "AbnormalRateOfChange" 9 "AbnormalUpdateRate" 8 "AbnormalFrequency" 7 "MechanicalSystemNotResponding" 6 "CurrentAboveNormal" 5 "CurrentBelowNormal" 4 "VoltageBelowNormal" 3 "VoltageAboveNormal" 2 "DataErratic" 1 "BelowNormalMostSevere" 0 "AboveNormalMostSevere" ;
VAL_ 2566835456 FailureModeIdentifier6 31 "NotAvailable" 30 "NotAvailable" 29 "NotAvailable" 28 "NotAvailable" 27 "NotAvailable" 26 "NotAvailable" 25 "NotAvailable" 24 "NotAvailable" 23 "NotAvailable" 22 "NotAvailable" 21 "NotAvailable" 20 "NotAvailable" 19 "ReceivedNetworkDataInError" 18 "BelowNormalModeratelySevere" 17 "BelowNormalLeastSevere" 16 "AboveNormalModeratelySevere" 15 "AboveNormalLeastSevere" 14 "SpecialIntstructions" 13 "OutOfCalibration" 12 "BadIntelligentDevice" 11 "RootCauseNotKnown" 10 "AbnormalRateOfChange" 9 "AbnormalUpdateRate" 8 "AbnormalFrequency" 7 "MechanicalSystemNotResponding" 6 "CurrentAboveNormal" 5 "CurrentBelowNormal" 4 "VoltageBelowNormal" 3 "VoltageAboveNormal" 2 "DataErratic" 1 "BelowNormalMostSevere" 0 "AboveNormalMostSevere" ;
VAL_ 2566835456 FailureModeIdentifier5 31 "NotAvailable" 30 "NotAvailable" 29 "NotAvailable" 28 "NotAvailable" 27 "NotAvailable" 26 "NotAvailable" 25 "NotAvailable" 24 "NotAvailable" 23 "NotAvailable" 22 "NotAvailable" 21 "NotAvailable" 20 "NotAvailable" 19 "ReceivedNetworkDataInError" 18 "BelowNormalModeratelySevere" 17 "BelowNormalLeastSevere" 16 "AboveNormalModeratelySevere" 15 "AboveNormalLeastSevere" 14 "SpecialIntstructions" 13 "OutOfCalibration" 12 "BadIntelligentDevice" 11 "RootCauseNotKnown" 10 "AbnormalRateOfChange" 9 "AbnormalUpdateRate" 8 "AbnormalFrequency" 7 "MechanicalSystemNotResponding" 6 "CurrentAboveNormal" 5 "CurrentBelowNormal" 4 "VoltageBelowNormal" 3 "VoltageAboveNormal" 2 "DataErratic" 1 "BelowNormalMostSevere" 0 "AboveNormalMostSevere" ;
VAL_ 2566835456 FailureModeIdentifier4 31 "NotAvailable" 30 "NotAvailable" 29 "NotAvailable" 28 "NotAvailable" 27 "NotAvailable" 26 "NotAvailable" 25 "NotAvailable" 24 "NotAvailable" 23 "NotAvailable" 22 "NotAvailable" 21 "NotAvailable" 20 "NotAvailable" 19 "ReceivedNetworkDataInError" 18 "BelowNormalModeratelySevere" 17 "BelowNormalLeastSevere" 16 "AboveNormalModeratelySevere" 15 "AboveNormalLeastSevere" 14 "SpecialIntstructions" 13 "OutOfCalibration" 12 "BadIntelligentDevice" 11 "RootCauseNotKnown" 10 "AbnormalRateOfChange" 9 "AbnormalUpdateRate" 8 "AbnormalFrequency" 7 "MechanicalSystemNotResponding" 6 "CurrentAboveNormal" 5 "CurrentBelowNormal" 4 "VoltageBelowNormal" 3 "VoltageAboveNormal" 2 "DataErratic" 1 "BelowNormalMostSevere" 0 "AboveNormalMostSevere" ;
VAL_ 2566835456 FailureModeIdentifier3 31 "NotAvailable" 30 "NotAvailable" 29 "NotAvailable" 28 "NotAvailable" 27 "NotAvailable" 26 "NotAvailable" 25 "NotAvailable" 24 "NotAvailable" 23 "NotAvailable" 22 "NotAvailable" 21 "NotAvailable" 20 "NotAvailable" 19 "ReceivedNetworkDataInError" 18 "BelowNormalModeratelySevere" 17 "BelowNormalLeastSevere" 16 "AboveNormalModeratelySevere" 15 "AboveNormalLeastSevere" 14 "SpecialIntstructions" 13 "OutOfCalibration" 12 "BadIntelligentDevice" 11 "RootCauseNotKnown" 10 "AbnormalRateOfChange" 9 "AbnormalUpdateRate" 8 "AbnormalFrequency" 7 "MechanicalSystemNotResponding" 6 "CurrentAboveNormal" 5 "CurrentBelowNormal" 4 "VoltageBelowNormal" 3 "VoltageAboveNormal" 2 "DataErratic" 1 "BelowNormalMostSevere" 0 "AboveNormalMostSevere" ;
VAL_ 2566835456 FailureModeIdentifier2 31 "NotAvailable" 30 "NotAvailable" 29 "NotAvailable" 28 "NotAvailable" 27 "NotAvailable" 26 "NotAvailable" 25 "NotAvailable" 24 "NotAvailable" 23 "NotAvailable" 22 "NotAvailable" 21 "NotAvailable" 20 "NotAvailable" 19 "ReceivedNetworkDataInError" 18 "BelowNormalModeratelySevere" 17 "BelowNormalLeastSevere" 16 "AboveNormalModeratelySevere" 15 "AboveNormalLeastSevere" 14 "SpecialIntstructions" 13 "OutOfCalibration" 12 "BadIntelligentDevice" 11 "RootCauseNotKnown" 10 "AbnormalRateOfChange" 9 "AbnormalUpdateRate" 8 "AbnormalFrequency" 7 "MechanicalSystemNotResponding" 6 "CurrentAboveNormal" 5 "CurrentBelowNormal" 4 "VoltageBelowNormal" 3 "VoltageAboveNormal" 2 "DataErratic" 1 "BelowNormalMostSevere" 0 "AboveNormalMostSevere" ;
VAL_ 2566835456 FailureModeIdentifier10 31 "NotAvailable" 30 "NotAvailable" 29 "NotAvailable" 28 "NotAvailable" 27 "NotAvailable" 26 "NotAvailable" 25 "NotAvailable" 24 "NotAvailable" 23 "NotAvailable" 22 "NotAvailable" 21 "NotAvailable" 20 "NotAvailable" 19 "ReceivedNetworkDataInError" 18 "BelowNormalModeratelySevere" 17 "BelowNormalLeastSevere" 16 "AboveNormalModeratelySevere" 15 "AboveNormalLeastSevere" 14 "SpecialIntstructions" 13 "OutOfCalibration" 12 "BadIntelligentDevice" 11 "RootCauseNotKnown" 10 "AbnormalRateOfChange" 9 "AbnormalUpdateRate" 8 "AbnormalFrequency" 7 "MechanicalSystemNotResponding" 6 "CurrentAboveNormal" 5 "CurrentBelowNormal" 4 "VoltageBelowNormal" 3 "VoltageAboveNormal" 2 "DataErratic" 1 "BelowNormalMostSevere" 0 "AboveNormalMostSevere" ;
VAL_ 2566835456 FailureModeIdentifier1 31 "NotAvailable" 30 "NotAvailable" 29 "NotAvailable" 28 "NotAvailable" 27 "NotAvailable" 26 "NotAvailable" 25 "NotAvailable" 24 "NotAvailable" 23 "NotAvailable" 22 "NotAvailable" 21 "NotAvailable" 20 "NotAvailable" 19 "ReceivedNetworkDataInError" 18 "BelowNormalModeratelySevere" 17 "BelowNormalLeastSevere" 16 "AboveNormalModeratelySevere" 15 "AboveNormalLeastSevere" 14 "SpecialIntstructions" 13 "OutOfCalibration" 12 "BadIntelligentDevice" 11 "RootCauseNotKnown" 10 "AbnormalRateOfChange" 9 "AbnormalUpdateRate" 8 "AbnormalFrequency" 7 "MechanicalSystemNotResponding" 6 "CurrentAboveNormal" 5 "CurrentBelowNormal" 4 "VoltageBelowNormal" 3 "VoltageAboveNormal" 2 "DataErratic" 1 "BelowNormalMostSevere" 0 "AboveNormalMostSevere" ;
VAL_ 2566846467 TransOilLevelMeasSts 15 "Not_defined" 14 "Error" 13 "Conditions_not_valid" 12 "Not_defined" 11 "Not_defined" 10 "Not_defined" 9 "Not_defined" 8 "Engine_speed_too_high" 7 "Engine_speed_too_low" 6 "Vehcile_not_level" 5 "Outputshaft_speed_too_high" 4 "Temperature_too_high" 3 "Temperature_too_low" 2 "Transmission_in_gear" 1 "Settling_timer_still_counting" 0 "Cnd_valid_for_measurement" ;
VAL_ 2566873377 EngineShutdownSwitch 3 "NOT_AVAILABLE" 2 "ERROR" 1 "SHUTDOWN_REQUESTED" 0 "NOT_REQUESTED" ;
VAL_ 2566873377 ParkingBrakeSwitch_BC2EDC2 3 "N/A" 2 "Error" 1 "Actuated" 0 "Not_actuated" ;
VAL_ 2566844672 CruiseControlAccelerateSwitch 3 "N/A" 2 "Error" 1 "Accelerate_set" 0 "Accelerate_not_set" ;
VAL_ 2566844672 CruiseControlResumeSwitch 3 "N/A" 2 "Error" 1 "Resume_active" 0 "Resume_not_active" ;
VAL_ 2566844672 CruiseControlDecelerateSwt 3 "N/A" 2 "Error" 1 "Decelerate_active" 0 "Decelerate_not_active" ;
VAL_ 2566844672 CruiseControlSetSwitch 3 "N/A" 2 "Error" 1 "Set_active" 0 "Set_not_active" ;
VAL_ 2566844672 BrakeSwitch 3 "N/A" 2 "Error" 1 "Pedal_Pressed" 0 "Pedal_Released" ;
VAL_ 2566844672 CruiseControlEnableSwitch 3 "N/A" 2 "Error" 1 "Cruise_control_enabled" 0 "Cruise_control_disabled" ;
VAL_ 2566844672 CruiseControlActive 3 "N/A" 2 "Error" 1 "Cruise_Control_On" 0 "Cruise_Control_Off" ;
VAL_ 2566844672 ParkingBrakeSwitch_CCVS_EEC 3 "N/A" 2 "Error" 1 "Actuated" 0 "Not_actuated" ;
VAL_ 2566848256 WaterInFuelIndicator 3 "NotAvailable" 2 "Reserved" 1 "Yes" 0 "No" ;
VAL_ 2566754816 EmergencySwitchStatus 3 "Not_Available" 2 "Error" 1 "On" 0 "Off" ;
VAL_ 2566754816 EngineOperatingState 15 "Not_Available" 14 "Reserved" 13 "N/A" 12 "N/A" 11 "N/A" 10 "N/A" 9 "N/A" 8 "N/A" 7 "Post_Run" 6 "Engine_Stopping" 5 "Cool_Down" 4 "Running" 3 "Warm_Up" 2 "Starting" 1 "Pre_Start" 0 "Engine_Stopped" ;
VAL_ 2566841344 EngProtectSystHasShutdownEngine 1 "Yes" 0 "No" ;
VAL_ 2566841344 WaitToStartLamp 1 "On" 0 "Off" ;
VAL_ 2566857216 CloggedOilFilterStatus 3 "NotAvailable" 2 "Clogged_TorqueReduction" 1 "Clogged_NoTorqueReduction" 0 "Not_clogged" ;
VAL_ 2566857216 CloggedFuelFilterStatus 3 "NotAvailable" 2 "Clogged_TorqueReduction" 1 "Clogged_NoTorqueReduction" 0 "Not_clogged" ;
VAL_ 2566856960 ECMFuellingState 3 "Not_available" 2 "Reserved" 1 "Not_ready_to_inject" 0 "Ready_to_Inject" ;
VAL_ 2566856960 SpeedLimiterStatus 3 "2ndProgramVehSpeedLimReq" 2 "ProgramVehSpeedLimRequested" 1 "2ndVehSpeedLimRequested" 0 "NoSpeedLimRequested" ;
VAL_ 2566856960 EDCOperationalStatus 3 "OverrunMonitoringActv" 2 "DiagnosticTest" 1 "AfterrunDrive" 0 "NormalOperation" ;
VAL_ 2566856960 EngineDegradationLevel 17 "ColdStart_Perf_Lim" 16 "OBD/DEF_Perf_Lim_Stage_2" 9 "OBD/DEF_Perf_Lim_Stage_1" 4 "DegradationLevel4" 3 "DegradationLevel3" 2 "DegradationLevel2" 1 "DegradationLevel1" 0 "NoDegradation" ;
VAL_ 2566856960 EngineOilTemperatureHigh 3 "NotAvailable" 2 "Reserved" 1 "AboveOperatingRange" 0 "Normal" ;
VAL_ 2566856960 FuelFilterHeaterStatus 3 "NotAvailable" 2 "Reserved" 1 "On" 0 "Off" ;
VAL_ 2566856960 EngineOilPressureLow 3 "NotAvailable" 2 "Reseved" 1 "BelowOperatingRange" 0 "Normal" ;
VAL_ 2566856960 EngineOverTemperature 2 "Warning" 1 "PreWarning" 0 "NoWarning" ;
VAL_ 2566856960 EngineOverspeed 3 "NotAvailable" 2 "Reserved" 1 "AboveOperatingRange" 0 "Normal" ;
VAL_ 2566856960 ColdStartHeaterStatus 15 "NotUsed_-_Lamp_Off" 14 "NotUsed_-_Lamp_Off" 13 "NotUsed_-_Lamp_Off" 12 "NotUsed_-_Lamp_Off" 11 "NotUsed_-_Lamp_Off" 10 "NotUsed_-_Lamp_Off" 9 "NotUsed_-_Lamp_Off" 8 "TestOfGridHeaterVoltageInProgres_-_Lamp_Off" 7 "Initialization_-_Lamp_Off" 6 "PostHeating_-_Lamp_Off" 5 "CrankWithExtraHeating_-_Lamp_Off" 4 "CrankPhase_-_Lamp_Off" 3 "StandbyWithoutHeating_-_Lamp_Off" 2 "StanbyWithHeating_-_Lamp_Blink" 1 "PreHeatingPhase_-_Lamp_On" 0 "OffPhase_-_Lamp_Off" ;
VAL_ 2565406464 PGN 65228 "DM3Req" 65244 "IdleOperation" 65249 "EngineRetarderCfg" 65226 "DiagnosticMessage" 65251 "EngineConfig" 65257 "FuelConsumption" 65259 "ComponentID" 65242 "SW_ID" 65229 "DM4Req" 61184 "STOD" 65235 "DM11Req" 65520 "SecurityCheck" 65253 "EngHoursRevolutio" 65227 "DM2Req" ;
VAL_ 2565406464 Status 1 "Negative_Acknowledgement" 0 "Positive_Acknowledgement" ;
VAL_ 2566834721 byte_0 3 "NotAvailable" 2 "Reserved" 1 "LampOn" 0 "LampOff" ;
VAL_ 2566834942 FailureModeIdentifier10 31 "NotAvailable" 30 "NotAvailable" 29 "NotAvailable" 28 "NotAvailable" 27 "NotAvailable" 26 "NotAvailable" 25 "NotAvailable" 24 "NotAvailable" 23 "NotAvailable" 22 "NotAvailable" 21 "NotAvailable" 20 "NotAvailable" 19 "ReceivedNetworkDataInError" 18 "BelowNormalModeratelySevere" 17 "BelowNormalLeastSevere" 16 "AboveNormalModeratelySevere" 15 "AboveNormalLeastSevere" 14 "SpecialIntstructions" 13 "OutOfCalibration" 12 "BadIntelligentDevice" 11 "RootCauseNotKnown" 10 "AbnormalRateOfChange" 9 "AbnormalUpdateRate" 8 "AbnormalFrequency" 7 "MechanicalSystemNotResponding" 6 "CurrentAboveNormal" 5 "CurrentBelowNormal" 4 "VoltageBelowNormal" 3 "VoltageAboveNormal" 2 "DataErratic" 1 "BelowNormalMostSevere" 0 "AboveNormalMostSevere" ;
VAL_ 2566834942 FailureModeIdentifier9 31 "NotAvailable" 30 "NotAvailable" 29 "NotAvailable" 28 "NotAvailable" 27 "NotAvailable" 26 "NotAvailable" 25 "NotAvailable" 24 "NotAvailable" 23 "NotAvailable" 22 "NotAvailable" 21 "NotAvailable" 20 "NotAvailable" 19 "ReceivedNetworkDataInError" 18 "BelowNormalModeratelySevere" 17 "BelowNormalLeastSevere" 16 "AboveNormalModeratelySevere" 15 "AboveNormalLeastSevere" 14 "SpecialIntstructions" 13 "OutOfCalibration" 12 "BadIntelligentDevice" 11 "RootCauseNotKnown" 10 "AbnormalRateOfChange" 9 "AbnormalUpdateRate" 8 "AbnormalFrequency" 7 "MechanicalSystemNotResponding" 6 "CurrentAboveNormal" 5 "CurrentBelowNormal" 4 "VoltageBelowNormal" 3 "VoltageAboveNormal" 2 "DataErratic" 1 "BelowNormalMostSevere" 0 "AboveNormalMostSevere" ;
VAL_ 2566834942 FailureModeIdentifier8 31 "NotAvailable" 30 "NotAvailable" 29 "NotAvailable" 28 "NotAvailable" 27 "NotAvailable" 26 "NotAvailable" 25 "NotAvailable" 24 "NotAvailable" 23 "NotAvailable" 22 "NotAvailable" 21 "NotAvailable" 20 "NotAvailable" 19 "ReceivedNetworkDataInError" 18 "BelowNormalModeratelySevere" 17 "BelowNormalLeastSevere" 16 "AboveNormalModeratelySevere" 15 "AboveNormalLeastSevere" 14 "SpecialIntstructions" 13 "OutOfCalibration" 12 "BadIntelligentDevice" 11 "RootCauseNotKnown" 10 "AbnormalRateOfChange" 9 "AbnormalUpdateRate" 8 "AbnormalFrequency" 7 "MechanicalSystemNotResponding" 6 "CurrentAboveNormal" 5 "CurrentBelowNormal" 4 "VoltageBelowNormal" 3 "VoltageAboveNormal" 2 "DataErratic" 1 "BelowNormalMostSevere" 0 "AboveNormalMostSevere" ;
VAL_ 2566834942 FailureModeIdentifier7 31 "NotAvailable" 30 "NotAvailable" 29 "NotAvailable" 28 "NotAvailable" 27 "NotAvailable" 26 "NotAvailable" 25 "NotAvailable" 24 "NotAvailable" 23 "NotAvailable" 22 "NotAvailable" 21 "NotAvailable" 20 "NotAvailable" 19 "ReceivedNetworkDataInError" 18 "BelowNormalModeratelySevere" 17 "BelowNormalLeastSevere" 16 "AboveNormalModeratelySevere" 15 "AboveNormalLeastSevere" 14 "SpecialIntstructions" 13 "OutOfCalibration" 12 "BadIntelligentDevice" 11 "RootCauseNotKnown" 10 "AbnormalRateOfChange" 9 "AbnormalUpdateRate" 8 "AbnormalFrequency" 7 "MechanicalSystemNotResponding" 6 "CurrentAboveNormal" 5 "CurrentBelowNormal" 4 "VoltageBelowNormal" 3 "VoltageAboveNormal" 2 "DataErratic" 1 "BelowNormalMostSevere" 0 "AboveNormalMostSevere" ;
VAL_ 2566834942 FailureModeIdentifier6 31 "NotAvailable" 30 "NotAvailable" 29 "NotAvailable" 28 "NotAvailable" 27 "NotAvailable" 26 "NotAvailable" 25 "NotAvailable" 24 "NotAvailable" 23 "NotAvailable" 22 "NotAvailable" 21 "NotAvailable" 20 "NotAvailable" 19 "ReceivedNetworkDataInError" 18 "BelowNormalModeratelySevere" 17 "BelowNormalLeastSevere" 16 "AboveNormalModeratelySevere" 15 "AboveNormalLeastSevere" 14 "SpecialIntstructions" 13 "OutOfCalibration" 12 "BadIntelligentDevice" 11 "RootCauseNotKnown" 10 "AbnormalRateOfChange" 9 "AbnormalUpdateRate" 8 "AbnormalFrequency" 7 "MechanicalSystemNotResponding" 6 "CurrentAboveNormal" 5 "CurrentBelowNormal" 4 "VoltageBelowNormal" 3 "VoltageAboveNormal" 2 "DataErratic" 1 "BelowNormalMostSevere" 0 "AboveNormalMostSevere" ;
VAL_ 2566834942 FailureModeIdentifier5 31 "NotAvailable" 30 "NotAvailable" 29 "NotAvailable" 28 "NotAvailable" 27 "NotAvailable" 26 "NotAvailable" 25 "NotAvailable" 24 "NotAvailable" 23 "NotAvailable" 22 "NotAvailable" 21 "NotAvailable" 20 "NotAvailable" 19 "ReceivedNetworkDataInError" 18 "BelowNormalModeratelySevere" 17 "BelowNormalLeastSevere" 16 "AboveNormalModeratelySevere" 15 "AboveNormalLeastSevere" 14 "SpecialIntstructions" 13 "OutOfCalibration" 12 "BadIntelligentDevice" 11 "RootCauseNotKnown" 10 "AbnormalRateOfChange" 9 "AbnormalUpdateRate" 8 "AbnormalFrequency" 7 "MechanicalSystemNotResponding" 6 "CurrentAboveNormal" 5 "CurrentBelowNormal" 4 "VoltageBelowNormal" 3 "VoltageAboveNormal" 2 "DataErratic" 1 "BelowNormalMostSevere" 0 "AboveNormalMostSevere" ;
VAL_ 2566834942 FailureModeIdentifier4 31 "NotAvailable" 30 "NotAvailable" 29 "NotAvailable" 28 "NotAvailable" 27 "NotAvailable" 26 "NotAvailable" 25 "NotAvailable" 24 "NotAvailable" 23 "NotAvailable" 22 "NotAvailable" 21 "NotAvailable" 20 "NotAvailable" 19 "ReceivedNetworkDataInError" 18 "BelowNormalModeratelySevere" 17 "BelowNormalLeastSevere" 16 "AboveNormalModeratelySevere" 15 "AboveNormalLeastSevere" 14 "SpecialIntstructions" 13 "OutOfCalibration" 12 "BadIntelligentDevice" 11 "RootCauseNotKnown" 10 "AbnormalRateOfChange" 9 "AbnormalUpdateRate" 8 "AbnormalFrequency" 7 "MechanicalSystemNotResponding" 6 "CurrentAboveNormal" 5 "CurrentBelowNormal" 4 "VoltageBelowNormal" 3 "VoltageAboveNormal" 2 "DataErratic" 1 "BelowNormalMostSevere" 0 "AboveNormalMostSevere" ;
VAL_ 2566834942 FailureModeIdentifier3 31 "NotAvailable" 30 "NotAvailable" 29 "NotAvailable" 28 "NotAvailable" 27 "NotAvailable" 26 "NotAvailable" 25 "NotAvailable" 24 "NotAvailable" 23 "NotAvailable" 22 "NotAvailable" 21 "NotAvailable" 20 "NotAvailable" 19 "ReceivedNetworkDataInError" 18 "BelowNormalModeratelySevere" 17 "BelowNormalLeastSevere" 16 "AboveNormalModeratelySevere" 15 "AboveNormalLeastSevere" 14 "SpecialIntstructions" 13 "OutOfCalibration" 12 "BadIntelligentDevice" 11 "RootCauseNotKnown" 10 "AbnormalRateOfChange" 9 "AbnormalUpdateRate" 8 "AbnormalFrequency" 7 "MechanicalSystemNotResponding" 6 "CurrentAboveNormal" 5 "CurrentBelowNormal" 4 "VoltageBelowNormal" 3 "VoltageAboveNormal" 2 "DataErratic" 1 "BelowNormalMostSevere" 0 "AboveNormalMostSevere" ;
VAL_ 2566834942 FlashRedStopLamp 3 "UnavailableDoNotFlash" 2 "Reserved" 1 "FastFlash" 0 "SlowFlash" ;
VAL_ 2566834942 FlashProtectLamp 3 "UnavailableDoNotFlash" 2 "Reserved" 1 "FastFlash" 0 "SlowFlash" ;
VAL_ 2566834942 FlashMalfuncIndicatorLamp 3 "UnavailableDoNotFlash" 2 "Reserved" 1 "FastFlash" 0 "SlowFlash" ;
VAL_ 2566834942 FlashAmberWarningLamp 3 "UnavailableDoNotFlash" 2 "Reserved" 1 "FastFlash" 0 "SlowFlash" ;
VAL_ 2566834942 MalfunctionIndicatorLampStatus 3 "NotAvailable" 2 "Reserved" 1 "LampOn" 0 "LampOff" ;
VAL_ 2566834942 AmberWarningLampStatus 3 "NotAvailable" 2 "Reserved" 1 "LampOn" 0 "LampOff" ;
VAL_ 2566834942 SPNConversionMethod1 1 "Version_1_2_3_format" 0 "Old_conversion_method" ;
VAL_ 2566834942 FailureModeIdentifier1 31 "NotAvailable" 30 "NotAvailable" 29 "NotAvailable" 28 "NotAvailable" 27 "NotAvailable" 26 "NotAvailable" 25 "NotAvailable" 24 "NotAvailable" 23 "NotAvailable" 22 "NotAvailable" 21 "NotAvailable" 20 "NotAvailable" 19 "ReceivedNetworkDataInError" 18 "BelowNormalModeratelySevere" 17 "BelowNormalLeastSevere" 16 "AboveNormalModeratelySevere" 15 "AboveNormalLeastSevere" 14 "SpecialIntstructions" 13 "OutOfCalibration" 12 "BadIntelligentDevice" 11 "RootCauseNotKnown" 10 "AbnormalRateOfChange" 9 "AbnormalUpdateRate" 8 "AbnormalFrequency" 7 "MechanicalSystemNotResponding" 6 "CurrentAboveNormal" 5 "CurrentBelowNormal" 4 "VoltageBelowNormal" 3 "VoltageAboveNormal" 2 "DataErratic" 1 "BelowNormalMostSevere" 0 "AboveNormalMostSevere" ;
VAL_ 2566834942 RedStopLampState 3 "NotAvailable" 2 "Reserved" 1 "LampOn" 0 "LampOff" ;
VAL_ 2566834942 ProtectLampStatus 3 "NotAvailable" 2 "Reserved" 1 "LampOn" 0 "LampOff" ;
VAL_ 2566834942 FailureModeIdentifier2 31 "NotAvailable" 30 "NotAvailable" 29 "NotAvailable" 28 "NotAvailable" 27 "NotAvailable" 26 "NotAvailable" 25 "NotAvailable" 24 "NotAvailable" 23 "NotAvailable" 22 "NotAvailable" 21 "NotAvailable" 20 "NotAvailable" 19 "ReceivedNetworkDataInError" 18 "BelowNormalModeratelySevere" 17 "BelowNormalLeastSevere" 16 "AboveNormalModeratelySevere" 15 "AboveNormalLeastSevere" 14 "SpecialIntstructions" 13 "OutOfCalibration" 12 "BadIntelligentDevice" 11 "RootCauseNotKnown" 10 "AbnormalRateOfChange" 9 "AbnormalUpdateRate" 8 "AbnormalFrequency" 7 "MechanicalSystemNotResponding" 6 "CurrentAboveNormal" 5 "CurrentBelowNormal" 4 "VoltageBelowNormal" 3 "VoltageAboveNormal" 2 "DataErratic" 1 "BelowNormalMostSevere" 0 "AboveNormalMostSevere" ;
VAL_ 2566834942 SPNConversionMethod10 1 "Version_1_2_3_format" 0 "Old_conversion_method" ;
VAL_ 2566834942 SPNConversionMethod9 1 "Version_1_2_3_format" 0 "Old_conversion_method" ;
VAL_ 2566834942 SPNConversionMethod8 1 "Version_1_2_3_format" 0 "Old_conversion_method" ;
VAL_ 2566834942 SPNConversionMethod7 1 "Version_1_2_3_format" 0 "Old_conversion_method" ;
VAL_ 2566834942 SPNConversionMethod6 1 "Version_1_2_3_format" 0 "Old_conversion_method" ;
VAL_ 2566834942 SPNConversionMethod5 1 "Version_1_2_3_format" 0 "Old_conversion_method" ;
VAL_ 2566834942 SPNConversionMethod4 1 "Version_1_2_3_format" 0 "Old_conversion_method" ;
VAL_ 2566834942 SPNConversionMethod3 1 "Version_1_2_3_format" 0 "Old_conversion_method" ;
VAL_ 2566834942 SPNConversionMethod2 1 "Version_1_2_3_format" 0 "Old_conversion_method" ;
